VERSION "HINBNNNYYNNNYYNNNNNNNNNNNNYNNNYYYNNYNNNNNN/4//%%/4/'%**4NNN///"

NS_ :

BS_:

BU_: VirtualNMTMaster BMS_5_1 BMS_4_1 BMS_3_1 BMS_2_1 BMS_1_1 BMS_0_1 BMS_5_0 BMS_4_0 BMS_3_0 BMS_2_0 BMS_1_0 BMS_0_0 IMU PVC Thermocouple TMS MC

BO_ 1827 HBGuard_035: 1 BMS_5_1
 SG_ Toggle : 7|1@1+ (1,0) [0|0] "" Vector__XXX
 SG_ State : 0|7@1+ (1,0) [0|0] "" Vector__XXX

BO_ 1443 SSDO_035: 8 BMS_5_1
 SG_ SCS M : 5|3@1+ (1,0) [0|6] "" Vector__XXX

BO_ 1571 CSDO_035: 8 Vector__XXX
 SG_ CCS M : 5|3@1+ (1,0) [0|6] ""  BMS_5_1

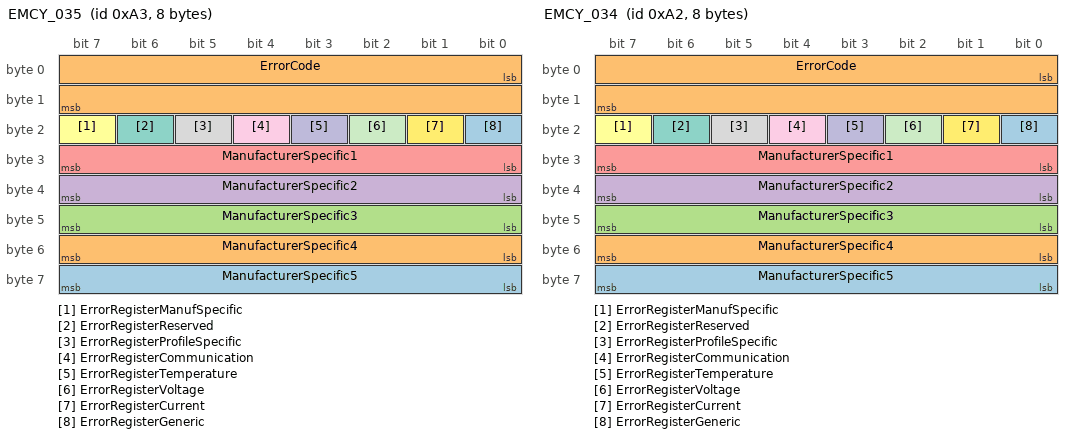
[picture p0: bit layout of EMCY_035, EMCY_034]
BO_ 163 EMCY_035: 8 BMS_5_1
 SG_ ManufacturerSpecific5 : 56|8@1+ (1,0) [0|0] "" Vector__XXX
 SG_ ManufacturerSpecific4 : 48|8@1+ (1,0) [0|0] "" Vector__XXX
 SG_ ManufacturerSpecific3 : 40|8@1+ (1,0) [0|0] "" Vector__XXX
 SG_ ManufacturerSpecific2 : 32|8@1+ (1,0) [0|0] "" Vector__XXX
 SG_ ManufacturerSpecific1 : 24|8@1+ (1,0) [0|0] "" Vector__XXX
 SG_ ErrorRegisterManufSpecific : 23|1@1+ (1,0) [0|0] "" Vector__XXX
 SG_ ErrorRegisterReserved : 22|1@1+ (1,0) [0|0] "" Vector__XXX
 SG_ ErrorRegisterProfileSpecific : 21|1@1+ (1,0) [0|0] "" Vector__XXX
 SG_ ErrorRegisterCommunication : 20|1@1+ (1,0) [0|0] "" Vector__XXX
 SG_ ErrorRegisterTemperature : 19|1@1+ (1,0) [0|0] "" Vector__XXX
 SG_ ErrorRegisterVoltage : 18|1@1+ (1,0) [0|0] "" Vector__XXX
 SG_ ErrorRegisterCurrent : 17|1@1+ (1,0) [0|0] "" Vector__XXX
 SG_ ErrorRegisterGeneric : 16|1@1+ (1,0) [0|0] "" Vector__XXX
 SG_ ErrorCode : 0|16@1+ (1,0) [0|0] "" Vector__XXX

BO_ 1826 HBGuard_034: 1 BMS_4_1
 SG_ Toggle : 7|1@1+ (1,0) [0|0] "" Vector__XXX
 SG_ State : 0|7@1+ (1,0) [0|0] "" Vector__XXX

BO_ 1442 SSDO_034: 8 BMS_4_1
 SG_ SCS M : 5|3@1+ (1,0) [0|6] "" Vector__XXX

BO_ 1570 CSDO_034: 8 Vector__XXX
 SG_ CCS M : 5|3@1+ (1,0) [0|6] ""  BMS_4_1

BO_ 162 EMCY_034: 8 BMS_4_1
 SG_ ManufacturerSpecific5 : 56|8@1+ (1,0) [0|0] "" Vector__XXX
 SG_ ManufacturerSpecific4 : 48|8@1+ (1,0) [0|0] "" Vector__XXX
 SG_ ManufacturerSpecific3 : 40|8@1+ (1,0) [0|0] "" Vector__XXX
 SG_ ManufacturerSpecific2 : 32|8@1+ (1,0) [0|0] "" Vector__XXX
 SG_ ManufacturerSpecific1 : 24|8@1+ (1,0) [0|0] "" Vector__XXX
 SG_ ErrorRegisterManufSpecific : 23|1@1+ (1,0) [0|0] "" Vector__XXX
 SG_ ErrorRegisterReserved : 22|1@1+ (1,0) [0|0] "" Vector__XXX
 SG_ ErrorRegisterProfileSpecific : 21|1@1+ (1,0) [0|0] "" Vector__XXX
 SG_ ErrorRegisterCommunication : 20|1@1+ (1,0) [0|0] "" Vector__XXX
 SG_ ErrorRegisterTemperature : 19|1@1+ (1,0) [0|0] "" Vector__XXX
 SG_ ErrorRegisterVoltage : 18|1@1+ (1,0) [0|0] "" Vector__XXX
 SG_ ErrorRegisterCurrent : 17|1@1+ (1,0) [0|0] "" Vector__XXX
 SG_ ErrorRegisterGeneric : 16|1@1+ (1,0) [0|0] "" Vector__XXX
 SG_ ErrorCode : 0|16@1+ (1,0) [0|0] "" Vector__XXX

BO_ 1825 HBGuard_033: 1 BMS_3_1
 SG_ Toggle : 7|1@1+ (1,0) [0|0] "" Vector__XXX
 SG_ State : 0|7@1+ (1,0) [0|0] "" Vector__XXX

BO_ 1441 SSDO_033: 8 BMS_3_1
 SG_ SCS M : 5|3@1+ (1,0) [0|6] "" Vector__XXX

BO_ 1569 CSDO_033: 8 Vector__XXX
 SG_ CCS M : 5|3@1+ (1,0) [0|6] ""  BMS_3_1

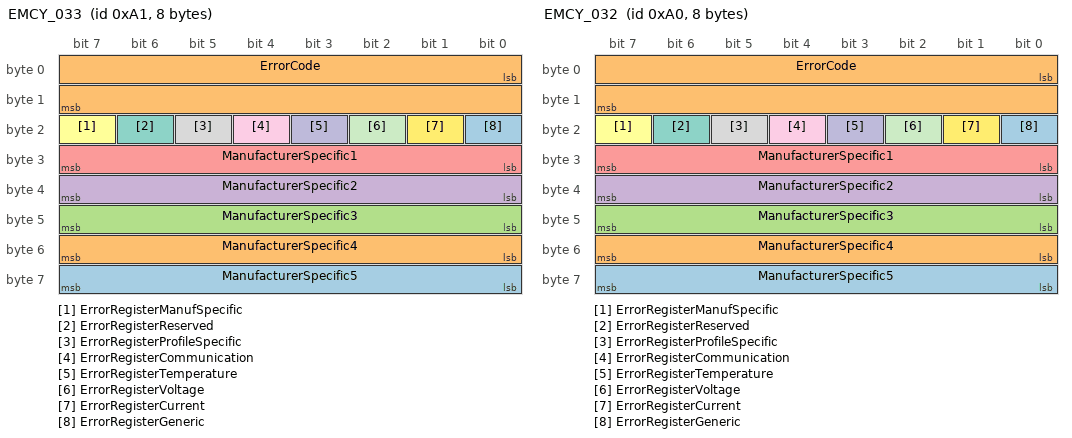
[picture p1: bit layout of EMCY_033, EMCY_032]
BO_ 161 EMCY_033: 8 BMS_3_1
 SG_ ManufacturerSpecific5 : 56|8@1+ (1,0) [0|0] "" Vector__XXX
 SG_ ManufacturerSpecific4 : 48|8@1+ (1,0) [0|0] "" Vector__XXX
 SG_ ManufacturerSpecific3 : 40|8@1+ (1,0) [0|0] "" Vector__XXX
 SG_ ManufacturerSpecific2 : 32|8@1+ (1,0) [0|0] "" Vector__XXX
 SG_ ManufacturerSpecific1 : 24|8@1+ (1,0) [0|0] "" Vector__XXX
 SG_ ErrorRegisterManufSpecific : 23|1@1+ (1,0) [0|0] "" Vector__XXX
 SG_ ErrorRegisterReserved : 22|1@1+ (1,0) [0|0] "" Vector__XXX
 SG_ ErrorRegisterProfileSpecific : 21|1@1+ (1,0) [0|0] "" Vector__XXX
 SG_ ErrorRegisterCommunication : 20|1@1+ (1,0) [0|0] "" Vector__XXX
 SG_ ErrorRegisterTemperature : 19|1@1+ (1,0) [0|0] "" Vector__XXX
 SG_ ErrorRegisterVoltage : 18|1@1+ (1,0) [0|0] "" Vector__XXX
 SG_ ErrorRegisterCurrent : 17|1@1+ (1,0) [0|0] "" Vector__XXX
 SG_ ErrorRegisterGeneric : 16|1@1+ (1,0) [0|0] "" Vector__XXX
 SG_ ErrorCode : 0|16@1+ (1,0) [0|0] "" Vector__XXX

BO_ 1824 HBGuard_032: 1 BMS_2_1
 SG_ Toggle : 7|1@1+ (1,0) [0|0] "" Vector__XXX
 SG_ State : 0|7@1+ (1,0) [0|0] "" Vector__XXX

BO_ 1440 SSDO_032: 8 BMS_2_1
 SG_ SCS M : 5|3@1+ (1,0) [0|6] "" Vector__XXX

BO_ 1568 CSDO_032: 8 Vector__XXX
 SG_ CCS M : 5|3@1+ (1,0) [0|6] ""  BMS_2_1

BO_ 160 EMCY_032: 8 BMS_2_1
 SG_ ManufacturerSpecific5 : 56|8@1+ (1,0) [0|0] "" Vector__XXX
 SG_ ManufacturerSpecific4 : 48|8@1+ (1,0) [0|0] "" Vector__XXX
 SG_ ManufacturerSpecific3 : 40|8@1+ (1,0) [0|0] "" Vector__XXX
 SG_ ManufacturerSpecific2 : 32|8@1+ (1,0) [0|0] "" Vector__XXX
 SG_ ManufacturerSpecific1 : 24|8@1+ (1,0) [0|0] "" Vector__XXX
 SG_ ErrorRegisterManufSpecific : 23|1@1+ (1,0) [0|0] "" Vector__XXX
 SG_ ErrorRegisterReserved : 22|1@1+ (1,0) [0|0] "" Vector__XXX
 SG_ ErrorRegisterProfileSpecific : 21|1@1+ (1,0) [0|0] "" Vector__XXX
 SG_ ErrorRegisterCommunication : 20|1@1+ (1,0) [0|0] "" Vector__XXX
 SG_ ErrorRegisterTemperature : 19|1@1+ (1,0) [0|0] "" Vector__XXX
 SG_ ErrorRegisterVoltage : 18|1@1+ (1,0) [0|0] "" Vector__XXX
 SG_ ErrorRegisterCurrent : 17|1@1+ (1,0) [0|0] "" Vector__XXX
 SG_ ErrorRegisterGeneric : 16|1@1+ (1,0) [0|0] "" Vector__XXX
 SG_ ErrorCode : 0|16@1+ (1,0) [0|0] "" Vector__XXX

BO_ 1823 HBGuard_031: 1 BMS_1_1
 SG_ Toggle : 7|1@1+ (1,0) [0|0] "" Vector__XXX
 SG_ State : 0|7@1+ (1,0) [0|0] "" Vector__XXX

BO_ 1439 SSDO_031: 8 BMS_1_1
 SG_ SCS M : 5|3@1+ (1,0) [0|6] "" Vector__XXX

BO_ 1567 CSDO_031: 8 Vector__XXX
 SG_ CCS M : 5|3@1+ (1,0) [0|6] ""  BMS_1_1

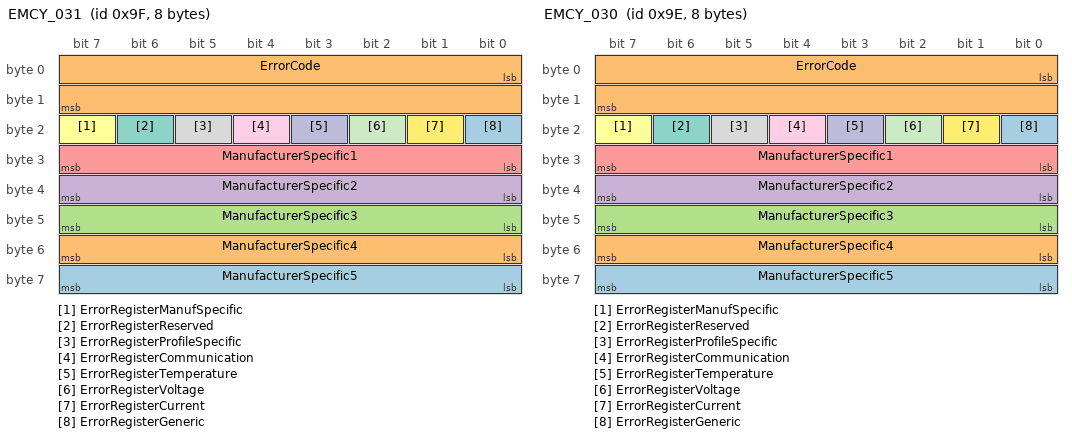
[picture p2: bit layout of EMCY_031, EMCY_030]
BO_ 159 EMCY_031: 8 BMS_1_1
 SG_ ManufacturerSpecific5 : 56|8@1+ (1,0) [0|0] "" Vector__XXX
 SG_ ManufacturerSpecific4 : 48|8@1+ (1,0) [0|0] "" Vector__XXX
 SG_ ManufacturerSpecific3 : 40|8@1+ (1,0) [0|0] "" Vector__XXX
 SG_ ManufacturerSpecific2 : 32|8@1+ (1,0) [0|0] "" Vector__XXX
 SG_ ManufacturerSpecific1 : 24|8@1+ (1,0) [0|0] "" Vector__XXX
 SG_ ErrorRegisterManufSpecific : 23|1@1+ (1,0) [0|0] "" Vector__XXX
 SG_ ErrorRegisterReserved : 22|1@1+ (1,0) [0|0] "" Vector__XXX
 SG_ ErrorRegisterProfileSpecific : 21|1@1+ (1,0) [0|0] "" Vector__XXX
 SG_ ErrorRegisterCommunication : 20|1@1+ (1,0) [0|0] "" Vector__XXX
 SG_ ErrorRegisterTemperature : 19|1@1+ (1,0) [0|0] "" Vector__XXX
 SG_ ErrorRegisterVoltage : 18|1@1+ (1,0) [0|0] "" Vector__XXX
 SG_ ErrorRegisterCurrent : 17|1@1+ (1,0) [0|0] "" Vector__XXX
 SG_ ErrorRegisterGeneric : 16|1@1+ (1,0) [0|0] "" Vector__XXX
 SG_ ErrorCode : 0|16@1+ (1,0) [0|0] "" Vector__XXX

BO_ 1822 HBGuard_030: 1 BMS_0_1
 SG_ Toggle : 7|1@1+ (1,0) [0|0] "" Vector__XXX
 SG_ State : 0|7@1+ (1,0) [0|0] "" Vector__XXX

BO_ 1438 SSDO_030: 8 BMS_0_1
 SG_ SCS M : 5|3@1+ (1,0) [0|6] "" Vector__XXX

BO_ 1566 CSDO_030: 8 Vector__XXX
 SG_ CCS M : 5|3@1+ (1,0) [0|6] ""  BMS_0_1

BO_ 158 EMCY_030: 8 BMS_0_1
 SG_ ManufacturerSpecific5 : 56|8@1+ (1,0) [0|0] "" Vector__XXX
 SG_ ManufacturerSpecific4 : 48|8@1+ (1,0) [0|0] "" Vector__XXX
 SG_ ManufacturerSpecific3 : 40|8@1+ (1,0) [0|0] "" Vector__XXX
 SG_ ManufacturerSpecific2 : 32|8@1+ (1,0) [0|0] "" Vector__XXX
 SG_ ManufacturerSpecific1 : 24|8@1+ (1,0) [0|0] "" Vector__XXX
 SG_ ErrorRegisterManufSpecific : 23|1@1+ (1,0) [0|0] "" Vector__XXX
 SG_ ErrorRegisterReserved : 22|1@1+ (1,0) [0|0] "" Vector__XXX
 SG_ ErrorRegisterProfileSpecific : 21|1@1+ (1,0) [0|0] "" Vector__XXX
 SG_ ErrorRegisterCommunication : 20|1@1+ (1,0) [0|0] "" Vector__XXX
 SG_ ErrorRegisterTemperature : 19|1@1+ (1,0) [0|0] "" Vector__XXX
 SG_ ErrorRegisterVoltage : 18|1@1+ (1,0) [0|0] "" Vector__XXX
 SG_ ErrorRegisterCurrent : 17|1@1+ (1,0) [0|0] "" Vector__XXX
 SG_ ErrorRegisterGeneric : 16|1@1+ (1,0) [0|0] "" Vector__XXX
 SG_ ErrorCode : 0|16@1+ (1,0) [0|0] "" Vector__XXX

BO_ 1817 HBGuard_025: 1 BMS_5_0
 SG_ Toggle : 7|1@1+ (1,0) [0|0] "" Vector__XXX
 SG_ State : 0|7@1+ (1,0) [0|0] "" Vector__XXX

BO_ 1433 SSDO_025: 8 BMS_5_0
 SG_ SCS M : 5|3@1+ (1,0) [0|6] "" Vector__XXX

BO_ 1561 CSDO_025: 8 Vector__XXX
 SG_ CCS M : 5|3@1+ (1,0) [0|6] ""  BMS_5_0

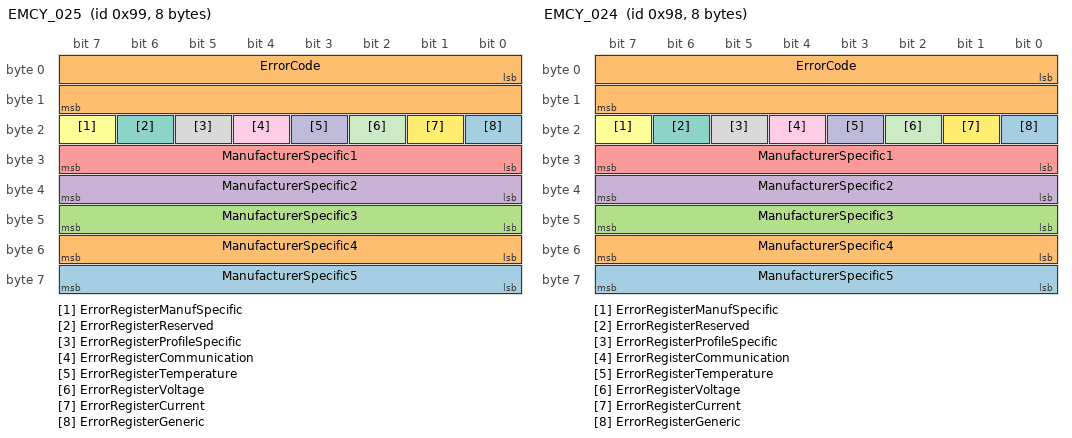
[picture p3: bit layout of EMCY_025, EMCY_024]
BO_ 153 EMCY_025: 8 BMS_5_0
 SG_ ManufacturerSpecific5 : 56|8@1+ (1,0) [0|0] "" Vector__XXX
 SG_ ManufacturerSpecific4 : 48|8@1+ (1,0) [0|0] "" Vector__XXX
 SG_ ManufacturerSpecific3 : 40|8@1+ (1,0) [0|0] "" Vector__XXX
 SG_ ManufacturerSpecific2 : 32|8@1+ (1,0) [0|0] "" Vector__XXX
 SG_ ManufacturerSpecific1 : 24|8@1+ (1,0) [0|0] "" Vector__XXX
 SG_ ErrorRegisterManufSpecific : 23|1@1+ (1,0) [0|0] "" Vector__XXX
 SG_ ErrorRegisterReserved : 22|1@1+ (1,0) [0|0] "" Vector__XXX
 SG_ ErrorRegisterProfileSpecific : 21|1@1+ (1,0) [0|0] "" Vector__XXX
 SG_ ErrorRegisterCommunication : 20|1@1+ (1,0) [0|0] "" Vector__XXX
 SG_ ErrorRegisterTemperature : 19|1@1+ (1,0) [0|0] "" Vector__XXX
 SG_ ErrorRegisterVoltage : 18|1@1+ (1,0) [0|0] "" Vector__XXX
 SG_ ErrorRegisterCurrent : 17|1@1+ (1,0) [0|0] "" Vector__XXX
 SG_ ErrorRegisterGeneric : 16|1@1+ (1,0) [0|0] "" Vector__XXX
 SG_ ErrorCode : 0|16@1+ (1,0) [0|0] "" Vector__XXX

BO_ 1816 HBGuard_024: 1 BMS_4_0
 SG_ Toggle : 7|1@1+ (1,0) [0|0] "" Vector__XXX
 SG_ State : 0|7@1+ (1,0) [0|0] "" Vector__XXX

BO_ 1432 SSDO_024: 8 BMS_4_0
 SG_ SCS M : 5|3@1+ (1,0) [0|6] "" Vector__XXX

BO_ 1560 CSDO_024: 8 Vector__XXX
 SG_ CCS M : 5|3@1+ (1,0) [0|6] ""  BMS_4_0

BO_ 152 EMCY_024: 8 BMS_4_0
 SG_ ManufacturerSpecific5 : 56|8@1+ (1,0) [0|0] "" Vector__XXX
 SG_ ManufacturerSpecific4 : 48|8@1+ (1,0) [0|0] "" Vector__XXX
 SG_ ManufacturerSpecific3 : 40|8@1+ (1,0) [0|0] "" Vector__XXX
 SG_ ManufacturerSpecific2 : 32|8@1+ (1,0) [0|0] "" Vector__XXX
 SG_ ManufacturerSpecific1 : 24|8@1+ (1,0) [0|0] "" Vector__XXX
 SG_ ErrorRegisterManufSpecific : 23|1@1+ (1,0) [0|0] "" Vector__XXX
 SG_ ErrorRegisterReserved : 22|1@1+ (1,0) [0|0] "" Vector__XXX
 SG_ ErrorRegisterProfileSpecific : 21|1@1+ (1,0) [0|0] "" Vector__XXX
 SG_ ErrorRegisterCommunication : 20|1@1+ (1,0) [0|0] "" Vector__XXX
 SG_ ErrorRegisterTemperature : 19|1@1+ (1,0) [0|0] "" Vector__XXX
 SG_ ErrorRegisterVoltage : 18|1@1+ (1,0) [0|0] "" Vector__XXX
 SG_ ErrorRegisterCurrent : 17|1@1+ (1,0) [0|0] "" Vector__XXX
 SG_ ErrorRegisterGeneric : 16|1@1+ (1,0) [0|0] "" Vector__XXX
 SG_ ErrorCode : 0|16@1+ (1,0) [0|0] "" Vector__XXX

BO_ 1815 HBGuard_023: 1 BMS_3_0
 SG_ Toggle : 7|1@1+ (1,0) [0|0] "" Vector__XXX
 SG_ State : 0|7@1+ (1,0) [0|0] "" Vector__XXX

BO_ 1431 SSDO_023: 8 BMS_3_0
 SG_ SCS M : 5|3@1+ (1,0) [0|6] "" Vector__XXX

BO_ 1559 CSDO_023: 8 Vector__XXX
 SG_ CCS M : 5|3@1+ (1,0) [0|6] ""  BMS_3_0

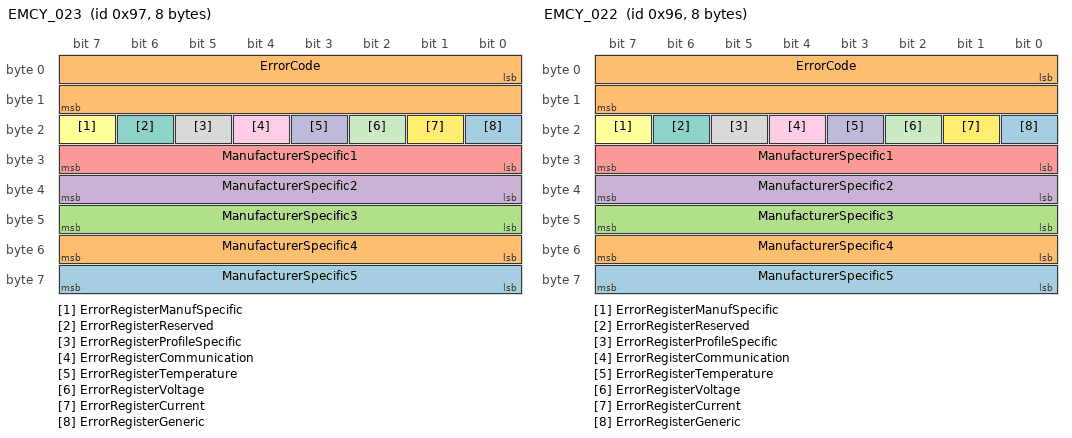
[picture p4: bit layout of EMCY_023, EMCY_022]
BO_ 151 EMCY_023: 8 BMS_3_0
 SG_ ManufacturerSpecific5 : 56|8@1+ (1,0) [0|0] "" Vector__XXX
 SG_ ManufacturerSpecific4 : 48|8@1+ (1,0) [0|0] "" Vector__XXX
 SG_ ManufacturerSpecific3 : 40|8@1+ (1,0) [0|0] "" Vector__XXX
 SG_ ManufacturerSpecific2 : 32|8@1+ (1,0) [0|0] "" Vector__XXX
 SG_ ManufacturerSpecific1 : 24|8@1+ (1,0) [0|0] "" Vector__XXX
 SG_ ErrorRegisterManufSpecific : 23|1@1+ (1,0) [0|0] "" Vector__XXX
 SG_ ErrorRegisterReserved : 22|1@1+ (1,0) [0|0] "" Vector__XXX
 SG_ ErrorRegisterProfileSpecific : 21|1@1+ (1,0) [0|0] "" Vector__XXX
 SG_ ErrorRegisterCommunication : 20|1@1+ (1,0) [0|0] "" Vector__XXX
 SG_ ErrorRegisterTemperature : 19|1@1+ (1,0) [0|0] "" Vector__XXX
 SG_ ErrorRegisterVoltage : 18|1@1+ (1,0) [0|0] "" Vector__XXX
 SG_ ErrorRegisterCurrent : 17|1@1+ (1,0) [0|0] "" Vector__XXX
 SG_ ErrorRegisterGeneric : 16|1@1+ (1,0) [0|0] "" Vector__XXX
 SG_ ErrorCode : 0|16@1+ (1,0) [0|0] "" Vector__XXX

BO_ 1814 HBGuard_022: 1 BMS_2_0
 SG_ Toggle : 7|1@1+ (1,0) [0|0] "" Vector__XXX
 SG_ State : 0|7@1+ (1,0) [0|0] "" Vector__XXX

BO_ 1430 SSDO_022: 8 BMS_2_0
 SG_ SCS M : 5|3@1+ (1,0) [0|6] "" Vector__XXX

BO_ 1558 CSDO_022: 8 Vector__XXX
 SG_ CCS M : 5|3@1+ (1,0) [0|6] ""  BMS_2_0

BO_ 150 EMCY_022: 8 BMS_2_0
 SG_ ManufacturerSpecific5 : 56|8@1+ (1,0) [0|0] "" Vector__XXX
 SG_ ManufacturerSpecific4 : 48|8@1+ (1,0) [0|0] "" Vector__XXX
 SG_ ManufacturerSpecific3 : 40|8@1+ (1,0) [0|0] "" Vector__XXX
 SG_ ManufacturerSpecific2 : 32|8@1+ (1,0) [0|0] "" Vector__XXX
 SG_ ManufacturerSpecific1 : 24|8@1+ (1,0) [0|0] "" Vector__XXX
 SG_ ErrorRegisterManufSpecific : 23|1@1+ (1,0) [0|0] "" Vector__XXX
 SG_ ErrorRegisterReserved : 22|1@1+ (1,0) [0|0] "" Vector__XXX
 SG_ ErrorRegisterProfileSpecific : 21|1@1+ (1,0) [0|0] "" Vector__XXX
 SG_ ErrorRegisterCommunication : 20|1@1+ (1,0) [0|0] "" Vector__XXX
 SG_ ErrorRegisterTemperature : 19|1@1+ (1,0) [0|0] "" Vector__XXX
 SG_ ErrorRegisterVoltage : 18|1@1+ (1,0) [0|0] "" Vector__XXX
 SG_ ErrorRegisterCurrent : 17|1@1+ (1,0) [0|0] "" Vector__XXX
 SG_ ErrorRegisterGeneric : 16|1@1+ (1,0) [0|0] "" Vector__XXX
 SG_ ErrorCode : 0|16@1+ (1,0) [0|0] "" Vector__XXX

BO_ 1813 HBGuard_021: 1 BMS_1_0
 SG_ Toggle : 7|1@1+ (1,0) [0|0] "" Vector__XXX
 SG_ State : 0|7@1+ (1,0) [0|0] "" Vector__XXX

BO_ 1429 SSDO_021: 8 BMS_1_0
 SG_ SCS M : 5|3@1+ (1,0) [0|6] "" Vector__XXX

BO_ 1557 CSDO_021: 8 Vector__XXX
 SG_ CCS M : 5|3@1+ (1,0) [0|6] ""  BMS_1_0

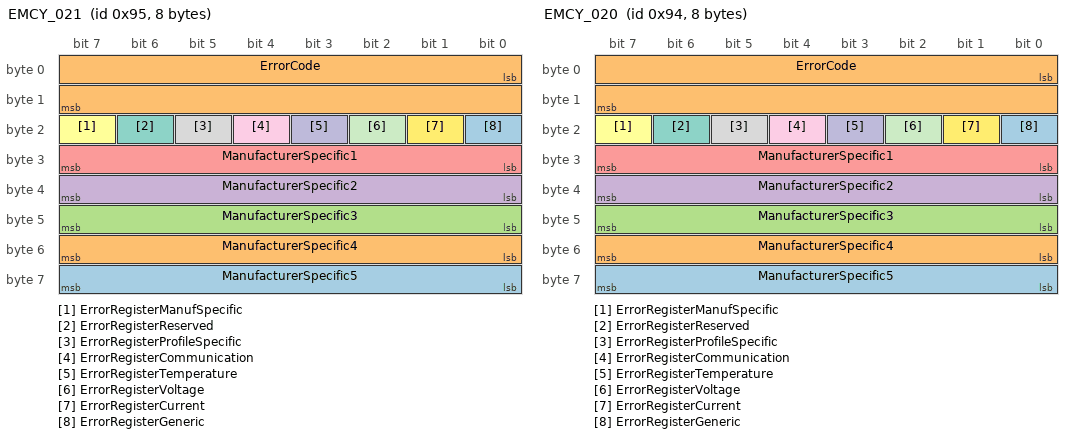
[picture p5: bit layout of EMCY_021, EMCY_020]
BO_ 149 EMCY_021: 8 BMS_1_0
 SG_ ManufacturerSpecific5 : 56|8@1+ (1,0) [0|0] "" Vector__XXX
 SG_ ManufacturerSpecific4 : 48|8@1+ (1,0) [0|0] "" Vector__XXX
 SG_ ManufacturerSpecific3 : 40|8@1+ (1,0) [0|0] "" Vector__XXX
 SG_ ManufacturerSpecific2 : 32|8@1+ (1,0) [0|0] "" Vector__XXX
 SG_ ManufacturerSpecific1 : 24|8@1+ (1,0) [0|0] "" Vector__XXX
 SG_ ErrorRegisterManufSpecific : 23|1@1+ (1,0) [0|0] "" Vector__XXX
 SG_ ErrorRegisterReserved : 22|1@1+ (1,0) [0|0] "" Vector__XXX
 SG_ ErrorRegisterProfileSpecific : 21|1@1+ (1,0) [0|0] "" Vector__XXX
 SG_ ErrorRegisterCommunication : 20|1@1+ (1,0) [0|0] "" Vector__XXX
 SG_ ErrorRegisterTemperature : 19|1@1+ (1,0) [0|0] "" Vector__XXX
 SG_ ErrorRegisterVoltage : 18|1@1+ (1,0) [0|0] "" Vector__XXX
 SG_ ErrorRegisterCurrent : 17|1@1+ (1,0) [0|0] "" Vector__XXX
 SG_ ErrorRegisterGeneric : 16|1@1+ (1,0) [0|0] "" Vector__XXX
 SG_ ErrorCode : 0|16@1+ (1,0) [0|0] "" Vector__XXX

BO_ 1812 HBGuard_020: 1 BMS_0_0
 SG_ Toggle : 7|1@1+ (1,0) [0|0] "" Vector__XXX
 SG_ State : 0|7@1+ (1,0) [0|0] "" Vector__XXX

BO_ 1428 SSDO_020: 8 BMS_0_0
 SG_ SCS M : 5|3@1+ (1,0) [0|6] "" Vector__XXX

BO_ 1556 CSDO_020: 8 Vector__XXX
 SG_ CCS M : 5|3@1+ (1,0) [0|6] ""  BMS_0_0

BO_ 148 EMCY_020: 8 BMS_0_0
 SG_ ManufacturerSpecific5 : 56|8@1+ (1,0) [0|0] "" Vector__XXX
 SG_ ManufacturerSpecific4 : 48|8@1+ (1,0) [0|0] "" Vector__XXX
 SG_ ManufacturerSpecific3 : 40|8@1+ (1,0) [0|0] "" Vector__XXX
 SG_ ManufacturerSpecific2 : 32|8@1+ (1,0) [0|0] "" Vector__XXX
 SG_ ManufacturerSpecific1 : 24|8@1+ (1,0) [0|0] "" Vector__XXX
 SG_ ErrorRegisterManufSpecific : 23|1@1+ (1,0) [0|0] "" Vector__XXX
 SG_ ErrorRegisterReserved : 22|1@1+ (1,0) [0|0] "" Vector__XXX
 SG_ ErrorRegisterProfileSpecific : 21|1@1+ (1,0) [0|0] "" Vector__XXX
 SG_ ErrorRegisterCommunication : 20|1@1+ (1,0) [0|0] "" Vector__XXX
 SG_ ErrorRegisterTemperature : 19|1@1+ (1,0) [0|0] "" Vector__XXX
 SG_ ErrorRegisterVoltage : 18|1@1+ (1,0) [0|0] "" Vector__XXX
 SG_ ErrorRegisterCurrent : 17|1@1+ (1,0) [0|0] "" Vector__XXX
 SG_ ErrorRegisterGeneric : 16|1@1+ (1,0) [0|0] "" Vector__XXX
 SG_ ErrorCode : 0|16@1+ (1,0) [0|0] "" Vector__XXX

BO_ 1809 HBGuard_017: 1 IMU
 SG_ Toggle : 7|1@1+ (1,0) [0|0] "" Vector__XXX
 SG_ State : 0|7@1+ (1,0) [0|0] "" Vector__XXX

BO_ 1425 SSDO_017: 8 IMU
 SG_ SCS M : 5|3@1+ (1,0) [0|6] "" Vector__XXX

BO_ 1553 CSDO_017: 8 Vector__XXX
 SG_ CCS M : 5|3@1+ (1,0) [0|6] ""  IMU

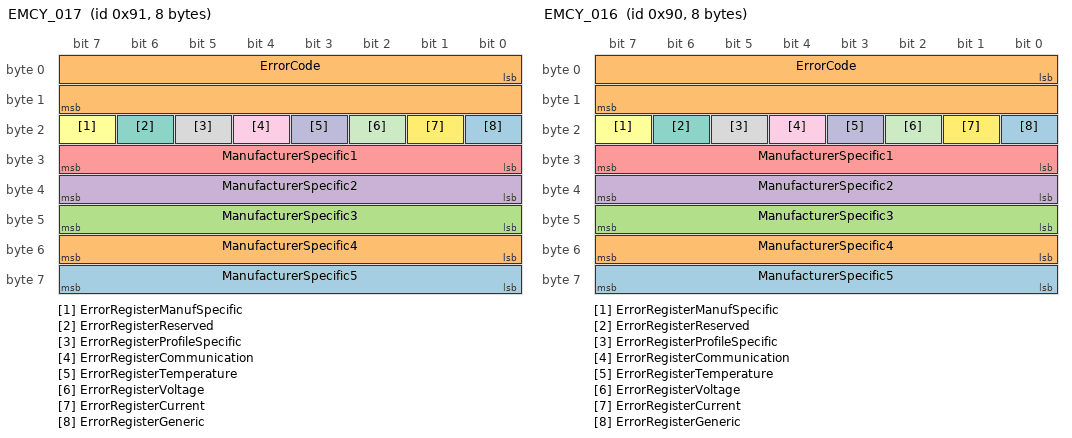
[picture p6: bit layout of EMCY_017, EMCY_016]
BO_ 145 EMCY_017: 8 IMU
 SG_ ManufacturerSpecific5 : 56|8@1+ (1,0) [0|0] "" Vector__XXX
 SG_ ManufacturerSpecific4 : 48|8@1+ (1,0) [0|0] "" Vector__XXX
 SG_ ManufacturerSpecific3 : 40|8@1+ (1,0) [0|0] "" Vector__XXX
 SG_ ManufacturerSpecific2 : 32|8@1+ (1,0) [0|0] "" Vector__XXX
 SG_ ManufacturerSpecific1 : 24|8@1+ (1,0) [0|0] "" Vector__XXX
 SG_ ErrorRegisterManufSpecific : 23|1@1+ (1,0) [0|0] "" Vector__XXX
 SG_ ErrorRegisterReserved : 22|1@1+ (1,0) [0|0] "" Vector__XXX
 SG_ ErrorRegisterProfileSpecific : 21|1@1+ (1,0) [0|0] "" Vector__XXX
 SG_ ErrorRegisterCommunication : 20|1@1+ (1,0) [0|0] "" Vector__XXX
 SG_ ErrorRegisterTemperature : 19|1@1+ (1,0) [0|0] "" Vector__XXX
 SG_ ErrorRegisterVoltage : 18|1@1+ (1,0) [0|0] "" Vector__XXX
 SG_ ErrorRegisterCurrent : 17|1@1+ (1,0) [0|0] "" Vector__XXX
 SG_ ErrorRegisterGeneric : 16|1@1+ (1,0) [0|0] "" Vector__XXX
 SG_ ErrorCode : 0|16@1+ (1,0) [0|0] "" Vector__XXX

BO_ 1808 HBGuard_016: 1 PVC
 SG_ Toggle : 7|1@1+ (1,0) [0|0] "" Vector__XXX
 SG_ State : 0|7@1+ (1,0) [0|0] "" Vector__XXX

BO_ 1424 SSDO_016: 8 PVC
 SG_ SCS M : 5|3@1+ (1,0) [0|6] "" Vector__XXX

BO_ 1552 CSDO_016: 8 Vector__XXX
 SG_ CCS M : 5|3@1+ (1,0) [0|6] ""  PVC

BO_ 144 EMCY_016: 8 PVC
 SG_ ManufacturerSpecific5 : 56|8@1+ (1,0) [0|0] "" Vector__XXX
 SG_ ManufacturerSpecific4 : 48|8@1+ (1,0) [0|0] "" Vector__XXX
 SG_ ManufacturerSpecific3 : 40|8@1+ (1,0) [0|0] "" Vector__XXX
 SG_ ManufacturerSpecific2 : 32|8@1+ (1,0) [0|0] "" Vector__XXX
 SG_ ManufacturerSpecific1 : 24|8@1+ (1,0) [0|0] "" Vector__XXX
 SG_ ErrorRegisterManufSpecific : 23|1@1+ (1,0) [0|0] "" Vector__XXX
 SG_ ErrorRegisterReserved : 22|1@1+ (1,0) [0|0] "" Vector__XXX
 SG_ ErrorRegisterProfileSpecific : 21|1@1+ (1,0) [0|0] "" Vector__XXX
 SG_ ErrorRegisterCommunication : 20|1@1+ (1,0) [0|0] "" Vector__XXX
 SG_ ErrorRegisterTemperature : 19|1@1+ (1,0) [0|0] "" Vector__XXX
 SG_ ErrorRegisterVoltage : 18|1@1+ (1,0) [0|0] "" Vector__XXX
 SG_ ErrorRegisterCurrent : 17|1@1+ (1,0) [0|0] "" Vector__XXX
 SG_ ErrorRegisterGeneric : 16|1@1+ (1,0) [0|0] "" Vector__XXX
 SG_ ErrorCode : 0|16@1+ (1,0) [0|0] "" Vector__XXX

BO_ 1801 HBGuard_009: 1 Thermocouple
 SG_ Toggle : 7|1@1+ (1,0) [0|0] "" Vector__XXX
 SG_ State : 0|7@1+ (1,0) [0|0] "" Vector__XXX

BO_ 1417 SSDO_009: 8 Thermocouple
 SG_ SCS M : 5|3@1+ (1,0) [0|6] "" Vector__XXX

BO_ 1545 CSDO_009: 8 Vector__XXX
 SG_ CCS M : 5|3@1+ (1,0) [0|6] ""  Thermocouple

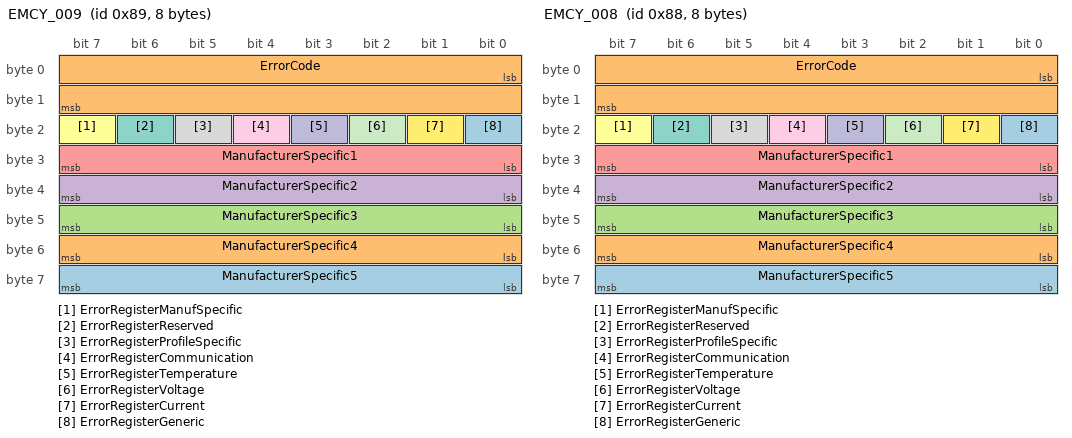
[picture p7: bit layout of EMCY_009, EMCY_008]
BO_ 137 EMCY_009: 8 Thermocouple
 SG_ ManufacturerSpecific5 : 56|8@1+ (1,0) [0|0] "" Vector__XXX
 SG_ ManufacturerSpecific4 : 48|8@1+ (1,0) [0|0] "" Vector__XXX
 SG_ ManufacturerSpecific3 : 40|8@1+ (1,0) [0|0] "" Vector__XXX
 SG_ ManufacturerSpecific2 : 32|8@1+ (1,0) [0|0] "" Vector__XXX
 SG_ ManufacturerSpecific1 : 24|8@1+ (1,0) [0|0] "" Vector__XXX
 SG_ ErrorRegisterManufSpecific : 23|1@1+ (1,0) [0|0] "" Vector__XXX
 SG_ ErrorRegisterReserved : 22|1@1+ (1,0) [0|0] "" Vector__XXX
 SG_ ErrorRegisterProfileSpecific : 21|1@1+ (1,0) [0|0] "" Vector__XXX
 SG_ ErrorRegisterCommunication : 20|1@1+ (1,0) [0|0] "" Vector__XXX
 SG_ ErrorRegisterTemperature : 19|1@1+ (1,0) [0|0] "" Vector__XXX
 SG_ ErrorRegisterVoltage : 18|1@1+ (1,0) [0|0] "" Vector__XXX
 SG_ ErrorRegisterCurrent : 17|1@1+ (1,0) [0|0] "" Vector__XXX
 SG_ ErrorRegisterGeneric : 16|1@1+ (1,0) [0|0] "" Vector__XXX
 SG_ ErrorCode : 0|16@1+ (1,0) [0|0] "" Vector__XXX

BO_ 1800 HBGuard_008: 1 TMS
 SG_ Toggle : 7|1@1+ (1,0) [0|0] "" Vector__XXX
 SG_ State : 0|7@1+ (1,0) [0|0] "" Vector__XXX

BO_ 1416 SSDO_008: 8 TMS
 SG_ SCS M : 5|3@1+ (1,0) [0|6] "" Vector__XXX

BO_ 1544 CSDO_008: 8 Vector__XXX
 SG_ CCS M : 5|3@1+ (1,0) [0|6] ""  TMS

BO_ 136 EMCY_008: 8 TMS
 SG_ ManufacturerSpecific5 : 56|8@1+ (1,0) [0|0] "" Vector__XXX
 SG_ ManufacturerSpecific4 : 48|8@1+ (1,0) [0|0] "" Vector__XXX
 SG_ ManufacturerSpecific3 : 40|8@1+ (1,0) [0|0] "" Vector__XXX
 SG_ ManufacturerSpecific2 : 32|8@1+ (1,0) [0|0] "" Vector__XXX
 SG_ ManufacturerSpecific1 : 24|8@1+ (1,0) [0|0] "" Vector__XXX
 SG_ ErrorRegisterManufSpecific : 23|1@1+ (1,0) [0|0] "" Vector__XXX
 SG_ ErrorRegisterReserved : 22|1@1+ (1,0) [0|0] "" Vector__XXX
 SG_ ErrorRegisterProfileSpecific : 21|1@1+ (1,0) [0|0] "" Vector__XXX
 SG_ ErrorRegisterCommunication : 20|1@1+ (1,0) [0|0] "" Vector__XXX
 SG_ ErrorRegisterTemperature : 19|1@1+ (1,0) [0|0] "" Vector__XXX
 SG_ ErrorRegisterVoltage : 18|1@1+ (1,0) [0|0] "" Vector__XXX
 SG_ ErrorRegisterCurrent : 17|1@1+ (1,0) [0|0] "" Vector__XXX
 SG_ ErrorRegisterGeneric : 16|1@1+ (1,0) [0|0] "" Vector__XXX
 SG_ ErrorCode : 0|16@1+ (1,0) [0|0] "" Vector__XXX

BO_ 1793 HBGuard_001: 1 MC
 SG_ Toggle : 7|1@1+ (1,0) [0|0] "" Vector__XXX
 SG_ State : 0|7@1+ (1,0) [0|0] "" Vector__XXX

BO_ 1409 SSDO_001: 8 MC
 SG_ SCS M : 5|3@1+ (1,0) [0|6] "" Vector__XXX

BO_ 1537 CSDO_001: 8 Vector__XXX
 SG_ CCS M : 5|3@1+ (1,0) [0|6] ""  MC

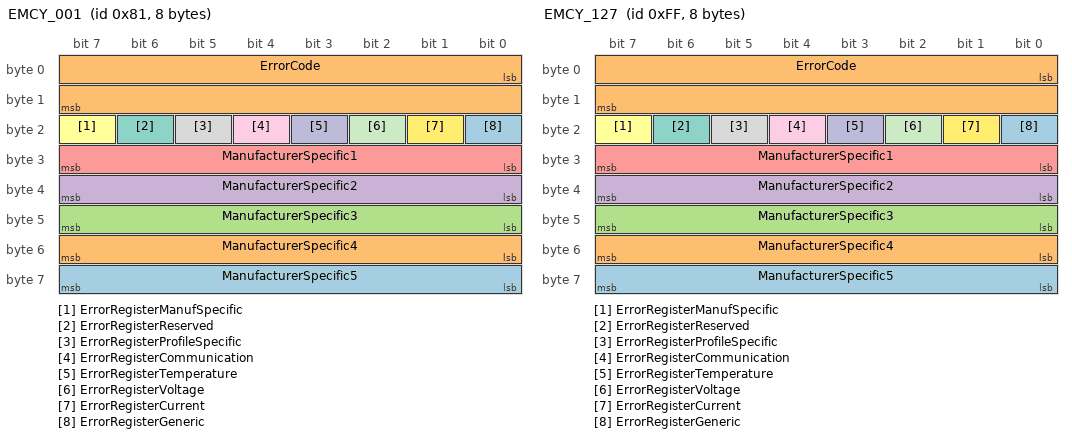
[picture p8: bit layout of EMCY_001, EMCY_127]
BO_ 129 EMCY_001: 8 MC
 SG_ ManufacturerSpecific5 : 56|8@1+ (1,0) [0|0] "" Vector__XXX
 SG_ ManufacturerSpecific4 : 48|8@1+ (1,0) [0|0] "" Vector__XXX
 SG_ ManufacturerSpecific3 : 40|8@1+ (1,0) [0|0] "" Vector__XXX
 SG_ ManufacturerSpecific2 : 32|8@1+ (1,0) [0|0] "" Vector__XXX
 SG_ ManufacturerSpecific1 : 24|8@1+ (1,0) [0|0] "" Vector__XXX
 SG_ ErrorRegisterManufSpecific : 23|1@1+ (1,0) [0|0] "" Vector__XXX
 SG_ ErrorRegisterReserved : 22|1@1+ (1,0) [0|0] "" Vector__XXX
 SG_ ErrorRegisterProfileSpecific : 21|1@1+ (1,0) [0|0] "" Vector__XXX
 SG_ ErrorRegisterCommunication : 20|1@1+ (1,0) [0|0] "" Vector__XXX
 SG_ ErrorRegisterTemperature : 19|1@1+ (1,0) [0|0] "" Vector__XXX
 SG_ ErrorRegisterVoltage : 18|1@1+ (1,0) [0|0] "" Vector__XXX
 SG_ ErrorRegisterCurrent : 17|1@1+ (1,0) [0|0] "" Vector__XXX
 SG_ ErrorRegisterGeneric : 16|1@1+ (1,0) [0|0] "" Vector__XXX
 SG_ ErrorCode : 0|16@1+ (1,0) [0|0] "" Vector__XXX

BO_ 1919 HBGuard_127: 1 Vector__XXX
 SG_ Toggle : 7|1@1+ (1,0) [0|0] "" Vector__XXX
 SG_ State : 0|7@1+ (1,0) [0|0] "" Vector__XXX

BO_ 1535 SSDO_127: 8 Vector__XXX

BO_ 1663 CSDO_127: 8 Vector__XXX

BO_ 255 EMCY_127: 8 Vector__XXX
 SG_ ManufacturerSpecific5 : 56|8@1+ (1,0) [0|0] "" Vector__XXX
 SG_ ManufacturerSpecific4 : 48|8@1+ (1,0) [0|0] "" Vector__XXX
 SG_ ManufacturerSpecific3 : 40|8@1+ (1,0) [0|0] "" Vector__XXX
 SG_ ManufacturerSpecific2 : 32|8@1+ (1,0) [0|0] "" Vector__XXX
 SG_ ManufacturerSpecific1 : 24|8@1+ (1,0) [0|0] "" Vector__XXX
 SG_ ErrorRegisterManufSpecific : 23|1@1+ (1,0) [0|0] "" Vector__XXX
 SG_ ErrorRegisterReserved : 22|1@1+ (1,0) [0|0] "" Vector__XXX
 SG_ ErrorRegisterProfileSpecific : 21|1@1+ (1,0) [0|0] "" Vector__XXX
 SG_ ErrorRegisterCommunication : 20|1@1+ (1,0) [0|0] "" Vector__XXX
 SG_ ErrorRegisterTemperature : 19|1@1+ (1,0) [0|0] "" Vector__XXX
 SG_ ErrorRegisterVoltage : 18|1@1+ (1,0) [0|0] "" Vector__XXX
 SG_ ErrorRegisterCurrent : 17|1@1+ (1,0) [0|0] "" Vector__XXX
 SG_ ErrorRegisterGeneric : 16|1@1+ (1,0) [0|0] "" Vector__XXX
 SG_ ErrorCode : 0|16@1+ (1,0) [0|0] "" Vector__XXX

BO_ 1918 HBGuard_126: 1 Vector__XXX
 SG_ Toggle : 7|1@1+ (1,0) [0|0] "" Vector__XXX
 SG_ State : 0|7@1+ (1,0) [0|0] "" Vector__XXX

BO_ 1534 SSDO_126: 8 Vector__XXX

BO_ 1662 CSDO_126: 8 Vector__XXX

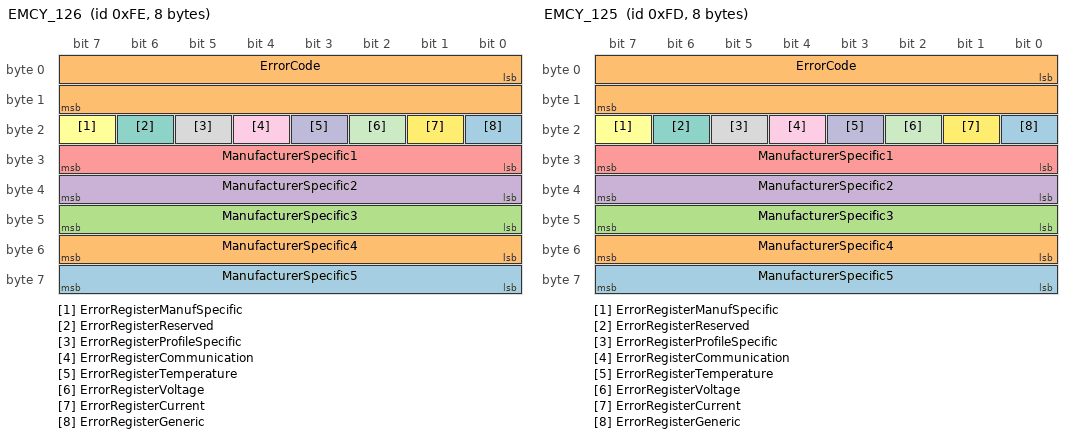
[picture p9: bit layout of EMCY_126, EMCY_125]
BO_ 254 EMCY_126: 8 Vector__XXX
 SG_ ManufacturerSpecific5 : 56|8@1+ (1,0) [0|0] "" Vector__XXX
 SG_ ManufacturerSpecific4 : 48|8@1+ (1,0) [0|0] "" Vector__XXX
 SG_ ManufacturerSpecific3 : 40|8@1+ (1,0) [0|0] "" Vector__XXX
 SG_ ManufacturerSpecific2 : 32|8@1+ (1,0) [0|0] "" Vector__XXX
 SG_ ManufacturerSpecific1 : 24|8@1+ (1,0) [0|0] "" Vector__XXX
 SG_ ErrorRegisterManufSpecific : 23|1@1+ (1,0) [0|0] "" Vector__XXX
 SG_ ErrorRegisterReserved : 22|1@1+ (1,0) [0|0] "" Vector__XXX
 SG_ ErrorRegisterProfileSpecific : 21|1@1+ (1,0) [0|0] "" Vector__XXX
 SG_ ErrorRegisterCommunication : 20|1@1+ (1,0) [0|0] "" Vector__XXX
 SG_ ErrorRegisterTemperature : 19|1@1+ (1,0) [0|0] "" Vector__XXX
 SG_ ErrorRegisterVoltage : 18|1@1+ (1,0) [0|0] "" Vector__XXX
 SG_ ErrorRegisterCurrent : 17|1@1+ (1,0) [0|0] "" Vector__XXX
 SG_ ErrorRegisterGeneric : 16|1@1+ (1,0) [0|0] "" Vector__XXX
 SG_ ErrorCode : 0|16@1+ (1,0) [0|0] "" Vector__XXX

BO_ 1917 HBGuard_125: 1 Vector__XXX
 SG_ Toggle : 7|1@1+ (1,0) [0|0] "" Vector__XXX
 SG_ State : 0|7@1+ (1,0) [0|0] "" Vector__XXX

BO_ 1533 SSDO_125: 8 Vector__XXX

BO_ 1661 CSDO_125: 8 Vector__XXX

BO_ 253 EMCY_125: 8 Vector__XXX
 SG_ ManufacturerSpecific5 : 56|8@1+ (1,0) [0|0] "" Vector__XXX
 SG_ ManufacturerSpecific4 : 48|8@1+ (1,0) [0|0] "" Vector__XXX
 SG_ ManufacturerSpecific3 : 40|8@1+ (1,0) [0|0] "" Vector__XXX
 SG_ ManufacturerSpecific2 : 32|8@1+ (1,0) [0|0] "" Vector__XXX
 SG_ ManufacturerSpecific1 : 24|8@1+ (1,0) [0|0] "" Vector__XXX
 SG_ ErrorRegisterManufSpecific : 23|1@1+ (1,0) [0|0] "" Vector__XXX
 SG_ ErrorRegisterReserved : 22|1@1+ (1,0) [0|0] "" Vector__XXX
 SG_ ErrorRegisterProfileSpecific : 21|1@1+ (1,0) [0|0] "" Vector__XXX
 SG_ ErrorRegisterCommunication : 20|1@1+ (1,0) [0|0] "" Vector__XXX
 SG_ ErrorRegisterTemperature : 19|1@1+ (1,0) [0|0] "" Vector__XXX
 SG_ ErrorRegisterVoltage : 18|1@1+ (1,0) [0|0] "" Vector__XXX
 SG_ ErrorRegisterCurrent : 17|1@1+ (1,0) [0|0] "" Vector__XXX
 SG_ ErrorRegisterGeneric : 16|1@1+ (1,0) [0|0] "" Vector__XXX
 SG_ ErrorCode : 0|16@1+ (1,0) [0|0] "" Vector__XXX

BO_ 1916 HBGuard_124: 1 Vector__XXX
 SG_ Toggle : 7|1@1+ (1,0) [0|0] "" Vector__XXX
 SG_ State : 0|7@1+ (1,0) [0|0] "" Vector__XXX

BO_ 1532 SSDO_124: 8 Vector__XXX

BO_ 1660 CSDO_124: 8 Vector__XXX

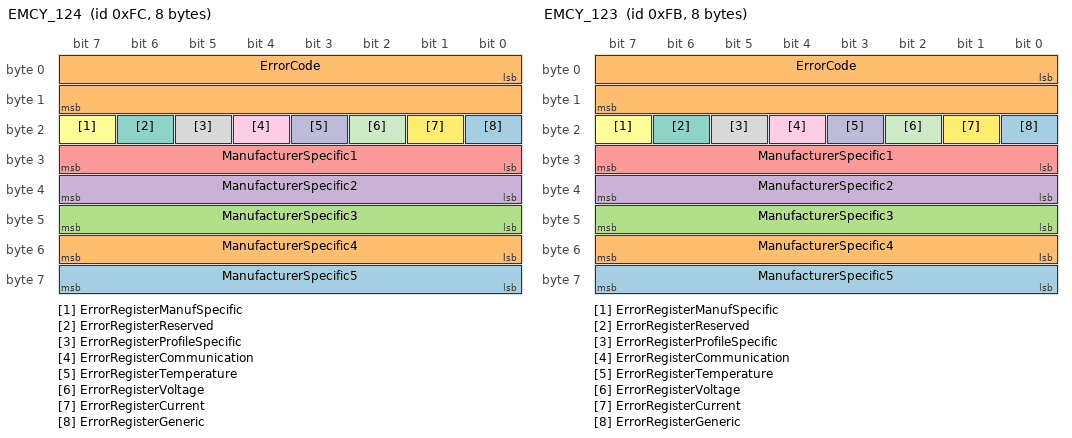
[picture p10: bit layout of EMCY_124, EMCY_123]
BO_ 252 EMCY_124: 8 Vector__XXX
 SG_ ManufacturerSpecific5 : 56|8@1+ (1,0) [0|0] "" Vector__XXX
 SG_ ManufacturerSpecific4 : 48|8@1+ (1,0) [0|0] "" Vector__XXX
 SG_ ManufacturerSpecific3 : 40|8@1+ (1,0) [0|0] "" Vector__XXX
 SG_ ManufacturerSpecific2 : 32|8@1+ (1,0) [0|0] "" Vector__XXX
 SG_ ManufacturerSpecific1 : 24|8@1+ (1,0) [0|0] "" Vector__XXX
 SG_ ErrorRegisterManufSpecific : 23|1@1+ (1,0) [0|0] "" Vector__XXX
 SG_ ErrorRegisterReserved : 22|1@1+ (1,0) [0|0] "" Vector__XXX
 SG_ ErrorRegisterProfileSpecific : 21|1@1+ (1,0) [0|0] "" Vector__XXX
 SG_ ErrorRegisterCommunication : 20|1@1+ (1,0) [0|0] "" Vector__XXX
 SG_ ErrorRegisterTemperature : 19|1@1+ (1,0) [0|0] "" Vector__XXX
 SG_ ErrorRegisterVoltage : 18|1@1+ (1,0) [0|0] "" Vector__XXX
 SG_ ErrorRegisterCurrent : 17|1@1+ (1,0) [0|0] "" Vector__XXX
 SG_ ErrorRegisterGeneric : 16|1@1+ (1,0) [0|0] "" Vector__XXX
 SG_ ErrorCode : 0|16@1+ (1,0) [0|0] "" Vector__XXX

BO_ 1915 HBGuard_123: 1 Vector__XXX
 SG_ Toggle : 7|1@1+ (1,0) [0|0] "" Vector__XXX
 SG_ State : 0|7@1+ (1,0) [0|0] "" Vector__XXX

BO_ 1531 SSDO_123: 8 Vector__XXX

BO_ 1659 CSDO_123: 8 Vector__XXX

BO_ 251 EMCY_123: 8 Vector__XXX
 SG_ ManufacturerSpecific5 : 56|8@1+ (1,0) [0|0] "" Vector__XXX
 SG_ ManufacturerSpecific4 : 48|8@1+ (1,0) [0|0] "" Vector__XXX
 SG_ ManufacturerSpecific3 : 40|8@1+ (1,0) [0|0] "" Vector__XXX
 SG_ ManufacturerSpecific2 : 32|8@1+ (1,0) [0|0] "" Vector__XXX
 SG_ ManufacturerSpecific1 : 24|8@1+ (1,0) [0|0] "" Vector__XXX
 SG_ ErrorRegisterManufSpecific : 23|1@1+ (1,0) [0|0] "" Vector__XXX
 SG_ ErrorRegisterReserved : 22|1@1+ (1,0) [0|0] "" Vector__XXX
 SG_ ErrorRegisterProfileSpecific : 21|1@1+ (1,0) [0|0] "" Vector__XXX
 SG_ ErrorRegisterCommunication : 20|1@1+ (1,0) [0|0] "" Vector__XXX
 SG_ ErrorRegisterTemperature : 19|1@1+ (1,0) [0|0] "" Vector__XXX
 SG_ ErrorRegisterVoltage : 18|1@1+ (1,0) [0|0] "" Vector__XXX
 SG_ ErrorRegisterCurrent : 17|1@1+ (1,0) [0|0] "" Vector__XXX
 SG_ ErrorRegisterGeneric : 16|1@1+ (1,0) [0|0] "" Vector__XXX
 SG_ ErrorCode : 0|16@1+ (1,0) [0|0] "" Vector__XXX

BO_ 1914 HBGuard_122: 1 Vector__XXX
 SG_ Toggle : 7|1@1+ (1,0) [0|0] "" Vector__XXX
 SG_ State : 0|7@1+ (1,0) [0|0] "" Vector__XXX

BO_ 1530 SSDO_122: 8 Vector__XXX

BO_ 1658 CSDO_122: 8 Vector__XXX

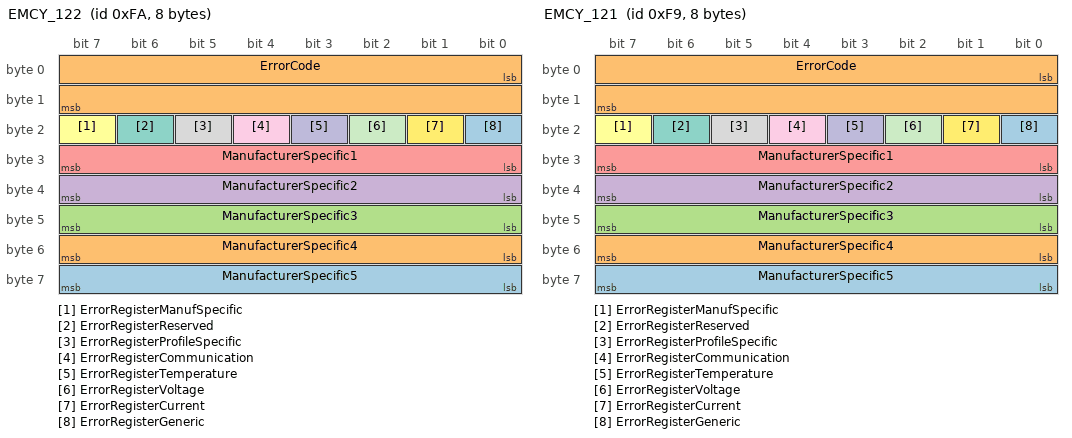
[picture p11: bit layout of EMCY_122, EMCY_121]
BO_ 250 EMCY_122: 8 Vector__XXX
 SG_ ManufacturerSpecific5 : 56|8@1+ (1,0) [0|0] "" Vector__XXX
 SG_ ManufacturerSpecific4 : 48|8@1+ (1,0) [0|0] "" Vector__XXX
 SG_ ManufacturerSpecific3 : 40|8@1+ (1,0) [0|0] "" Vector__XXX
 SG_ ManufacturerSpecific2 : 32|8@1+ (1,0) [0|0] "" Vector__XXX
 SG_ ManufacturerSpecific1 : 24|8@1+ (1,0) [0|0] "" Vector__XXX
 SG_ ErrorRegisterManufSpecific : 23|1@1+ (1,0) [0|0] "" Vector__XXX
 SG_ ErrorRegisterReserved : 22|1@1+ (1,0) [0|0] "" Vector__XXX
 SG_ ErrorRegisterProfileSpecific : 21|1@1+ (1,0) [0|0] "" Vector__XXX
 SG_ ErrorRegisterCommunication : 20|1@1+ (1,0) [0|0] "" Vector__XXX
 SG_ ErrorRegisterTemperature : 19|1@1+ (1,0) [0|0] "" Vector__XXX
 SG_ ErrorRegisterVoltage : 18|1@1+ (1,0) [0|0] "" Vector__XXX
 SG_ ErrorRegisterCurrent : 17|1@1+ (1,0) [0|0] "" Vector__XXX
 SG_ ErrorRegisterGeneric : 16|1@1+ (1,0) [0|0] "" Vector__XXX
 SG_ ErrorCode : 0|16@1+ (1,0) [0|0] "" Vector__XXX

BO_ 1913 HBGuard_121: 1 Vector__XXX
 SG_ Toggle : 7|1@1+ (1,0) [0|0] "" Vector__XXX
 SG_ State : 0|7@1+ (1,0) [0|0] "" Vector__XXX

BO_ 1529 SSDO_121: 8 Vector__XXX

BO_ 1657 CSDO_121: 8 Vector__XXX

BO_ 249 EMCY_121: 8 Vector__XXX
 SG_ ManufacturerSpecific5 : 56|8@1+ (1,0) [0|0] "" Vector__XXX
 SG_ ManufacturerSpecific4 : 48|8@1+ (1,0) [0|0] "" Vector__XXX
 SG_ ManufacturerSpecific3 : 40|8@1+ (1,0) [0|0] "" Vector__XXX
 SG_ ManufacturerSpecific2 : 32|8@1+ (1,0) [0|0] "" Vector__XXX
 SG_ ManufacturerSpecific1 : 24|8@1+ (1,0) [0|0] "" Vector__XXX
 SG_ ErrorRegisterManufSpecific : 23|1@1+ (1,0) [0|0] "" Vector__XXX
 SG_ ErrorRegisterReserved : 22|1@1+ (1,0) [0|0] "" Vector__XXX
 SG_ ErrorRegisterProfileSpecific : 21|1@1+ (1,0) [0|0] "" Vector__XXX
 SG_ ErrorRegisterCommunication : 20|1@1+ (1,0) [0|0] "" Vector__XXX
 SG_ ErrorRegisterTemperature : 19|1@1+ (1,0) [0|0] "" Vector__XXX
 SG_ ErrorRegisterVoltage : 18|1@1+ (1,0) [0|0] "" Vector__XXX
 SG_ ErrorRegisterCurrent : 17|1@1+ (1,0) [0|0] "" Vector__XXX
 SG_ ErrorRegisterGeneric : 16|1@1+ (1,0) [0|0] "" Vector__XXX
 SG_ ErrorCode : 0|16@1+ (1,0) [0|0] "" Vector__XXX

BO_ 1912 HBGuard_120: 1 Vector__XXX
 SG_ Toggle : 7|1@1+ (1,0) [0|0] "" Vector__XXX
 SG_ State : 0|7@1+ (1,0) [0|0] "" Vector__XXX

BO_ 1528 SSDO_120: 8 Vector__XXX

BO_ 1656 CSDO_120: 8 Vector__XXX

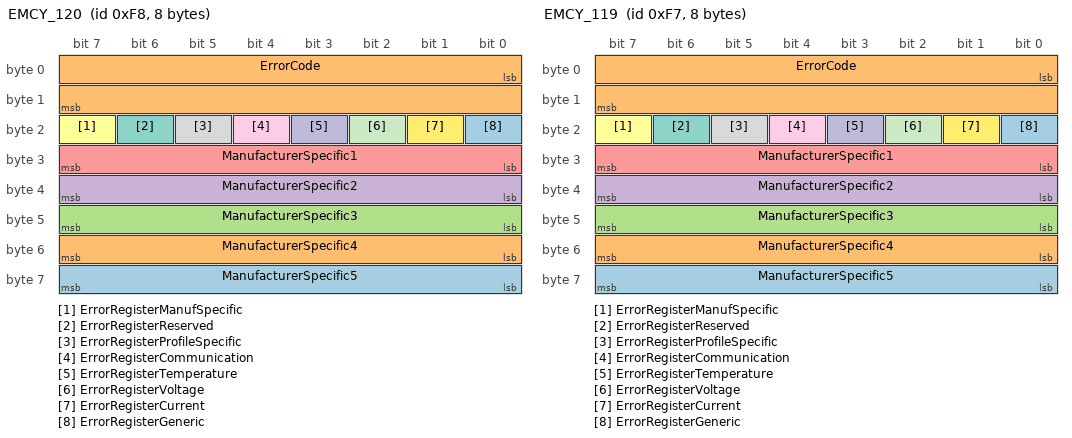
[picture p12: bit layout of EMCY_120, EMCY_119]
BO_ 248 EMCY_120: 8 Vector__XXX
 SG_ ManufacturerSpecific5 : 56|8@1+ (1,0) [0|0] "" Vector__XXX
 SG_ ManufacturerSpecific4 : 48|8@1+ (1,0) [0|0] "" Vector__XXX
 SG_ ManufacturerSpecific3 : 40|8@1+ (1,0) [0|0] "" Vector__XXX
 SG_ ManufacturerSpecific2 : 32|8@1+ (1,0) [0|0] "" Vector__XXX
 SG_ ManufacturerSpecific1 : 24|8@1+ (1,0) [0|0] "" Vector__XXX
 SG_ ErrorRegisterManufSpecific : 23|1@1+ (1,0) [0|0] "" Vector__XXX
 SG_ ErrorRegisterReserved : 22|1@1+ (1,0) [0|0] "" Vector__XXX
 SG_ ErrorRegisterProfileSpecific : 21|1@1+ (1,0) [0|0] "" Vector__XXX
 SG_ ErrorRegisterCommunication : 20|1@1+ (1,0) [0|0] "" Vector__XXX
 SG_ ErrorRegisterTemperature : 19|1@1+ (1,0) [0|0] "" Vector__XXX
 SG_ ErrorRegisterVoltage : 18|1@1+ (1,0) [0|0] "" Vector__XXX
 SG_ ErrorRegisterCurrent : 17|1@1+ (1,0) [0|0] "" Vector__XXX
 SG_ ErrorRegisterGeneric : 16|1@1+ (1,0) [0|0] "" Vector__XXX
 SG_ ErrorCode : 0|16@1+ (1,0) [0|0] "" Vector__XXX

BO_ 1911 HBGuard_119: 1 Vector__XXX
 SG_ Toggle : 7|1@1+ (1,0) [0|0] "" Vector__XXX
 SG_ State : 0|7@1+ (1,0) [0|0] "" Vector__XXX

BO_ 1527 SSDO_119: 8 Vector__XXX

BO_ 1655 CSDO_119: 8 Vector__XXX

BO_ 247 EMCY_119: 8 Vector__XXX
 SG_ ManufacturerSpecific5 : 56|8@1+ (1,0) [0|0] "" Vector__XXX
 SG_ ManufacturerSpecific4 : 48|8@1+ (1,0) [0|0] "" Vector__XXX
 SG_ ManufacturerSpecific3 : 40|8@1+ (1,0) [0|0] "" Vector__XXX
 SG_ ManufacturerSpecific2 : 32|8@1+ (1,0) [0|0] "" Vector__XXX
 SG_ ManufacturerSpecific1 : 24|8@1+ (1,0) [0|0] "" Vector__XXX
 SG_ ErrorRegisterManufSpecific : 23|1@1+ (1,0) [0|0] "" Vector__XXX
 SG_ ErrorRegisterReserved : 22|1@1+ (1,0) [0|0] "" Vector__XXX
 SG_ ErrorRegisterProfileSpecific : 21|1@1+ (1,0) [0|0] "" Vector__XXX
 SG_ ErrorRegisterCommunication : 20|1@1+ (1,0) [0|0] "" Vector__XXX
 SG_ ErrorRegisterTemperature : 19|1@1+ (1,0) [0|0] "" Vector__XXX
 SG_ ErrorRegisterVoltage : 18|1@1+ (1,0) [0|0] "" Vector__XXX
 SG_ ErrorRegisterCurrent : 17|1@1+ (1,0) [0|0] "" Vector__XXX
 SG_ ErrorRegisterGeneric : 16|1@1+ (1,0) [0|0] "" Vector__XXX
 SG_ ErrorCode : 0|16@1+ (1,0) [0|0] "" Vector__XXX

BO_ 1910 HBGuard_118: 1 Vector__XXX
 SG_ Toggle : 7|1@1+ (1,0) [0|0] "" Vector__XXX
 SG_ State : 0|7@1+ (1,0) [0|0] "" Vector__XXX

BO_ 1526 SSDO_118: 8 Vector__XXX

BO_ 1654 CSDO_118: 8 Vector__XXX

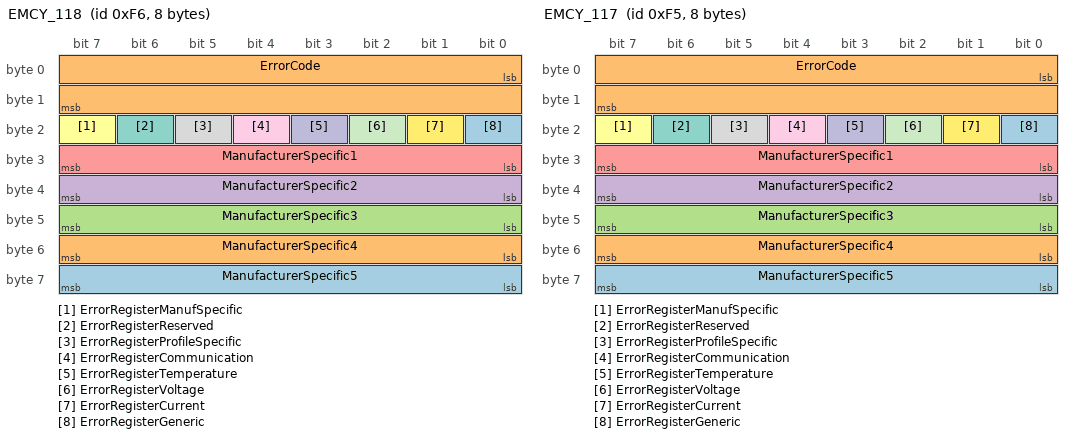
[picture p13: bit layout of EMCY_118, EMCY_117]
BO_ 246 EMCY_118: 8 Vector__XXX
 SG_ ManufacturerSpecific5 : 56|8@1+ (1,0) [0|0] "" Vector__XXX
 SG_ ManufacturerSpecific4 : 48|8@1+ (1,0) [0|0] "" Vector__XXX
 SG_ ManufacturerSpecific3 : 40|8@1+ (1,0) [0|0] "" Vector__XXX
 SG_ ManufacturerSpecific2 : 32|8@1+ (1,0) [0|0] "" Vector__XXX
 SG_ ManufacturerSpecific1 : 24|8@1+ (1,0) [0|0] "" Vector__XXX
 SG_ ErrorRegisterManufSpecific : 23|1@1+ (1,0) [0|0] "" Vector__XXX
 SG_ ErrorRegisterReserved : 22|1@1+ (1,0) [0|0] "" Vector__XXX
 SG_ ErrorRegisterProfileSpecific : 21|1@1+ (1,0) [0|0] "" Vector__XXX
 SG_ ErrorRegisterCommunication : 20|1@1+ (1,0) [0|0] "" Vector__XXX
 SG_ ErrorRegisterTemperature : 19|1@1+ (1,0) [0|0] "" Vector__XXX
 SG_ ErrorRegisterVoltage : 18|1@1+ (1,0) [0|0] "" Vector__XXX
 SG_ ErrorRegisterCurrent : 17|1@1+ (1,0) [0|0] "" Vector__XXX
 SG_ ErrorRegisterGeneric : 16|1@1+ (1,0) [0|0] "" Vector__XXX
 SG_ ErrorCode : 0|16@1+ (1,0) [0|0] "" Vector__XXX

BO_ 1909 HBGuard_117: 1 Vector__XXX
 SG_ Toggle : 7|1@1+ (1,0) [0|0] "" Vector__XXX
 SG_ State : 0|7@1+ (1,0) [0|0] "" Vector__XXX

BO_ 1525 SSDO_117: 8 Vector__XXX

BO_ 1653 CSDO_117: 8 Vector__XXX

BO_ 245 EMCY_117: 8 Vector__XXX
 SG_ ManufacturerSpecific5 : 56|8@1+ (1,0) [0|0] "" Vector__XXX
 SG_ ManufacturerSpecific4 : 48|8@1+ (1,0) [0|0] "" Vector__XXX
 SG_ ManufacturerSpecific3 : 40|8@1+ (1,0) [0|0] "" Vector__XXX
 SG_ ManufacturerSpecific2 : 32|8@1+ (1,0) [0|0] "" Vector__XXX
 SG_ ManufacturerSpecific1 : 24|8@1+ (1,0) [0|0] "" Vector__XXX
 SG_ ErrorRegisterManufSpecific : 23|1@1+ (1,0) [0|0] "" Vector__XXX
 SG_ ErrorRegisterReserved : 22|1@1+ (1,0) [0|0] "" Vector__XXX
 SG_ ErrorRegisterProfileSpecific : 21|1@1+ (1,0) [0|0] "" Vector__XXX
 SG_ ErrorRegisterCommunication : 20|1@1+ (1,0) [0|0] "" Vector__XXX
 SG_ ErrorRegisterTemperature : 19|1@1+ (1,0) [0|0] "" Vector__XXX
 SG_ ErrorRegisterVoltage : 18|1@1+ (1,0) [0|0] "" Vector__XXX
 SG_ ErrorRegisterCurrent : 17|1@1+ (1,0) [0|0] "" Vector__XXX
 SG_ ErrorRegisterGeneric : 16|1@1+ (1,0) [0|0] "" Vector__XXX
 SG_ ErrorCode : 0|16@1+ (1,0) [0|0] "" Vector__XXX

BO_ 1908 HBGuard_116: 1 Vector__XXX
 SG_ Toggle : 7|1@1+ (1,0) [0|0] "" Vector__XXX
 SG_ State : 0|7@1+ (1,0) [0|0] "" Vector__XXX

BO_ 1524 SSDO_116: 8 Vector__XXX

BO_ 1652 CSDO_116: 8 Vector__XXX

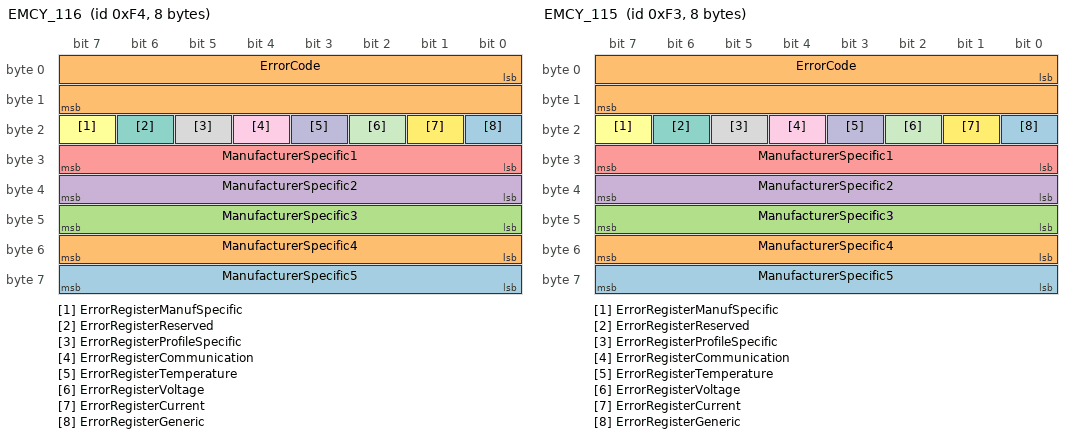
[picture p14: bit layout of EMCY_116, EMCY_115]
BO_ 244 EMCY_116: 8 Vector__XXX
 SG_ ManufacturerSpecific5 : 56|8@1+ (1,0) [0|0] "" Vector__XXX
 SG_ ManufacturerSpecific4 : 48|8@1+ (1,0) [0|0] "" Vector__XXX
 SG_ ManufacturerSpecific3 : 40|8@1+ (1,0) [0|0] "" Vector__XXX
 SG_ ManufacturerSpecific2 : 32|8@1+ (1,0) [0|0] "" Vector__XXX
 SG_ ManufacturerSpecific1 : 24|8@1+ (1,0) [0|0] "" Vector__XXX
 SG_ ErrorRegisterManufSpecific : 23|1@1+ (1,0) [0|0] "" Vector__XXX
 SG_ ErrorRegisterReserved : 22|1@1+ (1,0) [0|0] "" Vector__XXX
 SG_ ErrorRegisterProfileSpecific : 21|1@1+ (1,0) [0|0] "" Vector__XXX
 SG_ ErrorRegisterCommunication : 20|1@1+ (1,0) [0|0] "" Vector__XXX
 SG_ ErrorRegisterTemperature : 19|1@1+ (1,0) [0|0] "" Vector__XXX
 SG_ ErrorRegisterVoltage : 18|1@1+ (1,0) [0|0] "" Vector__XXX
 SG_ ErrorRegisterCurrent : 17|1@1+ (1,0) [0|0] "" Vector__XXX
 SG_ ErrorRegisterGeneric : 16|1@1+ (1,0) [0|0] "" Vector__XXX
 SG_ ErrorCode : 0|16@1+ (1,0) [0|0] "" Vector__XXX

BO_ 1907 HBGuard_115: 1 Vector__XXX
 SG_ Toggle : 7|1@1+ (1,0) [0|0] "" Vector__XXX
 SG_ State : 0|7@1+ (1,0) [0|0] "" Vector__XXX

BO_ 1523 SSDO_115: 8 Vector__XXX

BO_ 1651 CSDO_115: 8 Vector__XXX

BO_ 243 EMCY_115: 8 Vector__XXX
 SG_ ManufacturerSpecific5 : 56|8@1+ (1,0) [0|0] "" Vector__XXX
 SG_ ManufacturerSpecific4 : 48|8@1+ (1,0) [0|0] "" Vector__XXX
 SG_ ManufacturerSpecific3 : 40|8@1+ (1,0) [0|0] "" Vector__XXX
 SG_ ManufacturerSpecific2 : 32|8@1+ (1,0) [0|0] "" Vector__XXX
 SG_ ManufacturerSpecific1 : 24|8@1+ (1,0) [0|0] "" Vector__XXX
 SG_ ErrorRegisterManufSpecific : 23|1@1+ (1,0) [0|0] "" Vector__XXX
 SG_ ErrorRegisterReserved : 22|1@1+ (1,0) [0|0] "" Vector__XXX
 SG_ ErrorRegisterProfileSpecific : 21|1@1+ (1,0) [0|0] "" Vector__XXX
 SG_ ErrorRegisterCommunication : 20|1@1+ (1,0) [0|0] "" Vector__XXX
 SG_ ErrorRegisterTemperature : 19|1@1+ (1,0) [0|0] "" Vector__XXX
 SG_ ErrorRegisterVoltage : 18|1@1+ (1,0) [0|0] "" Vector__XXX
 SG_ ErrorRegisterCurrent : 17|1@1+ (1,0) [0|0] "" Vector__XXX
 SG_ ErrorRegisterGeneric : 16|1@1+ (1,0) [0|0] "" Vector__XXX
 SG_ ErrorCode : 0|16@1+ (1,0) [0|0] "" Vector__XXX

BO_ 1906 HBGuard_114: 1 Vector__XXX
 SG_ Toggle : 7|1@1+ (1,0) [0|0] "" Vector__XXX
 SG_ State : 0|7@1+ (1,0) [0|0] "" Vector__XXX

BO_ 1522 SSDO_114: 8 Vector__XXX

BO_ 1650 CSDO_114: 8 Vector__XXX

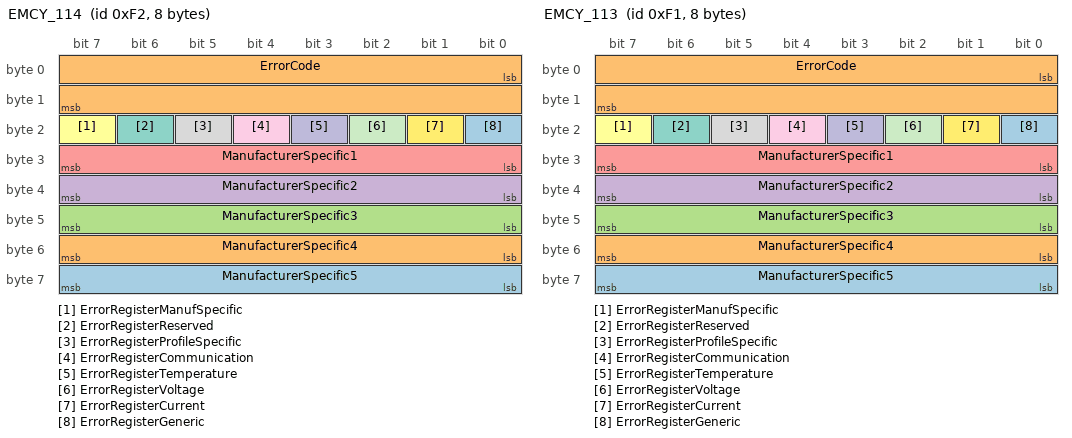
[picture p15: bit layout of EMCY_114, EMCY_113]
BO_ 242 EMCY_114: 8 Vector__XXX
 SG_ ManufacturerSpecific5 : 56|8@1+ (1,0) [0|0] "" Vector__XXX
 SG_ ManufacturerSpecific4 : 48|8@1+ (1,0) [0|0] "" Vector__XXX
 SG_ ManufacturerSpecific3 : 40|8@1+ (1,0) [0|0] "" Vector__XXX
 SG_ ManufacturerSpecific2 : 32|8@1+ (1,0) [0|0] "" Vector__XXX
 SG_ ManufacturerSpecific1 : 24|8@1+ (1,0) [0|0] "" Vector__XXX
 SG_ ErrorRegisterManufSpecific : 23|1@1+ (1,0) [0|0] "" Vector__XXX
 SG_ ErrorRegisterReserved : 22|1@1+ (1,0) [0|0] "" Vector__XXX
 SG_ ErrorRegisterProfileSpecific : 21|1@1+ (1,0) [0|0] "" Vector__XXX
 SG_ ErrorRegisterCommunication : 20|1@1+ (1,0) [0|0] "" Vector__XXX
 SG_ ErrorRegisterTemperature : 19|1@1+ (1,0) [0|0] "" Vector__XXX
 SG_ ErrorRegisterVoltage : 18|1@1+ (1,0) [0|0] "" Vector__XXX
 SG_ ErrorRegisterCurrent : 17|1@1+ (1,0) [0|0] "" Vector__XXX
 SG_ ErrorRegisterGeneric : 16|1@1+ (1,0) [0|0] "" Vector__XXX
 SG_ ErrorCode : 0|16@1+ (1,0) [0|0] "" Vector__XXX

BO_ 1905 HBGuard_113: 1 Vector__XXX
 SG_ Toggle : 7|1@1+ (1,0) [0|0] "" Vector__XXX
 SG_ State : 0|7@1+ (1,0) [0|0] "" Vector__XXX

BO_ 1521 SSDO_113: 8 Vector__XXX

BO_ 1649 CSDO_113: 8 Vector__XXX

BO_ 241 EMCY_113: 8 Vector__XXX
 SG_ ManufacturerSpecific5 : 56|8@1+ (1,0) [0|0] "" Vector__XXX
 SG_ ManufacturerSpecific4 : 48|8@1+ (1,0) [0|0] "" Vector__XXX
 SG_ ManufacturerSpecific3 : 40|8@1+ (1,0) [0|0] "" Vector__XXX
 SG_ ManufacturerSpecific2 : 32|8@1+ (1,0) [0|0] "" Vector__XXX
 SG_ ManufacturerSpecific1 : 24|8@1+ (1,0) [0|0] "" Vector__XXX
 SG_ ErrorRegisterManufSpecific : 23|1@1+ (1,0) [0|0] "" Vector__XXX
 SG_ ErrorRegisterReserved : 22|1@1+ (1,0) [0|0] "" Vector__XXX
 SG_ ErrorRegisterProfileSpecific : 21|1@1+ (1,0) [0|0] "" Vector__XXX
 SG_ ErrorRegisterCommunication : 20|1@1+ (1,0) [0|0] "" Vector__XXX
 SG_ ErrorRegisterTemperature : 19|1@1+ (1,0) [0|0] "" Vector__XXX
 SG_ ErrorRegisterVoltage : 18|1@1+ (1,0) [0|0] "" Vector__XXX
 SG_ ErrorRegisterCurrent : 17|1@1+ (1,0) [0|0] "" Vector__XXX
 SG_ ErrorRegisterGeneric : 16|1@1+ (1,0) [0|0] "" Vector__XXX
 SG_ ErrorCode : 0|16@1+ (1,0) [0|0] "" Vector__XXX

BO_ 1904 HBGuard_112: 1 Vector__XXX
 SG_ Toggle : 7|1@1+ (1,0) [0|0] "" Vector__XXX
 SG_ State : 0|7@1+ (1,0) [0|0] "" Vector__XXX

BO_ 1520 SSDO_112: 8 Vector__XXX

BO_ 1648 CSDO_112: 8 Vector__XXX

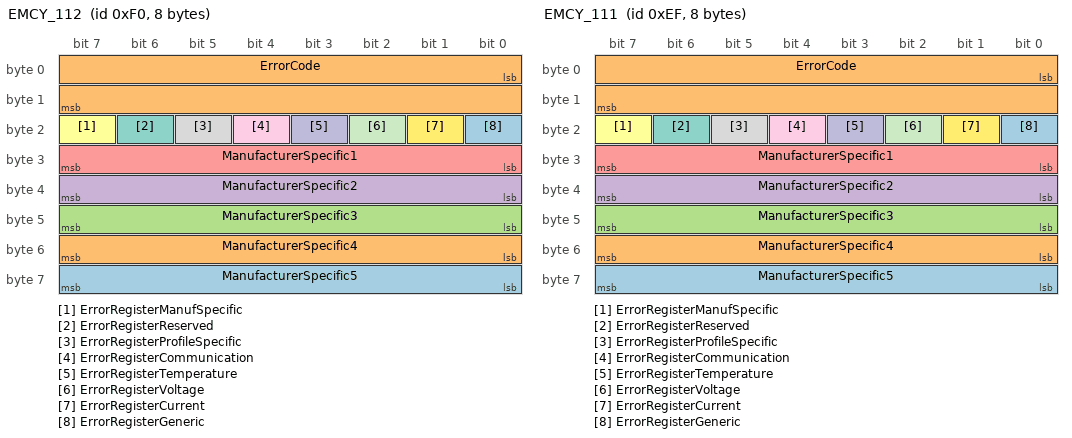
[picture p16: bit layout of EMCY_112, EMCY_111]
BO_ 240 EMCY_112: 8 Vector__XXX
 SG_ ManufacturerSpecific5 : 56|8@1+ (1,0) [0|0] "" Vector__XXX
 SG_ ManufacturerSpecific4 : 48|8@1+ (1,0) [0|0] "" Vector__XXX
 SG_ ManufacturerSpecific3 : 40|8@1+ (1,0) [0|0] "" Vector__XXX
 SG_ ManufacturerSpecific2 : 32|8@1+ (1,0) [0|0] "" Vector__XXX
 SG_ ManufacturerSpecific1 : 24|8@1+ (1,0) [0|0] "" Vector__XXX
 SG_ ErrorRegisterManufSpecific : 23|1@1+ (1,0) [0|0] "" Vector__XXX
 SG_ ErrorRegisterReserved : 22|1@1+ (1,0) [0|0] "" Vector__XXX
 SG_ ErrorRegisterProfileSpecific : 21|1@1+ (1,0) [0|0] "" Vector__XXX
 SG_ ErrorRegisterCommunication : 20|1@1+ (1,0) [0|0] "" Vector__XXX
 SG_ ErrorRegisterTemperature : 19|1@1+ (1,0) [0|0] "" Vector__XXX
 SG_ ErrorRegisterVoltage : 18|1@1+ (1,0) [0|0] "" Vector__XXX
 SG_ ErrorRegisterCurrent : 17|1@1+ (1,0) [0|0] "" Vector__XXX
 SG_ ErrorRegisterGeneric : 16|1@1+ (1,0) [0|0] "" Vector__XXX
 SG_ ErrorCode : 0|16@1+ (1,0) [0|0] "" Vector__XXX

BO_ 1903 HBGuard_111: 1 Vector__XXX
 SG_ Toggle : 7|1@1+ (1,0) [0|0] "" Vector__XXX
 SG_ State : 0|7@1+ (1,0) [0|0] "" Vector__XXX

BO_ 1519 SSDO_111: 8 Vector__XXX

BO_ 1647 CSDO_111: 8 Vector__XXX

BO_ 239 EMCY_111: 8 Vector__XXX
 SG_ ManufacturerSpecific5 : 56|8@1+ (1,0) [0|0] "" Vector__XXX
 SG_ ManufacturerSpecific4 : 48|8@1+ (1,0) [0|0] "" Vector__XXX
 SG_ ManufacturerSpecific3 : 40|8@1+ (1,0) [0|0] "" Vector__XXX
 SG_ ManufacturerSpecific2 : 32|8@1+ (1,0) [0|0] "" Vector__XXX
 SG_ ManufacturerSpecific1 : 24|8@1+ (1,0) [0|0] "" Vector__XXX
 SG_ ErrorRegisterManufSpecific : 23|1@1+ (1,0) [0|0] "" Vector__XXX
 SG_ ErrorRegisterReserved : 22|1@1+ (1,0) [0|0] "" Vector__XXX
 SG_ ErrorRegisterProfileSpecific : 21|1@1+ (1,0) [0|0] "" Vector__XXX
 SG_ ErrorRegisterCommunication : 20|1@1+ (1,0) [0|0] "" Vector__XXX
 SG_ ErrorRegisterTemperature : 19|1@1+ (1,0) [0|0] "" Vector__XXX
 SG_ ErrorRegisterVoltage : 18|1@1+ (1,0) [0|0] "" Vector__XXX
 SG_ ErrorRegisterCurrent : 17|1@1+ (1,0) [0|0] "" Vector__XXX
 SG_ ErrorRegisterGeneric : 16|1@1+ (1,0) [0|0] "" Vector__XXX
 SG_ ErrorCode : 0|16@1+ (1,0) [0|0] "" Vector__XXX

BO_ 1902 HBGuard_110: 1 Vector__XXX
 SG_ Toggle : 7|1@1+ (1,0) [0|0] "" Vector__XXX
 SG_ State : 0|7@1+ (1,0) [0|0] "" Vector__XXX

BO_ 1518 SSDO_110: 8 Vector__XXX

BO_ 1646 CSDO_110: 8 Vector__XXX

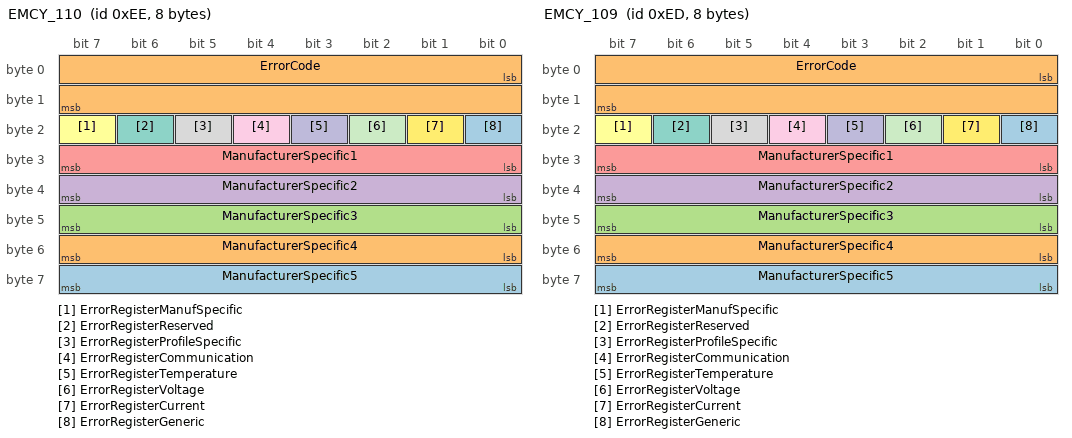
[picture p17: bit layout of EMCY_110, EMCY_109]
BO_ 238 EMCY_110: 8 Vector__XXX
 SG_ ManufacturerSpecific5 : 56|8@1+ (1,0) [0|0] "" Vector__XXX
 SG_ ManufacturerSpecific4 : 48|8@1+ (1,0) [0|0] "" Vector__XXX
 SG_ ManufacturerSpecific3 : 40|8@1+ (1,0) [0|0] "" Vector__XXX
 SG_ ManufacturerSpecific2 : 32|8@1+ (1,0) [0|0] "" Vector__XXX
 SG_ ManufacturerSpecific1 : 24|8@1+ (1,0) [0|0] "" Vector__XXX
 SG_ ErrorRegisterManufSpecific : 23|1@1+ (1,0) [0|0] "" Vector__XXX
 SG_ ErrorRegisterReserved : 22|1@1+ (1,0) [0|0] "" Vector__XXX
 SG_ ErrorRegisterProfileSpecific : 21|1@1+ (1,0) [0|0] "" Vector__XXX
 SG_ ErrorRegisterCommunication : 20|1@1+ (1,0) [0|0] "" Vector__XXX
 SG_ ErrorRegisterTemperature : 19|1@1+ (1,0) [0|0] "" Vector__XXX
 SG_ ErrorRegisterVoltage : 18|1@1+ (1,0) [0|0] "" Vector__XXX
 SG_ ErrorRegisterCurrent : 17|1@1+ (1,0) [0|0] "" Vector__XXX
 SG_ ErrorRegisterGeneric : 16|1@1+ (1,0) [0|0] "" Vector__XXX
 SG_ ErrorCode : 0|16@1+ (1,0) [0|0] "" Vector__XXX

BO_ 1901 HBGuard_109: 1 Vector__XXX
 SG_ Toggle : 7|1@1+ (1,0) [0|0] "" Vector__XXX
 SG_ State : 0|7@1+ (1,0) [0|0] "" Vector__XXX

BO_ 1517 SSDO_109: 8 Vector__XXX

BO_ 1645 CSDO_109: 8 Vector__XXX

BO_ 237 EMCY_109: 8 Vector__XXX
 SG_ ManufacturerSpecific5 : 56|8@1+ (1,0) [0|0] "" Vector__XXX
 SG_ ManufacturerSpecific4 : 48|8@1+ (1,0) [0|0] "" Vector__XXX
 SG_ ManufacturerSpecific3 : 40|8@1+ (1,0) [0|0] "" Vector__XXX
 SG_ ManufacturerSpecific2 : 32|8@1+ (1,0) [0|0] "" Vector__XXX
 SG_ ManufacturerSpecific1 : 24|8@1+ (1,0) [0|0] "" Vector__XXX
 SG_ ErrorRegisterManufSpecific : 23|1@1+ (1,0) [0|0] "" Vector__XXX
 SG_ ErrorRegisterReserved : 22|1@1+ (1,0) [0|0] "" Vector__XXX
 SG_ ErrorRegisterProfileSpecific : 21|1@1+ (1,0) [0|0] "" Vector__XXX
 SG_ ErrorRegisterCommunication : 20|1@1+ (1,0) [0|0] "" Vector__XXX
 SG_ ErrorRegisterTemperature : 19|1@1+ (1,0) [0|0] "" Vector__XXX
 SG_ ErrorRegisterVoltage : 18|1@1+ (1,0) [0|0] "" Vector__XXX
 SG_ ErrorRegisterCurrent : 17|1@1+ (1,0) [0|0] "" Vector__XXX
 SG_ ErrorRegisterGeneric : 16|1@1+ (1,0) [0|0] "" Vector__XXX
 SG_ ErrorCode : 0|16@1+ (1,0) [0|0] "" Vector__XXX

BO_ 1900 HBGuard_108: 1 Vector__XXX
 SG_ Toggle : 7|1@1+ (1,0) [0|0] "" Vector__XXX
 SG_ State : 0|7@1+ (1,0) [0|0] "" Vector__XXX

BO_ 1516 SSDO_108: 8 Vector__XXX

BO_ 1644 CSDO_108: 8 Vector__XXX

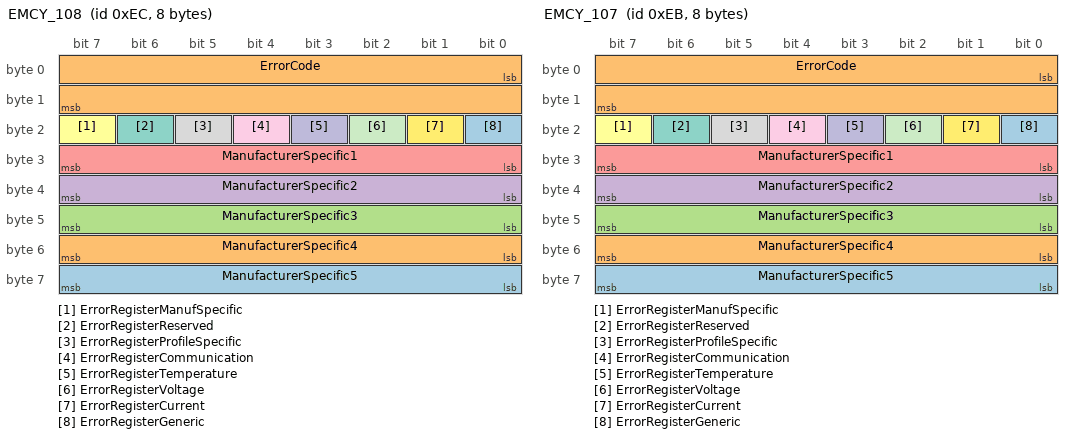
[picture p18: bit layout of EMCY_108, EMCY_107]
BO_ 236 EMCY_108: 8 Vector__XXX
 SG_ ManufacturerSpecific5 : 56|8@1+ (1,0) [0|0] "" Vector__XXX
 SG_ ManufacturerSpecific4 : 48|8@1+ (1,0) [0|0] "" Vector__XXX
 SG_ ManufacturerSpecific3 : 40|8@1+ (1,0) [0|0] "" Vector__XXX
 SG_ ManufacturerSpecific2 : 32|8@1+ (1,0) [0|0] "" Vector__XXX
 SG_ ManufacturerSpecific1 : 24|8@1+ (1,0) [0|0] "" Vector__XXX
 SG_ ErrorRegisterManufSpecific : 23|1@1+ (1,0) [0|0] "" Vector__XXX
 SG_ ErrorRegisterReserved : 22|1@1+ (1,0) [0|0] "" Vector__XXX
 SG_ ErrorRegisterProfileSpecific : 21|1@1+ (1,0) [0|0] "" Vector__XXX
 SG_ ErrorRegisterCommunication : 20|1@1+ (1,0) [0|0] "" Vector__XXX
 SG_ ErrorRegisterTemperature : 19|1@1+ (1,0) [0|0] "" Vector__XXX
 SG_ ErrorRegisterVoltage : 18|1@1+ (1,0) [0|0] "" Vector__XXX
 SG_ ErrorRegisterCurrent : 17|1@1+ (1,0) [0|0] "" Vector__XXX
 SG_ ErrorRegisterGeneric : 16|1@1+ (1,0) [0|0] "" Vector__XXX
 SG_ ErrorCode : 0|16@1+ (1,0) [0|0] "" Vector__XXX

BO_ 1899 HBGuard_107: 1 Vector__XXX
 SG_ Toggle : 7|1@1+ (1,0) [0|0] "" Vector__XXX
 SG_ State : 0|7@1+ (1,0) [0|0] "" Vector__XXX

BO_ 1515 SSDO_107: 8 Vector__XXX

BO_ 1643 CSDO_107: 8 Vector__XXX

BO_ 235 EMCY_107: 8 Vector__XXX
 SG_ ManufacturerSpecific5 : 56|8@1+ (1,0) [0|0] "" Vector__XXX
 SG_ ManufacturerSpecific4 : 48|8@1+ (1,0) [0|0] "" Vector__XXX
 SG_ ManufacturerSpecific3 : 40|8@1+ (1,0) [0|0] "" Vector__XXX
 SG_ ManufacturerSpecific2 : 32|8@1+ (1,0) [0|0] "" Vector__XXX
 SG_ ManufacturerSpecific1 : 24|8@1+ (1,0) [0|0] "" Vector__XXX
 SG_ ErrorRegisterManufSpecific : 23|1@1+ (1,0) [0|0] "" Vector__XXX
 SG_ ErrorRegisterReserved : 22|1@1+ (1,0) [0|0] "" Vector__XXX
 SG_ ErrorRegisterProfileSpecific : 21|1@1+ (1,0) [0|0] "" Vector__XXX
 SG_ ErrorRegisterCommunication : 20|1@1+ (1,0) [0|0] "" Vector__XXX
 SG_ ErrorRegisterTemperature : 19|1@1+ (1,0) [0|0] "" Vector__XXX
 SG_ ErrorRegisterVoltage : 18|1@1+ (1,0) [0|0] "" Vector__XXX
 SG_ ErrorRegisterCurrent : 17|1@1+ (1,0) [0|0] "" Vector__XXX
 SG_ ErrorRegisterGeneric : 16|1@1+ (1,0) [0|0] "" Vector__XXX
 SG_ ErrorCode : 0|16@1+ (1,0) [0|0] "" Vector__XXX

BO_ 1898 HBGuard_106: 1 Vector__XXX
 SG_ Toggle : 7|1@1+ (1,0) [0|0] "" Vector__XXX
 SG_ State : 0|7@1+ (1,0) [0|0] "" Vector__XXX

BO_ 1514 SSDO_106: 8 Vector__XXX

BO_ 1642 CSDO_106: 8 Vector__XXX

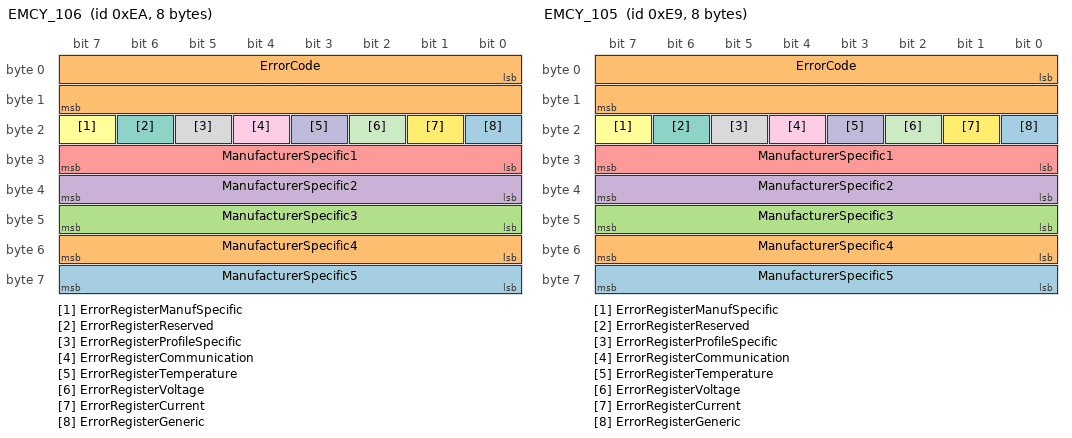
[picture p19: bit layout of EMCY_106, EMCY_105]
BO_ 234 EMCY_106: 8 Vector__XXX
 SG_ ManufacturerSpecific5 : 56|8@1+ (1,0) [0|0] "" Vector__XXX
 SG_ ManufacturerSpecific4 : 48|8@1+ (1,0) [0|0] "" Vector__XXX
 SG_ ManufacturerSpecific3 : 40|8@1+ (1,0) [0|0] "" Vector__XXX
 SG_ ManufacturerSpecific2 : 32|8@1+ (1,0) [0|0] "" Vector__XXX
 SG_ ManufacturerSpecific1 : 24|8@1+ (1,0) [0|0] "" Vector__XXX
 SG_ ErrorRegisterManufSpecific : 23|1@1+ (1,0) [0|0] "" Vector__XXX
 SG_ ErrorRegisterReserved : 22|1@1+ (1,0) [0|0] "" Vector__XXX
 SG_ ErrorRegisterProfileSpecific : 21|1@1+ (1,0) [0|0] "" Vector__XXX
 SG_ ErrorRegisterCommunication : 20|1@1+ (1,0) [0|0] "" Vector__XXX
 SG_ ErrorRegisterTemperature : 19|1@1+ (1,0) [0|0] "" Vector__XXX
 SG_ ErrorRegisterVoltage : 18|1@1+ (1,0) [0|0] "" Vector__XXX
 SG_ ErrorRegisterCurrent : 17|1@1+ (1,0) [0|0] "" Vector__XXX
 SG_ ErrorRegisterGeneric : 16|1@1+ (1,0) [0|0] "" Vector__XXX
 SG_ ErrorCode : 0|16@1+ (1,0) [0|0] "" Vector__XXX

BO_ 1897 HBGuard_105: 1 Vector__XXX
 SG_ Toggle : 7|1@1+ (1,0) [0|0] "" Vector__XXX
 SG_ State : 0|7@1+ (1,0) [0|0] "" Vector__XXX

BO_ 1513 SSDO_105: 8 Vector__XXX

BO_ 1641 CSDO_105: 8 Vector__XXX

BO_ 233 EMCY_105: 8 Vector__XXX
 SG_ ManufacturerSpecific5 : 56|8@1+ (1,0) [0|0] "" Vector__XXX
 SG_ ManufacturerSpecific4 : 48|8@1+ (1,0) [0|0] "" Vector__XXX
 SG_ ManufacturerSpecific3 : 40|8@1+ (1,0) [0|0] "" Vector__XXX
 SG_ ManufacturerSpecific2 : 32|8@1+ (1,0) [0|0] "" Vector__XXX
 SG_ ManufacturerSpecific1 : 24|8@1+ (1,0) [0|0] "" Vector__XXX
 SG_ ErrorRegisterManufSpecific : 23|1@1+ (1,0) [0|0] "" Vector__XXX
 SG_ ErrorRegisterReserved : 22|1@1+ (1,0) [0|0] "" Vector__XXX
 SG_ ErrorRegisterProfileSpecific : 21|1@1+ (1,0) [0|0] "" Vector__XXX
 SG_ ErrorRegisterCommunication : 20|1@1+ (1,0) [0|0] "" Vector__XXX
 SG_ ErrorRegisterTemperature : 19|1@1+ (1,0) [0|0] "" Vector__XXX
 SG_ ErrorRegisterVoltage : 18|1@1+ (1,0) [0|0] "" Vector__XXX
 SG_ ErrorRegisterCurrent : 17|1@1+ (1,0) [0|0] "" Vector__XXX
 SG_ ErrorRegisterGeneric : 16|1@1+ (1,0) [0|0] "" Vector__XXX
 SG_ ErrorCode : 0|16@1+ (1,0) [0|0] "" Vector__XXX

BO_ 1896 HBGuard_104: 1 Vector__XXX
 SG_ Toggle : 7|1@1+ (1,0) [0|0] "" Vector__XXX
 SG_ State : 0|7@1+ (1,0) [0|0] "" Vector__XXX

BO_ 1512 SSDO_104: 8 Vector__XXX

BO_ 1640 CSDO_104: 8 Vector__XXX

BO_ 232 EMCY_104: 8 Vector__XXX
 SG_ ManufacturerSpecific5 : 56|8@1+ (1,0) [0|0] "" Vector__XXX
 SG_ ManufacturerSpecific4 : 48|8@1+ (1,0) [0|0] "" Vector__XXX
 SG_ ManufacturerSpecific3 : 40|8@1+ (1,0) [0|0] "" Vector__XXX
 SG_ ManufacturerSpecific2 : 32|8@1+ (1,0) [0|0] "" Vector__XXX
 SG_ ManufacturerSpecific1 : 24|8@1+ (1,0) [0|0] "" Vector__XXX
 SG_ ErrorRegisterManufSpecific : 23|1@1+ (1,0) [0|0] "" Vector__XXX
 SG_ ErrorRegisterReserved : 22|1@1+ (1,0) [0|0] "" Vector__XXX
 SG_ ErrorRegisterProfileSpecific : 21|1@1+ (1,0) [0|0] "" Vector__XXX
 SG_ ErrorRegisterCommunication : 20|1@1+ (1,0) [0|0] "" Vector__XXX
 SG_ ErrorRegisterTemperature : 19|1@1+ (1,0) [0|0] "" Vector__XXX
 SG_ ErrorRegisterVoltage : 18|1@1+ (1,0) [0|0] "" Vector__XXX
 SG_ ErrorRegisterCurrent : 17|1@1+ (1,0) [0|0] "" Vector__XXX
 SG_ ErrorRegisterGeneric : 16|1@1+ (1,0) [0|0] "" Vector__XXX
 SG_ ErrorCode : 0|16@1+ (1,0) [0|0] "" Vector__XXX

BO_ 1895 HBGuard_103: 1 Vector__XXX
 SG_ Toggle : 7|1@1+ (1,0) [0|0] "" Vector__XXX
 SG_ State : 0|7@1+ (1,0) [0|0] "" Vector__XXX

BO_ 1511 SSDO_103: 8 Vector__XXX

BO_ 1639 CSDO_103: 8 Vector__XXX

BO_ 231 EMCY_103: 8 Vector__XXX
 SG_ ManufacturerSpecific5 : 56|8@1+ (1,0) [0|0] "" Vector__XXX
 SG_ ManufacturerSpecific4 : 48|8@1+ (1,0) [0|0] "" Vector__XXX
 SG_ ManufacturerSpecific3 : 40|8@1+ (1,0) [0|0] "" Vector__XXX
 SG_ ManufacturerSpecific2 : 32|8@1+ (1,0) [0|0] "" Vector__XXX
 SG_ ManufacturerSpecific1 : 24|8@1+ (1,0) [0|0] "" Vector__XXX
 SG_ ErrorRegisterManufSpecific : 23|1@1+ (1,0) [0|0] "" Vector__XXX
 SG_ ErrorRegisterReserved : 22|1@1+ (1,0) [0|0] "" Vector__XXX
 SG_ ErrorRegisterProfileSpecific : 21|1@1+ (1,0) [0|0] "" Vector__XXX
 SG_ ErrorRegisterCommunication : 20|1@1+ (1,0) [0|0] "" Vector__XXX
 SG_ ErrorRegisterTemperature : 19|1@1+ (1,0) [0|0] "" Vector__XXX
 SG_ ErrorRegisterVoltage : 18|1@1+ (1,0) [0|0] "" Vector__XXX
 SG_ ErrorRegisterCurrent : 17|1@1+ (1,0) [0|0] "" Vector__XXX
 SG_ ErrorRegisterGeneric : 16|1@1+ (1,0) [0|0] "" Vector__XXX
 SG_ ErrorCode : 0|16@1+ (1,0) [0|0] "" Vector__XXX

BO_ 1894 HBGuard_102: 1 Vector__XXX
 SG_ Toggle : 7|1@1+ (1,0) [0|0] "" Vector__XXX
 SG_ State : 0|7@1+ (1,0) [0|0] "" Vector__XXX

BO_ 1510 SSDO_102: 8 Vector__XXX

BO_ 1638 CSDO_102: 8 Vector__XXX

BO_ 230 EMCY_102: 8 Vector__XXX
 SG_ ManufacturerSpecific5 : 56|8@1+ (1,0) [0|0] "" Vector__XXX
 SG_ ManufacturerSpecific4 : 48|8@1+ (1,0) [0|0] "" Vector__XXX
 SG_ ManufacturerSpecific3 : 40|8@1+ (1,0) [0|0] "" Vector__XXX
 SG_ ManufacturerSpecific2 : 32|8@1+ (1,0) [0|0] "" Vector__XXX
 SG_ ManufacturerSpecific1 : 24|8@1+ (1,0) [0|0] "" Vector__XXX
 SG_ ErrorRegisterManufSpecific : 23|1@1+ (1,0) [0|0] "" Vector__XXX
 SG_ ErrorRegisterReserved : 22|1@1+ (1,0) [0|0] "" Vector__XXX
 SG_ ErrorRegisterProfileSpecific : 21|1@1+ (1,0) [0|0] "" Vector__XXX
 SG_ ErrorRegisterCommunication : 20|1@1+ (1,0) [0|0] "" Vector__XXX
 SG_ ErrorRegisterTemperature : 19|1@1+ (1,0) [0|0] "" Vector__XXX
 SG_ ErrorRegisterVoltage : 18|1@1+ (1,0) [0|0] "" Vector__XXX
 SG_ ErrorRegisterCurrent : 17|1@1+ (1,0) [0|0] "" Vector__XXX
 SG_ ErrorRegisterGeneric : 16|1@1+ (1,0) [0|0] "" Vector__XXX
 SG_ ErrorCode : 0|16@1+ (1,0) [0|0] "" Vector__XXX

BO_ 1893 HBGuard_101: 1 Vector__XXX
 SG_ Toggle : 7|1@1+ (1,0) [0|0] "" Vector__XXX
 SG_ State : 0|7@1+ (1,0) [0|0] "" Vector__XXX

BO_ 1509 SSDO_101: 8 Vector__XXX

BO_ 1637 CSDO_101: 8 Vector__XXX

BO_ 229 EMCY_101: 8 Vector__XXX
 SG_ ManufacturerSpecific5 : 56|8@1+ (1,0) [0|0] "" Vector__XXX
 SG_ ManufacturerSpecific4 : 48|8@1+ (1,0) [0|0] "" Vector__XXX
 SG_ ManufacturerSpecific3 : 40|8@1+ (1,0) [0|0] "" Vector__XXX
 SG_ ManufacturerSpecific2 : 32|8@1+ (1,0) [0|0] "" Vector__XXX
 SG_ ManufacturerSpecific1 : 24|8@1+ (1,0) [0|0] "" Vector__XXX
 SG_ ErrorRegisterManufSpecific : 23|1@1+ (1,0) [0|0] "" Vector__XXX
 SG_ ErrorRegisterReserved : 22|1@1+ (1,0) [0|0] "" Vector__XXX
 SG_ ErrorRegisterProfileSpecific : 21|1@1+ (1,0) [0|0] "" Vector__XXX
 SG_ ErrorRegisterCommunication : 20|1@1+ (1,0) [0|0] "" Vector__XXX
 SG_ ErrorRegisterTemperature : 19|1@1+ (1,0) [0|0] "" Vector__XXX
 SG_ ErrorRegisterVoltage : 18|1@1+ (1,0) [0|0] "" Vector__XXX
 SG_ ErrorRegisterCurrent : 17|1@1+ (1,0) [0|0] "" Vector__XXX
 SG_ ErrorRegisterGeneric : 16|1@1+ (1,0) [0|0] "" Vector__XXX
 SG_ ErrorCode : 0|16@1+ (1,0) [0|0] "" Vector__XXX

BO_ 1892 HBGuard_100: 1 Vector__XXX
 SG_ Toggle : 7|1@1+ (1,0) [0|0] "" Vector__XXX
 SG_ State : 0|7@1+ (1,0) [0|0] "" Vector__XXX

BO_ 1508 SSDO_100: 8 Vector__XXX

BO_ 1636 CSDO_100: 8 Vector__XXX

BO_ 228 EMCY_100: 8 Vector__XXX
 SG_ ManufacturerSpecific5 : 56|8@1+ (1,0) [0|0] "" Vector__XXX
 SG_ ManufacturerSpecific4 : 48|8@1+ (1,0) [0|0] "" Vector__XXX
 SG_ ManufacturerSpecific3 : 40|8@1+ (1,0) [0|0] "" Vector__XXX
 SG_ ManufacturerSpecific2 : 32|8@1+ (1,0) [0|0] "" Vector__XXX
 SG_ ManufacturerSpecific1 : 24|8@1+ (1,0) [0|0] "" Vector__XXX
 SG_ ErrorRegisterManufSpecific : 23|1@1+ (1,0) [0|0] "" Vector__XXX
 SG_ ErrorRegisterReserved : 22|1@1+ (1,0) [0|0] "" Vector__XXX
 SG_ ErrorRegisterProfileSpecific : 21|1@1+ (1,0) [0|0] "" Vector__XXX
 SG_ ErrorRegisterCommunication : 20|1@1+ (1,0) [0|0] "" Vector__XXX
 SG_ ErrorRegisterTemperature : 19|1@1+ (1,0) [0|0] "" Vector__XXX
 SG_ ErrorRegisterVoltage : 18|1@1+ (1,0) [0|0] "" Vector__XXX
 SG_ ErrorRegisterCurrent : 17|1@1+ (1,0) [0|0] "" Vector__XXX
 SG_ ErrorRegisterGeneric : 16|1@1+ (1,0) [0|0] "" Vector__XXX
 SG_ ErrorCode : 0|16@1+ (1,0) [0|0] "" Vector__XXX

BO_ 1891 HBGuard_099: 1 Vector__XXX
 SG_ Toggle : 7|1@1+ (1,0) [0|0] "" Vector__XXX
 SG_ State : 0|7@1+ (1,0) [0|0] "" Vector__XXX

BO_ 1507 SSDO_099: 8 Vector__XXX

BO_ 1635 CSDO_099: 8 Vector__XXX

BO_ 227 EMCY_099: 8 Vector__XXX
 SG_ ManufacturerSpecific5 : 56|8@1+ (1,0) [0|0] "" Vector__XXX
 SG_ ManufacturerSpecific4 : 48|8@1+ (1,0) [0|0] "" Vector__XXX
 SG_ ManufacturerSpecific3 : 40|8@1+ (1,0) [0|0] "" Vector__XXX
 SG_ ManufacturerSpecific2 : 32|8@1+ (1,0) [0|0] "" Vector__XXX
 SG_ ManufacturerSpecific1 : 24|8@1+ (1,0) [0|0] "" Vector__XXX
 SG_ ErrorRegisterManufSpecific : 23|1@1+ (1,0) [0|0] "" Vector__XXX
 SG_ ErrorRegisterReserved : 22|1@1+ (1,0) [0|0] "" Vector__XXX
 SG_ ErrorRegisterProfileSpecific : 21|1@1+ (1,0) [0|0] "" Vector__XXX
 SG_ ErrorRegisterCommunication : 20|1@1+ (1,0) [0|0] "" Vector__XXX
 SG_ ErrorRegisterTemperature : 19|1@1+ (1,0) [0|0] "" Vector__XXX
 SG_ ErrorRegisterVoltage : 18|1@1+ (1,0) [0|0] "" Vector__XXX
 SG_ ErrorRegisterCurrent : 17|1@1+ (1,0) [0|0] "" Vector__XXX
 SG_ ErrorRegisterGeneric : 16|1@1+ (1,0) [0|0] "" Vector__XXX
 SG_ ErrorCode : 0|16@1+ (1,0) [0|0] "" Vector__XXX

BO_ 1890 HBGuard_098: 1 Vector__XXX
 SG_ Toggle : 7|1@1+ (1,0) [0|0] "" Vector__XXX
 SG_ State : 0|7@1+ (1,0) [0|0] "" Vector__XXX

BO_ 1506 SSDO_098: 8 Vector__XXX

BO_ 1634 CSDO_098: 8 Vector__XXX

BO_ 226 EMCY_098: 8 Vector__XXX
 SG_ ManufacturerSpecific5 : 56|8@1+ (1,0) [0|0] "" Vector__XXX
 SG_ ManufacturerSpecific4 : 48|8@1+ (1,0) [0|0] "" Vector__XXX
 SG_ ManufacturerSpecific3 : 40|8@1+ (1,0) [0|0] "" Vector__XXX
 SG_ ManufacturerSpecific2 : 32|8@1+ (1,0) [0|0] "" Vector__XXX
 SG_ ManufacturerSpecific1 : 24|8@1+ (1,0) [0|0] "" Vector__XXX
 SG_ ErrorRegisterManufSpecific : 23|1@1+ (1,0) [0|0] "" Vector__XXX
 SG_ ErrorRegisterReserved : 22|1@1+ (1,0) [0|0] "" Vector__XXX
 SG_ ErrorRegisterProfileSpecific : 21|1@1+ (1,0) [0|0] "" Vector__XXX
 SG_ ErrorRegisterCommunication : 20|1@1+ (1,0) [0|0] "" Vector__XXX
 SG_ ErrorRegisterTemperature : 19|1@1+ (1,0) [0|0] "" Vector__XXX
 SG_ ErrorRegisterVoltage : 18|1@1+ (1,0) [0|0] "" Vector__XXX
 SG_ ErrorRegisterCurrent : 17|1@1+ (1,0) [0|0] "" Vector__XXX
 SG_ ErrorRegisterGeneric : 16|1@1+ (1,0) [0|0] "" Vector__XXX
 SG_ ErrorCode : 0|16@1+ (1,0) [0|0] "" Vector__XXX

BO_ 1889 HBGuard_097: 1 Vector__XXX
 SG_ Toggle : 7|1@1+ (1,0) [0|0] "" Vector__XXX
 SG_ State : 0|7@1+ (1,0) [0|0] "" Vector__XXX

BO_ 1505 SSDO_097: 8 Vector__XXX

BO_ 1633 CSDO_097: 8 Vector__XXX

BO_ 225 EMCY_097: 8 Vector__XXX
 SG_ ManufacturerSpecific5 : 56|8@1+ (1,0) [0|0] "" Vector__XXX
 SG_ ManufacturerSpecific4 : 48|8@1+ (1,0) [0|0] "" Vector__XXX
 SG_ ManufacturerSpecific3 : 40|8@1+ (1,0) [0|0] "" Vector__XXX
 SG_ ManufacturerSpecific2 : 32|8@1+ (1,0) [0|0] "" Vector__XXX
 SG_ ManufacturerSpecific1 : 24|8@1+ (1,0) [0|0] "" Vector__XXX
 SG_ ErrorRegisterManufSpecific : 23|1@1+ (1,0) [0|0] "" Vector__XXX
 SG_ ErrorRegisterReserved : 22|1@1+ (1,0) [0|0] "" Vector__XXX
 SG_ ErrorRegisterProfileSpecific : 21|1@1+ (1,0) [0|0] "" Vector__XXX
 SG_ ErrorRegisterCommunication : 20|1@1+ (1,0) [0|0] "" Vector__XXX
 SG_ ErrorRegisterTemperature : 19|1@1+ (1,0) [0|0] "" Vector__XXX
 SG_ ErrorRegisterVoltage : 18|1@1+ (1,0) [0|0] "" Vector__XXX
 SG_ ErrorRegisterCurrent : 17|1@1+ (1,0) [0|0] "" Vector__XXX
 SG_ ErrorRegisterGeneric : 16|1@1+ (1,0) [0|0] "" Vector__XXX
 SG_ ErrorCode : 0|16@1+ (1,0) [0|0] "" Vector__XXX

BO_ 1888 HBGuard_096: 1 Vector__XXX
 SG_ Toggle : 7|1@1+ (1,0) [0|0] "" Vector__XXX
 SG_ State : 0|7@1+ (1,0) [0|0] "" Vector__XXX

BO_ 1504 SSDO_096: 8 Vector__XXX

BO_ 1632 CSDO_096: 8 Vector__XXX

BO_ 224 EMCY_096: 8 Vector__XXX
 SG_ ManufacturerSpecific5 : 56|8@1+ (1,0) [0|0] "" Vector__XXX
 SG_ ManufacturerSpecific4 : 48|8@1+ (1,0) [0|0] "" Vector__XXX
 SG_ ManufacturerSpecific3 : 40|8@1+ (1,0) [0|0] "" Vector__XXX
 SG_ ManufacturerSpecific2 : 32|8@1+ (1,0) [0|0] "" Vector__XXX
 SG_ ManufacturerSpecific1 : 24|8@1+ (1,0) [0|0] "" Vector__XXX
 SG_ ErrorRegisterManufSpecific : 23|1@1+ (1,0) [0|0] "" Vector__XXX
 SG_ ErrorRegisterReserved : 22|1@1+ (1,0) [0|0] "" Vector__XXX
 SG_ ErrorRegisterProfileSpecific : 21|1@1+ (1,0) [0|0] "" Vector__XXX
 SG_ ErrorRegisterCommunication : 20|1@1+ (1,0) [0|0] "" Vector__XXX
 SG_ ErrorRegisterTemperature : 19|1@1+ (1,0) [0|0] "" Vector__XXX
 SG_ ErrorRegisterVoltage : 18|1@1+ (1,0) [0|0] "" Vector__XXX
 SG_ ErrorRegisterCurrent : 17|1@1+ (1,0) [0|0] "" Vector__XXX
 SG_ ErrorRegisterGeneric : 16|1@1+ (1,0) [0|0] "" Vector__XXX
 SG_ ErrorCode : 0|16@1+ (1,0) [0|0] "" Vector__XXX

BO_ 1887 HBGuard_095: 1 Vector__XXX
 SG_ Toggle : 7|1@1+ (1,0) [0|0] "" Vector__XXX
 SG_ State : 0|7@1+ (1,0) [0|0] "" Vector__XXX

BO_ 1503 SSDO_095: 8 Vector__XXX

BO_ 1631 CSDO_095: 8 Vector__XXX

BO_ 223 EMCY_095: 8 Vector__XXX
 SG_ ManufacturerSpecific5 : 56|8@1+ (1,0) [0|0] "" Vector__XXX
 SG_ ManufacturerSpecific4 : 48|8@1+ (1,0) [0|0] "" Vector__XXX
 SG_ ManufacturerSpecific3 : 40|8@1+ (1,0) [0|0] "" Vector__XXX
 SG_ ManufacturerSpecific2 : 32|8@1+ (1,0) [0|0] "" Vector__XXX
 SG_ ManufacturerSpecific1 : 24|8@1+ (1,0) [0|0] "" Vector__XXX
 SG_ ErrorRegisterManufSpecific : 23|1@1+ (1,0) [0|0] "" Vector__XXX
 SG_ ErrorRegisterReserved : 22|1@1+ (1,0) [0|0] "" Vector__XXX
 SG_ ErrorRegisterProfileSpecific : 21|1@1+ (1,0) [0|0] "" Vector__XXX
 SG_ ErrorRegisterCommunication : 20|1@1+ (1,0) [0|0] "" Vector__XXX
 SG_ ErrorRegisterTemperature : 19|1@1+ (1,0) [0|0] "" Vector__XXX
 SG_ ErrorRegisterVoltage : 18|1@1+ (1,0) [0|0] "" Vector__XXX
 SG_ ErrorRegisterCurrent : 17|1@1+ (1,0) [0|0] "" Vector__XXX
 SG_ ErrorRegisterGeneric : 16|1@1+ (1,0) [0|0] "" Vector__XXX
 SG_ ErrorCode : 0|16@1+ (1,0) [0|0] "" Vector__XXX

BO_ 1886 HBGuard_094: 1 Vector__XXX
 SG_ Toggle : 7|1@1+ (1,0) [0|0] "" Vector__XXX
 SG_ State : 0|7@1+ (1,0) [0|0] "" Vector__XXX

BO_ 1502 SSDO_094: 8 Vector__XXX

BO_ 1630 CSDO_094: 8 Vector__XXX

BO_ 222 EMCY_094: 8 Vector__XXX
 SG_ ManufacturerSpecific5 : 56|8@1+ (1,0) [0|0] "" Vector__XXX
 SG_ ManufacturerSpecific4 : 48|8@1+ (1,0) [0|0] "" Vector__XXX
 SG_ ManufacturerSpecific3 : 40|8@1+ (1,0) [0|0] "" Vector__XXX
 SG_ ManufacturerSpecific2 : 32|8@1+ (1,0) [0|0] "" Vector__XXX
 SG_ ManufacturerSpecific1 : 24|8@1+ (1,0) [0|0] "" Vector__XXX
 SG_ ErrorRegisterManufSpecific : 23|1@1+ (1,0) [0|0] "" Vector__XXX
 SG_ ErrorRegisterReserved : 22|1@1+ (1,0) [0|0] "" Vector__XXX
 SG_ ErrorRegisterProfileSpecific : 21|1@1+ (1,0) [0|0] "" Vector__XXX
 SG_ ErrorRegisterCommunication : 20|1@1+ (1,0) [0|0] "" Vector__XXX
 SG_ ErrorRegisterTemperature : 19|1@1+ (1,0) [0|0] "" Vector__XXX
 SG_ ErrorRegisterVoltage : 18|1@1+ (1,0) [0|0] "" Vector__XXX
 SG_ ErrorRegisterCurrent : 17|1@1+ (1,0) [0|0] "" Vector__XXX
 SG_ ErrorRegisterGeneric : 16|1@1+ (1,0) [0|0] "" Vector__XXX
 SG_ ErrorCode : 0|16@1+ (1,0) [0|0] "" Vector__XXX

BO_ 1885 HBGuard_093: 1 Vector__XXX
 SG_ Toggle : 7|1@1+ (1,0) [0|0] "" Vector__XXX
 SG_ State : 0|7@1+ (1,0) [0|0] "" Vector__XXX

BO_ 1501 SSDO_093: 8 Vector__XXX

BO_ 1629 CSDO_093: 8 Vector__XXX

BO_ 221 EMCY_093: 8 Vector__XXX
 SG_ ManufacturerSpecific5 : 56|8@1+ (1,0) [0|0] "" Vector__XXX
 SG_ ManufacturerSpecific4 : 48|8@1+ (1,0) [0|0] "" Vector__XXX
 SG_ ManufacturerSpecific3 : 40|8@1+ (1,0) [0|0] "" Vector__XXX
 SG_ ManufacturerSpecific2 : 32|8@1+ (1,0) [0|0] "" Vector__XXX
 SG_ ManufacturerSpecific1 : 24|8@1+ (1,0) [0|0] "" Vector__XXX
 SG_ ErrorRegisterManufSpecific : 23|1@1+ (1,0) [0|0] "" Vector__XXX
 SG_ ErrorRegisterReserved : 22|1@1+ (1,0) [0|0] "" Vector__XXX
 SG_ ErrorRegisterProfileSpecific : 21|1@1+ (1,0) [0|0] "" Vector__XXX
 SG_ ErrorRegisterCommunication : 20|1@1+ (1,0) [0|0] "" Vector__XXX
 SG_ ErrorRegisterTemperature : 19|1@1+ (1,0) [0|0] "" Vector__XXX
 SG_ ErrorRegisterVoltage : 18|1@1+ (1,0) [0|0] "" Vector__XXX
 SG_ ErrorRegisterCurrent : 17|1@1+ (1,0) [0|0] "" Vector__XXX
 SG_ ErrorRegisterGeneric : 16|1@1+ (1,0) [0|0] "" Vector__XXX
 SG_ ErrorCode : 0|16@1+ (1,0) [0|0] "" Vector__XXX

BO_ 1884 HBGuard_092: 1 Vector__XXX
 SG_ Toggle : 7|1@1+ (1,0) [0|0] "" Vector__XXX
 SG_ State : 0|7@1+ (1,0) [0|0] "" Vector__XXX

BO_ 1500 SSDO_092: 8 Vector__XXX

BO_ 1628 CSDO_092: 8 Vector__XXX

BO_ 220 EMCY_092: 8 Vector__XXX
 SG_ ManufacturerSpecific5 : 56|8@1+ (1,0) [0|0] "" Vector__XXX
 SG_ ManufacturerSpecific4 : 48|8@1+ (1,0) [0|0] "" Vector__XXX
 SG_ ManufacturerSpecific3 : 40|8@1+ (1,0) [0|0] "" Vector__XXX
 SG_ ManufacturerSpecific2 : 32|8@1+ (1,0) [0|0] "" Vector__XXX
 SG_ ManufacturerSpecific1 : 24|8@1+ (1,0) [0|0] "" Vector__XXX
 SG_ ErrorRegisterManufSpecific : 23|1@1+ (1,0) [0|0] "" Vector__XXX
 SG_ ErrorRegisterReserved : 22|1@1+ (1,0) [0|0] "" Vector__XXX
 SG_ ErrorRegisterProfileSpecific : 21|1@1+ (1,0) [0|0] "" Vector__XXX
 SG_ ErrorRegisterCommunication : 20|1@1+ (1,0) [0|0] "" Vector__XXX
 SG_ ErrorRegisterTemperature : 19|1@1+ (1,0) [0|0] "" Vector__XXX
 SG_ ErrorRegisterVoltage : 18|1@1+ (1,0) [0|0] "" Vector__XXX
 SG_ ErrorRegisterCurrent : 17|1@1+ (1,0) [0|0] "" Vector__XXX
 SG_ ErrorRegisterGeneric : 16|1@1+ (1,0) [0|0] "" Vector__XXX
 SG_ ErrorCode : 0|16@1+ (1,0) [0|0] "" Vector__XXX

BO_ 1883 HBGuard_091: 1 Vector__XXX
 SG_ Toggle : 7|1@1+ (1,0) [0|0] "" Vector__XXX
 SG_ State : 0|7@1+ (1,0) [0|0] "" Vector__XXX

BO_ 1499 SSDO_091: 8 Vector__XXX

BO_ 1627 CSDO_091: 8 Vector__XXX

BO_ 219 EMCY_091: 8 Vector__XXX
 SG_ ManufacturerSpecific5 : 56|8@1+ (1,0) [0|0] "" Vector__XXX
 SG_ ManufacturerSpecific4 : 48|8@1+ (1,0) [0|0] "" Vector__XXX
 SG_ ManufacturerSpecific3 : 40|8@1+ (1,0) [0|0] "" Vector__XXX
 SG_ ManufacturerSpecific2 : 32|8@1+ (1,0) [0|0] "" Vector__XXX
 SG_ ManufacturerSpecific1 : 24|8@1+ (1,0) [0|0] "" Vector__XXX
 SG_ ErrorRegisterManufSpecific : 23|1@1+ (1,0) [0|0] "" Vector__XXX
 SG_ ErrorRegisterReserved : 22|1@1+ (1,0) [0|0] "" Vector__XXX
 SG_ ErrorRegisterProfileSpecific : 21|1@1+ (1,0) [0|0] "" Vector__XXX
 SG_ ErrorRegisterCommunication : 20|1@1+ (1,0) [0|0] "" Vector__XXX
 SG_ ErrorRegisterTemperature : 19|1@1+ (1,0) [0|0] "" Vector__XXX
 SG_ ErrorRegisterVoltage : 18|1@1+ (1,0) [0|0] "" Vector__XXX
 SG_ ErrorRegisterCurrent : 17|1@1+ (1,0) [0|0] "" Vector__XXX
 SG_ ErrorRegisterGeneric : 16|1@1+ (1,0) [0|0] "" Vector__XXX
 SG_ ErrorCode : 0|16@1+ (1,0) [0|0] "" Vector__XXX

BO_ 1882 HBGuard_090: 1 Vector__XXX
 SG_ Toggle : 7|1@1+ (1,0) [0|0] "" Vector__XXX
 SG_ State : 0|7@1+ (1,0) [0|0] "" Vector__XXX

BO_ 1498 SSDO_090: 8 Vector__XXX

BO_ 1626 CSDO_090: 8 Vector__XXX

BO_ 218 EMCY_090: 8 Vector__XXX
 SG_ ManufacturerSpecific5 : 56|8@1+ (1,0) [0|0] "" Vector__XXX
 SG_ ManufacturerSpecific4 : 48|8@1+ (1,0) [0|0] "" Vector__XXX
 SG_ ManufacturerSpecific3 : 40|8@1+ (1,0) [0|0] "" Vector__XXX
 SG_ ManufacturerSpecific2 : 32|8@1+ (1,0) [0|0] "" Vector__XXX
 SG_ ManufacturerSpecific1 : 24|8@1+ (1,0) [0|0] "" Vector__XXX
 SG_ ErrorRegisterManufSpecific : 23|1@1+ (1,0) [0|0] "" Vector__XXX
 SG_ ErrorRegisterReserved : 22|1@1+ (1,0) [0|0] "" Vector__XXX
 SG_ ErrorRegisterProfileSpecific : 21|1@1+ (1,0) [0|0] "" Vector__XXX
 SG_ ErrorRegisterCommunication : 20|1@1+ (1,0) [0|0] "" Vector__XXX
 SG_ ErrorRegisterTemperature : 19|1@1+ (1,0) [0|0] "" Vector__XXX
 SG_ ErrorRegisterVoltage : 18|1@1+ (1,0) [0|0] "" Vector__XXX
 SG_ ErrorRegisterCurrent : 17|1@1+ (1,0) [0|0] "" Vector__XXX
 SG_ ErrorRegisterGeneric : 16|1@1+ (1,0) [0|0] "" Vector__XXX
 SG_ ErrorCode : 0|16@1+ (1,0) [0|0] "" Vector__XXX

BO_ 1881 HBGuard_089: 1 Vector__XXX
 SG_ Toggle : 7|1@1+ (1,0) [0|0] "" Vector__XXX
 SG_ State : 0|7@1+ (1,0) [0|0] "" Vector__XXX

BO_ 1497 SSDO_089: 8 Vector__XXX

BO_ 1625 CSDO_089: 8 Vector__XXX

BO_ 217 EMCY_089: 8 Vector__XXX
 SG_ ManufacturerSpecific5 : 56|8@1+ (1,0) [0|0] "" Vector__XXX
 SG_ ManufacturerSpecific4 : 48|8@1+ (1,0) [0|0] "" Vector__XXX
 SG_ ManufacturerSpecific3 : 40|8@1+ (1,0) [0|0] "" Vector__XXX
 SG_ ManufacturerSpecific2 : 32|8@1+ (1,0) [0|0] "" Vector__XXX
 SG_ ManufacturerSpecific1 : 24|8@1+ (1,0) [0|0] "" Vector__XXX
 SG_ ErrorRegisterManufSpecific : 23|1@1+ (1,0) [0|0] "" Vector__XXX
 SG_ ErrorRegisterReserved : 22|1@1+ (1,0) [0|0] "" Vector__XXX
 SG_ ErrorRegisterProfileSpecific : 21|1@1+ (1,0) [0|0] "" Vector__XXX
 SG_ ErrorRegisterCommunication : 20|1@1+ (1,0) [0|0] "" Vector__XXX
 SG_ ErrorRegisterTemperature : 19|1@1+ (1,0) [0|0] "" Vector__XXX
 SG_ ErrorRegisterVoltage : 18|1@1+ (1,0) [0|0] "" Vector__XXX
 SG_ ErrorRegisterCurrent : 17|1@1+ (1,0) [0|0] "" Vector__XXX
 SG_ ErrorRegisterGeneric : 16|1@1+ (1,0) [0|0] "" Vector__XXX
 SG_ ErrorCode : 0|16@1+ (1,0) [0|0] "" Vector__XXX

BO_ 1880 HBGuard_088: 1 Vector__XXX
 SG_ Toggle : 7|1@1+ (1,0) [0|0] "" Vector__XXX
 SG_ State : 0|7@1+ (1,0) [0|0] "" Vector__XXX

BO_ 1496 SSDO_088: 8 Vector__XXX

BO_ 1624 CSDO_088: 8 Vector__XXX

BO_ 216 EMCY_088: 8 Vector__XXX
 SG_ ManufacturerSpecific5 : 56|8@1+ (1,0) [0|0] "" Vector__XXX
 SG_ ManufacturerSpecific4 : 48|8@1+ (1,0) [0|0] "" Vector__XXX
 SG_ ManufacturerSpecific3 : 40|8@1+ (1,0) [0|0] "" Vector__XXX
 SG_ ManufacturerSpecific2 : 32|8@1+ (1,0) [0|0] "" Vector__XXX
 SG_ ManufacturerSpecific1 : 24|8@1+ (1,0) [0|0] "" Vector__XXX
 SG_ ErrorRegisterManufSpecific : 23|1@1+ (1,0) [0|0] "" Vector__XXX
 SG_ ErrorRegisterReserved : 22|1@1+ (1,0) [0|0] "" Vector__XXX
 SG_ ErrorRegisterProfileSpecific : 21|1@1+ (1,0) [0|0] "" Vector__XXX
 SG_ ErrorRegisterCommunication : 20|1@1+ (1,0) [0|0] "" Vector__XXX
 SG_ ErrorRegisterTemperature : 19|1@1+ (1,0) [0|0] "" Vector__XXX
 SG_ ErrorRegisterVoltage : 18|1@1+ (1,0) [0|0] "" Vector__XXX
 SG_ ErrorRegisterCurrent : 17|1@1+ (1,0) [0|0] "" Vector__XXX
 SG_ ErrorRegisterGeneric : 16|1@1+ (1,0) [0|0] "" Vector__XXX
 SG_ ErrorCode : 0|16@1+ (1,0) [0|0] "" Vector__XXX

BO_ 1879 HBGuard_087: 1 Vector__XXX
 SG_ Toggle : 7|1@1+ (1,0) [0|0] "" Vector__XXX
 SG_ State : 0|7@1+ (1,0) [0|0] "" Vector__XXX

BO_ 1495 SSDO_087: 8 Vector__XXX

BO_ 1623 CSDO_087: 8 Vector__XXX

BO_ 215 EMCY_087: 8 Vector__XXX
 SG_ ManufacturerSpecific5 : 56|8@1+ (1,0) [0|0] "" Vector__XXX
 SG_ ManufacturerSpecific4 : 48|8@1+ (1,0) [0|0] "" Vector__XXX
 SG_ ManufacturerSpecific3 : 40|8@1+ (1,0) [0|0] "" Vector__XXX
 SG_ ManufacturerSpecific2 : 32|8@1+ (1,0) [0|0] "" Vector__XXX
 SG_ ManufacturerSpecific1 : 24|8@1+ (1,0) [0|0] "" Vector__XXX
 SG_ ErrorRegisterManufSpecific : 23|1@1+ (1,0) [0|0] "" Vector__XXX
 SG_ ErrorRegisterReserved : 22|1@1+ (1,0) [0|0] "" Vector__XXX
 SG_ ErrorRegisterProfileSpecific : 21|1@1+ (1,0) [0|0] "" Vector__XXX
 SG_ ErrorRegisterCommunication : 20|1@1+ (1,0) [0|0] "" Vector__XXX
 SG_ ErrorRegisterTemperature : 19|1@1+ (1,0) [0|0] "" Vector__XXX
 SG_ ErrorRegisterVoltage : 18|1@1+ (1,0) [0|0] "" Vector__XXX
 SG_ ErrorRegisterCurrent : 17|1@1+ (1,0) [0|0] "" Vector__XXX
 SG_ ErrorRegisterGeneric : 16|1@1+ (1,0) [0|0] "" Vector__XXX
 SG_ ErrorCode : 0|16@1+ (1,0) [0|0] "" Vector__XXX

BO_ 1878 HBGuard_086: 1 Vector__XXX
 SG_ Toggle : 7|1@1+ (1,0) [0|0] "" Vector__XXX
 SG_ State : 0|7@1+ (1,0) [0|0] "" Vector__XXX

BO_ 1494 SSDO_086: 8 Vector__XXX

BO_ 1622 CSDO_086: 8 Vector__XXX

BO_ 214 EMCY_086: 8 Vector__XXX
 SG_ ManufacturerSpecific5 : 56|8@1+ (1,0) [0|0] "" Vector__XXX
 SG_ ManufacturerSpecific4 : 48|8@1+ (1,0) [0|0] "" Vector__XXX
 SG_ ManufacturerSpecific3 : 40|8@1+ (1,0) [0|0] "" Vector__XXX
 SG_ ManufacturerSpecific2 : 32|8@1+ (1,0) [0|0] "" Vector__XXX
 SG_ ManufacturerSpecific1 : 24|8@1+ (1,0) [0|0] "" Vector__XXX
 SG_ ErrorRegisterManufSpecific : 23|1@1+ (1,0) [0|0] "" Vector__XXX
 SG_ ErrorRegisterReserved : 22|1@1+ (1,0) [0|0] "" Vector__XXX
 SG_ ErrorRegisterProfileSpecific : 21|1@1+ (1,0) [0|0] "" Vector__XXX
 SG_ ErrorRegisterCommunication : 20|1@1+ (1,0) [0|0] "" Vector__XXX
 SG_ ErrorRegisterTemperature : 19|1@1+ (1,0) [0|0] "" Vector__XXX
 SG_ ErrorRegisterVoltage : 18|1@1+ (1,0) [0|0] "" Vector__XXX
 SG_ ErrorRegisterCurrent : 17|1@1+ (1,0) [0|0] "" Vector__XXX
 SG_ ErrorRegisterGeneric : 16|1@1+ (1,0) [0|0] "" Vector__XXX
 SG_ ErrorCode : 0|16@1+ (1,0) [0|0] "" Vector__XXX

BO_ 1877 HBGuard_085: 1 Vector__XXX
 SG_ Toggle : 7|1@1+ (1,0) [0|0] "" Vector__XXX
 SG_ State : 0|7@1+ (1,0) [0|0] "" Vector__XXX

BO_ 1493 SSDO_085: 8 Vector__XXX

BO_ 1621 CSDO_085: 8 Vector__XXX

BO_ 213 EMCY_085: 8 Vector__XXX
 SG_ ManufacturerSpecific5 : 56|8@1+ (1,0) [0|0] "" Vector__XXX
 SG_ ManufacturerSpecific4 : 48|8@1+ (1,0) [0|0] "" Vector__XXX
 SG_ ManufacturerSpecific3 : 40|8@1+ (1,0) [0|0] "" Vector__XXX
 SG_ ManufacturerSpecific2 : 32|8@1+ (1,0) [0|0] "" Vector__XXX
 SG_ ManufacturerSpecific1 : 24|8@1+ (1,0) [0|0] "" Vector__XXX
 SG_ ErrorRegisterManufSpecific : 23|1@1+ (1,0) [0|0] "" Vector__XXX
 SG_ ErrorRegisterReserved : 22|1@1+ (1,0) [0|0] "" Vector__XXX
 SG_ ErrorRegisterProfileSpecific : 21|1@1+ (1,0) [0|0] "" Vector__XXX
 SG_ ErrorRegisterCommunication : 20|1@1+ (1,0) [0|0] "" Vector__XXX
 SG_ ErrorRegisterTemperature : 19|1@1+ (1,0) [0|0] "" Vector__XXX
 SG_ ErrorRegisterVoltage : 18|1@1+ (1,0) [0|0] "" Vector__XXX
 SG_ ErrorRegisterCurrent : 17|1@1+ (1,0) [0|0] "" Vector__XXX
 SG_ ErrorRegisterGeneric : 16|1@1+ (1,0) [0|0] "" Vector__XXX
 SG_ ErrorCode : 0|16@1+ (1,0) [0|0] "" Vector__XXX

BO_ 1876 HBGuard_084: 1 Vector__XXX
 SG_ Toggle : 7|1@1+ (1,0) [0|0] "" Vector__XXX
 SG_ State : 0|7@1+ (1,0) [0|0] "" Vector__XXX

BO_ 1492 SSDO_084: 8 Vector__XXX

BO_ 1620 CSDO_084: 8 Vector__XXX

BO_ 212 EMCY_084: 8 Vector__XXX
 SG_ ManufacturerSpecific5 : 56|8@1+ (1,0) [0|0] "" Vector__XXX
 SG_ ManufacturerSpecific4 : 48|8@1+ (1,0) [0|0] "" Vector__XXX
 SG_ ManufacturerSpecific3 : 40|8@1+ (1,0) [0|0] "" Vector__XXX
 SG_ ManufacturerSpecific2 : 32|8@1+ (1,0) [0|0] "" Vector__XXX
 SG_ ManufacturerSpecific1 : 24|8@1+ (1,0) [0|0] "" Vector__XXX
 SG_ ErrorRegisterManufSpecific : 23|1@1+ (1,0) [0|0] "" Vector__XXX
 SG_ ErrorRegisterReserved : 22|1@1+ (1,0) [0|0] "" Vector__XXX
 SG_ ErrorRegisterProfileSpecific : 21|1@1+ (1,0) [0|0] "" Vector__XXX
 SG_ ErrorRegisterCommunication : 20|1@1+ (1,0) [0|0] "" Vector__XXX
 SG_ ErrorRegisterTemperature : 19|1@1+ (1,0) [0|0] "" Vector__XXX
 SG_ ErrorRegisterVoltage : 18|1@1+ (1,0) [0|0] "" Vector__XXX
 SG_ ErrorRegisterCurrent : 17|1@1+ (1,0) [0|0] "" Vector__XXX
 SG_ ErrorRegisterGeneric : 16|1@1+ (1,0) [0|0] "" Vector__XXX
 SG_ ErrorCode : 0|16@1+ (1,0) [0|0] "" Vector__XXX

BO_ 1875 HBGuard_083: 1 Vector__XXX
 SG_ Toggle : 7|1@1+ (1,0) [0|0] "" Vector__XXX
 SG_ State : 0|7@1+ (1,0) [0|0] "" Vector__XXX

BO_ 1491 SSDO_083: 8 Vector__XXX

BO_ 1619 CSDO_083: 8 Vector__XXX

BO_ 211 EMCY_083: 8 Vector__XXX
 SG_ ManufacturerSpecific5 : 56|8@1+ (1,0) [0|0] "" Vector__XXX
 SG_ ManufacturerSpecific4 : 48|8@1+ (1,0) [0|0] "" Vector__XXX
 SG_ ManufacturerSpecific3 : 40|8@1+ (1,0) [0|0] "" Vector__XXX
 SG_ ManufacturerSpecific2 : 32|8@1+ (1,0) [0|0] "" Vector__XXX
 SG_ ManufacturerSpecific1 : 24|8@1+ (1,0) [0|0] "" Vector__XXX
 SG_ ErrorRegisterManufSpecific : 23|1@1+ (1,0) [0|0] "" Vector__XXX
 SG_ ErrorRegisterReserved : 22|1@1+ (1,0) [0|0] "" Vector__XXX
 SG_ ErrorRegisterProfileSpecific : 21|1@1+ (1,0) [0|0] "" Vector__XXX
 SG_ ErrorRegisterCommunication : 20|1@1+ (1,0) [0|0] "" Vector__XXX
 SG_ ErrorRegisterTemperature : 19|1@1+ (1,0) [0|0] "" Vector__XXX
 SG_ ErrorRegisterVoltage : 18|1@1+ (1,0) [0|0] "" Vector__XXX
 SG_ ErrorRegisterCurrent : 17|1@1+ (1,0) [0|0] "" Vector__XXX
 SG_ ErrorRegisterGeneric : 16|1@1+ (1,0) [0|0] "" Vector__XXX
 SG_ ErrorCode : 0|16@1+ (1,0) [0|0] "" Vector__XXX

BO_ 1874 HBGuard_082: 1 Vector__XXX
 SG_ Toggle : 7|1@1+ (1,0) [0|0] "" Vector__XXX
 SG_ State : 0|7@1+ (1,0) [0|0] "" Vector__XXX

BO_ 1490 SSDO_082: 8 Vector__XXX

BO_ 1618 CSDO_082: 8 Vector__XXX

BO_ 210 EMCY_082: 8 Vector__XXX
 SG_ ManufacturerSpecific5 : 56|8@1+ (1,0) [0|0] "" Vector__XXX
 SG_ ManufacturerSpecific4 : 48|8@1+ (1,0) [0|0] "" Vector__XXX
 SG_ ManufacturerSpecific3 : 40|8@1+ (1,0) [0|0] "" Vector__XXX
 SG_ ManufacturerSpecific2 : 32|8@1+ (1,0) [0|0] "" Vector__XXX
 SG_ ManufacturerSpecific1 : 24|8@1+ (1,0) [0|0] "" Vector__XXX
 SG_ ErrorRegisterManufSpecific : 23|1@1+ (1,0) [0|0] "" Vector__XXX
 SG_ ErrorRegisterReserved : 22|1@1+ (1,0) [0|0] "" Vector__XXX
 SG_ ErrorRegisterProfileSpecific : 21|1@1+ (1,0) [0|0] "" Vector__XXX
 SG_ ErrorRegisterCommunication : 20|1@1+ (1,0) [0|0] "" Vector__XXX
 SG_ ErrorRegisterTemperature : 19|1@1+ (1,0) [0|0] "" Vector__XXX
 SG_ ErrorRegisterVoltage : 18|1@1+ (1,0) [0|0] "" Vector__XXX
 SG_ ErrorRegisterCurrent : 17|1@1+ (1,0) [0|0] "" Vector__XXX
 SG_ ErrorRegisterGeneric : 16|1@1+ (1,0) [0|0] "" Vector__XXX
 SG_ ErrorCode : 0|16@1+ (1,0) [0|0] "" Vector__XXX

BO_ 1873 HBGuard_081: 1 Vector__XXX
 SG_ Toggle : 7|1@1+ (1,0) [0|0] "" Vector__XXX
 SG_ State : 0|7@1+ (1,0) [0|0] "" Vector__XXX

BO_ 1489 SSDO_081: 8 Vector__XXX

BO_ 1617 CSDO_081: 8 Vector__XXX

BO_ 209 EMCY_081: 8 Vector__XXX
 SG_ ManufacturerSpecific5 : 56|8@1+ (1,0) [0|0] "" Vector__XXX
 SG_ ManufacturerSpecific4 : 48|8@1+ (1,0) [0|0] "" Vector__XXX
 SG_ ManufacturerSpecific3 : 40|8@1+ (1,0) [0|0] "" Vector__XXX
 SG_ ManufacturerSpecific2 : 32|8@1+ (1,0) [0|0] "" Vector__XXX
 SG_ ManufacturerSpecific1 : 24|8@1+ (1,0) [0|0] "" Vector__XXX
 SG_ ErrorRegisterManufSpecific : 23|1@1+ (1,0) [0|0] "" Vector__XXX
 SG_ ErrorRegisterReserved : 22|1@1+ (1,0) [0|0] "" Vector__XXX
 SG_ ErrorRegisterProfileSpecific : 21|1@1+ (1,0) [0|0] "" Vector__XXX
 SG_ ErrorRegisterCommunication : 20|1@1+ (1,0) [0|0] "" Vector__XXX
 SG_ ErrorRegisterTemperature : 19|1@1+ (1,0) [0|0] "" Vector__XXX
 SG_ ErrorRegisterVoltage : 18|1@1+ (1,0) [0|0] "" Vector__XXX
 SG_ ErrorRegisterCurrent : 17|1@1+ (1,0) [0|0] "" Vector__XXX
 SG_ ErrorRegisterGeneric : 16|1@1+ (1,0) [0|0] "" Vector__XXX
 SG_ ErrorCode : 0|16@1+ (1,0) [0|0] "" Vector__XXX

BO_ 1872 HBGuard_080: 1 Vector__XXX
 SG_ Toggle : 7|1@1+ (1,0) [0|0] "" Vector__XXX
 SG_ State : 0|7@1+ (1,0) [0|0] "" Vector__XXX

BO_ 1488 SSDO_080: 8 Vector__XXX

BO_ 1616 CSDO_080: 8 Vector__XXX

BO_ 208 EMCY_080: 8 Vector__XXX
 SG_ ManufacturerSpecific5 : 56|8@1+ (1,0) [0|0] "" Vector__XXX
 SG_ ManufacturerSpecific4 : 48|8@1+ (1,0) [0|0] "" Vector__XXX
 SG_ ManufacturerSpecific3 : 40|8@1+ (1,0) [0|0] "" Vector__XXX
 SG_ ManufacturerSpecific2 : 32|8@1+ (1,0) [0|0] "" Vector__XXX
 SG_ ManufacturerSpecific1 : 24|8@1+ (1,0) [0|0] "" Vector__XXX
 SG_ ErrorRegisterManufSpecific : 23|1@1+ (1,0) [0|0] "" Vector__XXX
 SG_ ErrorRegisterReserved : 22|1@1+ (1,0) [0|0] "" Vector__XXX
 SG_ ErrorRegisterProfileSpecific : 21|1@1+ (1,0) [0|0] "" Vector__XXX
 SG_ ErrorRegisterCommunication : 20|1@1+ (1,0) [0|0] "" Vector__XXX
 SG_ ErrorRegisterTemperature : 19|1@1+ (1,0) [0|0] "" Vector__XXX
 SG_ ErrorRegisterVoltage : 18|1@1+ (1,0) [0|0] "" Vector__XXX
 SG_ ErrorRegisterCurrent : 17|1@1+ (1,0) [0|0] "" Vector__XXX
 SG_ ErrorRegisterGeneric : 16|1@1+ (1,0) [0|0] "" Vector__XXX
 SG_ ErrorCode : 0|16@1+ (1,0) [0|0] "" Vector__XXX

BO_ 1871 HBGuard_079: 1 Vector__XXX
 SG_ Toggle : 7|1@1+ (1,0) [0|0] "" Vector__XXX
 SG_ State : 0|7@1+ (1,0) [0|0] "" Vector__XXX

BO_ 1487 SSDO_079: 8 Vector__XXX

BO_ 1615 CSDO_079: 8 Vector__XXX

BO_ 207 EMCY_079: 8 Vector__XXX
 SG_ ManufacturerSpecific5 : 56|8@1+ (1,0) [0|0] "" Vector__XXX
 SG_ ManufacturerSpecific4 : 48|8@1+ (1,0) [0|0] "" Vector__XXX
 SG_ ManufacturerSpecific3 : 40|8@1+ (1,0) [0|0] "" Vector__XXX
 SG_ ManufacturerSpecific2 : 32|8@1+ (1,0) [0|0] "" Vector__XXX
 SG_ ManufacturerSpecific1 : 24|8@1+ (1,0) [0|0] "" Vector__XXX
 SG_ ErrorRegisterManufSpecific : 23|1@1+ (1,0) [0|0] "" Vector__XXX
 SG_ ErrorRegisterReserved : 22|1@1+ (1,0) [0|0] "" Vector__XXX
 SG_ ErrorRegisterProfileSpecific : 21|1@1+ (1,0) [0|0] "" Vector__XXX
 SG_ ErrorRegisterCommunication : 20|1@1+ (1,0) [0|0] "" Vector__XXX
 SG_ ErrorRegisterTemperature : 19|1@1+ (1,0) [0|0] "" Vector__XXX
 SG_ ErrorRegisterVoltage : 18|1@1+ (1,0) [0|0] "" Vector__XXX
 SG_ ErrorRegisterCurrent : 17|1@1+ (1,0) [0|0] "" Vector__XXX
 SG_ ErrorRegisterGeneric : 16|1@1+ (1,0) [0|0] "" Vector__XXX
 SG_ ErrorCode : 0|16@1+ (1,0) [0|0] "" Vector__XXX

BO_ 1870 HBGuard_078: 1 Vector__XXX
 SG_ Toggle : 7|1@1+ (1,0) [0|0] "" Vector__XXX
 SG_ State : 0|7@1+ (1,0) [0|0] "" Vector__XXX

BO_ 1486 SSDO_078: 8 Vector__XXX

BO_ 1614 CSDO_078: 8 Vector__XXX

BA_DEF_ BU_  "CO_DCF" STRING ;
BA_DEF_ BU_  "CO_ID" INT 0 127;
BA_DEF_ BU_  "CO_NVSEGMENT0" STRING ;
BA_DEF_ BU_  "CO_NVSEGMENT1" STRING ;
BA_DEF_ BU_  "CO_NVSEGMENT2" STRING ;
BA_DEF_ BU_  "CO_NVSEGMENT3" STRING ;
BA_DEF_ BU_  "CO_NVSEGMENT4" STRING ;
BA_DEF_ BU_  "CO_NVSEGMENT5" STRING ;
BA_DEF_ BU_  "CO_NVSEGMENT6" STRING ;
BA_DEF_ BU_  "CO_NVSEGMENT7" STRING ;
BA_DEF_ BU_  "CO_NVSEGMENT8" STRING ;
BA_DEF_ BU_  "CO_NVSEGMENT9" STRING ;
BA_DEF_ BU_  "CO_NVSEGMENT10" STRING ;
BA_DEF_ BU_  "CO_NVSEGMENT11" STRING ;
BA_DEF_ BU_  "CO_NVSEGMENT12" STRING ;
BA_DEF_ BU_  "CO_NVSEGMENT13" STRING ;
BA_DEF_ BU_  "CO_NVSEGMENT14" STRING ;
BA_DEF_ BU_  "CO_NVSEGMENT15" STRING ;
BA_DEF_ BU_  "CO_NVSEGMENT16" STRING ;
BA_DEF_ BU_  "CO_NVSEGMENT17" STRING ;
BA_DEF_ BU_  "CO_NVSEGMENT18" STRING ;
BA_DEF_ BU_  "CO_NVSEGMENT19" STRING ;
BA_DEF_ BU_  "CO_NVSEGMENT20" STRING ;
BA_DEF_ BU_  "CO_NVSEGMENT21" STRING ;
BA_DEF_ BU_  "CO_NVSEGMENT22" STRING ;
BA_DEF_ BU_  "CO_NVSEGMENT23" STRING ;
BA_DEF_ BU_  "CO_NVSEGMENT24" STRING ;
BA_DEF_ BU_  "CO_NVSEGMENT25" STRING ;
BA_DEF_ BU_  "CO_NVSEGMENT26" STRING ;
BA_DEF_ BU_  "CO_NVSEGMENT27" STRING ;
BA_DEF_ BU_  "CO_NVSEGMENT28" STRING ;
BA_DEF_ BU_  "CO_NVSEGMENT29" STRING ;
BA_DEF_ BU_  "CO_NVSEGMENT30" STRING ;
BA_DEF_ BU_  "CO_NVSEGMENT31" STRING ;
BA_DEF_ BU_  "CO_NVSEGMENT32" STRING ;
BA_DEF_ BU_  "CO_NVSEGMENT33" STRING ;
BA_DEF_ BU_  "CO_NVSEGMENT34" STRING ;
BA_DEF_ BU_  "CO_NVSEGMENT35" STRING ;
BA_DEF_ BU_  "CO_NVSEGMENT36" STRING ;
BA_DEF_ BU_  "CO_NVSEGMENT37" STRING ;
BA_DEF_ BU_  "CO_NVSEGMENT38" STRING ;
BA_DEF_ BU_  "CO_NVSEGMENT39" STRING ;
BA_DEF_ BU_  "CO_NVSEGMENT40" STRING ;
BA_DEF_ BU_  "CO_NVSEGMENT41" STRING ;
BA_DEF_ BU_  "CO_NVSEGMENT42" STRING ;
BA_DEF_ BU_  "CO_NVSEGMENT43" STRING ;
BA_DEF_ BU_  "CO_NVSEGMENT44" STRING ;
BA_DEF_ BU_  "CO_NVSEGMENT45" STRING ;
BA_DEF_  "OptionLoadDCF" INT 0 1;
BA_DEF_ BO_  "GenMsgSendType" ENUM  "Cyclic","SendType1","SendType2","SendType3","SendType4","SendType5","SendType6","SendType7","SendType8","SendType9";
BA_DEF_ SG_  "GenSigStartValue" INT 0 0;
BA_DEF_ BO_  "CO_MsgCategory" INT 0 0;
BA_DEF_  "CO_MsgColourSupported" INT 0 1;
BA_DEF_  "GeneratedBy" STRING ;
BA_DEF_  "CANopenApplProfile" INT 0 0;
BA_DEF_  "ProtocolType" STRING ;
BA_DEF_  "AUTOGENERATION" INT 0 1;
BA_DEF_DEF_  "CO_DCF" "";
BA_DEF_DEF_  "CO_ID" 0;
BA_DEF_DEF_  "CO_NVSEGMENT0" "";
BA_DEF_DEF_  "CO_NVSEGMENT1" "";
BA_DEF_DEF_  "CO_NVSEGMENT2" "";
BA_DEF_DEF_  "CO_NVSEGMENT3" "";
BA_DEF_DEF_  "CO_NVSEGMENT4" "";
BA_DEF_DEF_  "CO_NVSEGMENT5" "";
BA_DEF_DEF_  "CO_NVSEGMENT6" "";
BA_DEF_DEF_  "CO_NVSEGMENT7" "";
BA_DEF_DEF_  "CO_NVSEGMENT8" "";
BA_DEF_DEF_  "CO_NVSEGMENT9" "";
BA_DEF_DEF_  "CO_NVSEGMENT10" "";
BA_DEF_DEF_  "CO_NVSEGMENT11" "";
BA_DEF_DEF_  "CO_NVSEGMENT12" "";
BA_DEF_DEF_  "CO_NVSEGMENT13" "";
BA_DEF_DEF_  "CO_NVSEGMENT14" "";
BA_DEF_DEF_  "CO_NVSEGMENT15" "";
BA_DEF_DEF_  "CO_NVSEGMENT16" "";
BA_DEF_DEF_  "CO_NVSEGMENT17" "";
BA_DEF_DEF_  "CO_NVSEGMENT18" "";
BA_DEF_DEF_  "CO_NVSEGMENT19" "";
BA_DEF_DEF_  "CO_NVSEGMENT20" "";
BA_DEF_DEF_  "CO_NVSEGMENT21" "";
BA_DEF_DEF_  "CO_NVSEGMENT22" "";
BA_DEF_DEF_  "CO_NVSEGMENT23" "";
BA_DEF_DEF_  "CO_NVSEGMENT24" "";
BA_DEF_DEF_  "CO_NVSEGMENT25" "";
BA_DEF_DEF_  "CO_NVSEGMENT26" "";
BA_DEF_DEF_  "CO_NVSEGMENT27" "";
BA_DEF_DEF_  "CO_NVSEGMENT28" "";
BA_DEF_DEF_  "CO_NVSEGMENT29" "";
BA_DEF_DEF_  "CO_NVSEGMENT30" "";
BA_DEF_DEF_  "CO_NVSEGMENT31" "";
BA_DEF_DEF_  "CO_NVSEGMENT32" "";
BA_DEF_DEF_  "CO_NVSEGMENT33" "";
BA_DEF_DEF_  "CO_NVSEGMENT34" "";
BA_DEF_DEF_  "CO_NVSEGMENT35" "";
BA_DEF_DEF_  "CO_NVSEGMENT36" "";
BA_DEF_DEF_  "CO_NVSEGMENT37" "";
BA_DEF_DEF_  "CO_NVSEGMENT38" "";
BA_DEF_DEF_  "CO_NVSEGMENT39" "";
BA_DEF_DEF_  "CO_NVSEGMENT40" "";
BA_DEF_DEF_  "CO_NVSEGMENT41" "";
BA_DEF_DEF_  "CO_NVSEGMENT42" "";
BA_DEF_DEF_  "CO_NVSEGMENT43" "";
BA_DEF_DEF_  "CO_NVSEGMENT44" "";
BA_DEF_DEF_  "CO_NVSEGMENT45" "";
BA_DEF_DEF_  "OptionLoadDCF" 0;
BA_DEF_DEF_  "GenMsgSendType" "(null)";
BA_DEF_DEF_  "GenSigStartValue" 0;
BA_DEF_DEF_  "CO_MsgCategory" 0;
BA_DEF_DEF_  "CO_MsgColourSupported" 1;
BA_DEF_DEF_  "GeneratedBy" "";
BA_DEF_DEF_  "CANopenApplProfile" 301;
BA_DEF_DEF_  "ProtocolType" "CANopen";
BA_DEF_DEF_  "AUTOGENERATION" 0;
BA_ "AUTOGENERATION" 1;
BA_ "GeneratedBy" "Vector ProCANopen";
BA_ "CO_ID" BU_ BMS_5_1 35;
BA_ "CO_DCF" BU_ BMS_5_1 "..\D035.DCF";
BA_ "CO_ID" BU_ BMS_4_1 34;
BA_ "CO_DCF" BU_ BMS_4_1 "..\D034.DCF";
BA_ "CO_ID" BU_ BMS_3_1 33;
BA_ "CO_DCF" BU_ BMS_3_1 "..\D033.DCF";
BA_ "CO_ID" BU_ BMS_2_1 32;
BA_ "CO_DCF" BU_ BMS_2_1 "..\D032.DCF";
BA_ "CO_ID" BU_ BMS_1_1 31;
BA_ "CO_DCF" BU_ BMS_1_1 "..\D031.DCF";
BA_ "CO_ID" BU_ BMS_0_1 30;
BA_ "CO_DCF" BU_ BMS_0_1 "..\D030.DCF";
BA_ "CO_ID" BU_ BMS_5_0 25;
BA_ "CO_DCF" BU_ BMS_5_0 "..\D025.DCF";
BA_ "CO_ID" BU_ BMS_4_0 24;
BA_ "CO_DCF" BU_ BMS_4_0 "..\D024.DCF";
BA_ "CO_ID" BU_ BMS_3_0 23;
BA_ "CO_DCF" BU_ BMS_3_0 "..\D023.DCF";
BA_ "CO_ID" BU_ BMS_2_0 22;
BA_ "CO_DCF" BU_ BMS_2_0 "..\D022.DCF";
BA_ "CO_ID" BU_ BMS_1_0 21;
BA_ "CO_DCF" BU_ BMS_1_0 "..\D021.DCF";
BA_ "CO_ID" BU_ BMS_0_0 20;
BA_ "CO_DCF" BU_ BMS_0_0 "..\D020.DCF";
BA_ "CO_ID" BU_ IMU 17;
BA_ "CO_DCF" BU_ IMU "..\D017.DCF";
BA_ "CO_ID" BU_ PVC 16;
BA_ "CO_DCF" BU_ PVC "..\D016.DCF";
BA_ "CO_ID" BU_ Thermocouple 9;
BA_ "CO_DCF" BU_ Thermocouple "..\D009.DCF";
BA_ "CO_ID" BU_ TMS 8;
BA_ "CO_DCF" BU_ TMS "..\D008.DCF";
BA_ "CO_ID" BU_ MC 1;
BA_ "CO_DCF" BU_ MC "..\D001.DCF";
BA_ "CO_MsgCategory" BO_ 1827 505;
BA_ "CO_MsgCategory" BO_ 1443 410;
BA_ "CO_MsgCategory" BO_ 1571 405;
BA_ "CO_MsgCategory" BO_ 163 205;
BA_ "CO_MsgCategory" BO_ 1826 505;
BA_ "CO_MsgCategory" BO_ 1442 410;
BA_ "CO_MsgCategory" BO_ 1570 405;
BA_ "CO_MsgCategory" BO_ 162 205;
BA_ "CO_MsgCategory" BO_ 1825 505;
BA_ "CO_MsgCategory" BO_ 1441 410;
BA_ "CO_MsgCategory" BO_ 1569 405;
BA_ "CO_MsgCategory" BO_ 161 205;
BA_ "CO_MsgCategory" BO_ 1824 505;
BA_ "CO_MsgCategory" BO_ 1440 410;
BA_ "CO_MsgCategory" BO_ 1568 405;
BA_ "CO_MsgCategory" BO_ 160 205;
BA_ "CO_MsgCategory" BO_ 1823 505;
BA_ "CO_MsgCategory" BO_ 1439 410;
BA_ "CO_MsgCategory" BO_ 1567 405;
BA_ "CO_MsgCategory" BO_ 159 205;
BA_ "CO_MsgCategory" BO_ 1822 505;
BA_ "CO_MsgCategory" BO_ 1438 410;
BA_ "CO_MsgCategory" BO_ 1566 405;
BA_ "CO_MsgCategory" BO_ 158 205;
BA_ "CO_MsgCategory" BO_ 1817 505;
BA_ "CO_MsgCategory" BO_ 1433 410;
BA_ "CO_MsgCategory" BO_ 1561 405;
BA_ "CO_MsgCategory" BO_ 153 205;
BA_ "CO_MsgCategory" BO_ 1816 505;
BA_ "CO_MsgCategory" BO_ 1432 410;
BA_ "CO_MsgCategory" BO_ 1560 405;
BA_ "CO_MsgCategory" BO_ 152 205;
BA_ "CO_MsgCategory" BO_ 1815 505;
BA_ "CO_MsgCategory" BO_ 1431 410;
BA_ "CO_MsgCategory" BO_ 1559 405;
BA_ "CO_MsgCategory" BO_ 151 205;
BA_ "CO_MsgCategory" BO_ 1814 505;
BA_ "CO_MsgCategory" BO_ 1430 410;
BA_ "CO_MsgCategory" BO_ 1558 405;
BA_ "CO_MsgCategory" BO_ 150 205;
BA_ "CO_MsgCategory" BO_ 1813 505;
BA_ "CO_MsgCategory" BO_ 1429 410;
BA_ "CO_MsgCategory" BO_ 1557 405;
BA_ "CO_MsgCategory" BO_ 149 205;
BA_ "CO_MsgCategory" BO_ 1812 505;
BA_ "CO_MsgCategory" BO_ 1428 410;
BA_ "CO_MsgCategory" BO_ 1556 405;
BA_ "CO_MsgCategory" BO_ 148 205;
BA_ "CO_MsgCategory" BO_ 1809 505;
BA_ "CO_MsgCategory" BO_ 1425 410;
BA_ "CO_MsgCategory" BO_ 1553 405;
BA_ "CO_MsgCategory" BO_ 145 205;
BA_ "CO_MsgCategory" BO_ 1808 505;
BA_ "CO_MsgCategory" BO_ 1424 410;
BA_ "CO_MsgCategory" BO_ 1552 405;
BA_ "CO_MsgCategory" BO_ 144 205;
BA_ "CO_MsgCategory" BO_ 1801 505;
BA_ "CO_MsgCategory" BO_ 1417 410;
BA_ "CO_MsgCategory" BO_ 1545 405;
BA_ "CO_MsgCategory" BO_ 137 205;
BA_ "CO_MsgCategory" BO_ 1800 505;
BA_ "CO_MsgCategory" BO_ 1416 410;
BA_ "CO_MsgCategory" BO_ 1544 405;
BA_ "CO_MsgCategory" BO_ 136 205;
BA_ "CO_MsgCategory" BO_ 1793 505;
BA_ "CO_MsgCategory" BO_ 1409 410;
BA_ "CO_MsgCategory" BO_ 1537 405;
BA_ "CO_MsgCategory" BO_ 129 205;
BA_ "CO_MsgCategory" BO_ 1919 505;
BA_ "CO_MsgCategory" BO_ 1535 410;
BA_ "CO_MsgCategory" BO_ 1663 405;
BA_ "CO_MsgCategory" BO_ 255 205;
BA_ "CO_MsgCategory" BO_ 1918 505;
BA_ "CO_MsgCategory" BO_ 1534 410;
BA_ "CO_MsgCategory" BO_ 1662 405;
BA_ "CO_MsgCategory" BO_ 254 205;
BA_ "CO_MsgCategory" BO_ 1917 505;
BA_ "CO_MsgCategory" BO_ 1533 410;
BA_ "CO_MsgCategory" BO_ 1661 405;
BA_ "CO_MsgCategory" BO_ 253 205;
BA_ "CO_MsgCategory" BO_ 1916 505;
BA_ "CO_MsgCategory" BO_ 1532 410;
BA_ "CO_MsgCategory" BO_ 1660 405;
BA_ "CO_MsgCategory" BO_ 252 205;
BA_ "CO_MsgCategory" BO_ 1915 505;
BA_ "CO_MsgCategory" BO_ 1531 410;
BA_ "CO_MsgCategory" BO_ 1659 405;
BA_ "CO_MsgCategory" BO_ 251 205;
BA_ "CO_MsgCategory" BO_ 1914 505;
BA_ "CO_MsgCategory" BO_ 1530 410;
BA_ "CO_MsgCategory" BO_ 1658 405;
BA_ "CO_MsgCategory" BO_ 250 205;
BA_ "CO_MsgCategory" BO_ 1913 505;
BA_ "CO_MsgCategory" BO_ 1529 410;
BA_ "CO_MsgCategory" BO_ 1657 405;
BA_ "CO_MsgCategory" BO_ 249 205;
BA_ "CO_MsgCategory" BO_ 1912 505;
BA_ "CO_MsgCategory" BO_ 1528 410;
BA_ "CO_MsgCategory" BO_ 1656 405;
BA_ "CO_MsgCategory" BO_ 248 205;
BA_ "CO_MsgCategory" BO_ 1911 505;
BA_ "CO_MsgCategory" BO_ 1527 410;
BA_ "CO_MsgCategory" BO_ 1655 405;
BA_ "CO_MsgCategory" BO_ 247 205;
BA_ "CO_MsgCategory" BO_ 1910 505;
BA_ "CO_MsgCategory" BO_ 1526 410;
BA_ "CO_MsgCategory" BO_ 1654 405;
BA_ "CO_MsgCategory" BO_ 246 205;
BA_ "CO_MsgCategory" BO_ 1909 505;
BA_ "CO_MsgCategory" BO_ 1525 410;
BA_ "CO_MsgCategory" BO_ 1653 405;
BA_ "CO_MsgCategory" BO_ 245 205;
BA_ "CO_MsgCategory" BO_ 1908 505;
BA_ "CO_MsgCategory" BO_ 1524 410;
BA_ "CO_MsgCategory" BO_ 1652 405;
BA_ "CO_MsgCategory" BO_ 244 205;
BA_ "CO_MsgCategory" BO_ 1907 505;
BA_ "CO_MsgCategory" BO_ 1523 410;
BA_ "CO_MsgCategory" BO_ 1651 405;
BA_ "CO_MsgCategory" BO_ 243 205;
BA_ "CO_MsgCategory" BO_ 1906 505;
BA_ "CO_MsgCategory" BO_ 1522 410;
BA_ "CO_MsgCategory" BO_ 1650 405;
BA_ "CO_MsgCategory" BO_ 242 205;
BA_ "CO_MsgCategory" BO_ 1905 505;
BA_ "CO_MsgCategory" BO_ 1521 410;
BA_ "CO_MsgCategory" BO_ 1649 405;
BA_ "CO_MsgCategory" BO_ 241 205;
BA_ "CO_MsgCategory" BO_ 1904 505;
BA_ "CO_MsgCategory" BO_ 1520 410;
BA_ "CO_MsgCategory" BO_ 1648 405;
BA_ "CO_MsgCategory" BO_ 240 205;
BA_ "CO_MsgCategory" BO_ 1903 505;
BA_ "CO_MsgCategory" BO_ 1519 410;
BA_ "CO_MsgCategory" BO_ 1647 405;
BA_ "CO_MsgCategory" BO_ 239 205;
BA_ "CO_MsgCategory" BO_ 1902 505;
BA_ "CO_MsgCategory" BO_ 1518 410;
BA_ "CO_MsgCategory" BO_ 1646 405;
BA_ "CO_MsgCategory" BO_ 238 205;
BA_ "CO_MsgCategory" BO_ 1901 505;
BA_ "CO_MsgCategory" BO_ 1517 410;
BA_ "CO_MsgCategory" BO_ 1645 405;
BA_ "CO_MsgCategory" BO_ 237 205;
BA_ "CO_MsgCategory" BO_ 1900 505;
BA_ "CO_MsgCategory" BO_ 1516 410;
BA_ "CO_MsgCategory" BO_ 1644 405;
BA_ "CO_MsgCategory" BO_ 236 205;
BA_ "CO_MsgCategory" BO_ 1899 505;
BA_ "CO_MsgCategory" BO_ 1515 410;
BA_ "CO_MsgCategory" BO_ 1643 405;
BA_ "CO_MsgCategory" BO_ 235 205;
BA_ "CO_MsgCategory" BO_ 1898 505;
BA_ "CO_MsgCategory" BO_ 1514 410;
BA_ "CO_MsgCategory" BO_ 1642 405;
BA_ "CO_MsgCategory" BO_ 234 205;
BA_ "CO_MsgCategory" BO_ 1897 505;
BA_ "CO_MsgCategory" BO_ 1513 410;
BA_ "CO_MsgCategory" BO_ 1641 405;
BA_ "CO_MsgCategory" BO_ 233 205;
BA_ "CO_MsgCategory" BO_ 1896 505;
BA_ "CO_MsgCategory" BO_ 1512 410;
BA_ "CO_MsgCategory" BO_ 1640 405;
BA_ "CO_MsgCategory" BO_ 232 205;
BA_ "CO_MsgCategory" BO_ 1895 505;
BA_ "CO_MsgCategory" BO_ 1511 410;
BA_ "CO_MsgCategory" BO_ 1639 405;
BA_ "CO_MsgCategory" BO_ 231 205;
BA_ "CO_MsgCategory" BO_ 1894 505;
BA_ "CO_MsgCategory" BO_ 1510 410;
BA_ "CO_MsgCategory" BO_ 1638 405;
BA_ "CO_MsgCategory" BO_ 230 205;
BA_ "CO_MsgCategory" BO_ 1893 505;
BA_ "CO_MsgCategory" BO_ 1509 410;
BA_ "CO_MsgCategory" BO_ 1637 405;
BA_ "CO_MsgCategory" BO_ 229 205;
BA_ "CO_MsgCategory" BO_ 1892 505;
BA_ "CO_MsgCategory" BO_ 1508 410;
BA_ "CO_MsgCategory" BO_ 1636 405;
BA_ "CO_MsgCategory" BO_ 228 205;
BA_ "CO_MsgCategory" BO_ 1891 505;
BA_ "CO_MsgCategory" BO_ 1507 410;
BA_ "CO_MsgCategory" BO_ 1635 405;
BA_ "CO_MsgCategory" BO_ 227 205;
BA_ "CO_MsgCategory" BO_ 1890 505;
BA_ "CO_MsgCategory" BO_ 1506 410;
BA_ "CO_MsgCategory" BO_ 1634 405;
BA_ "CO_MsgCategory" BO_ 226 205;
BA_ "CO_MsgCategory" BO_ 1889 505;
BA_ "CO_MsgCategory" BO_ 1505 410;
BA_ "CO_MsgCategory" BO_ 1633 405;
BA_ "CO_MsgCategory" BO_ 225 205;
BA_ "CO_MsgCategory" BO_ 1888 505;
BA_ "CO_MsgCategory" BO_ 1504 410;
BA_ "CO_MsgCategory" BO_ 1632 405;
BA_ "CO_MsgCategory" BO_ 224 205;
BA_ "CO_MsgCategory" BO_ 1887 505;
BA_ "CO_MsgCategory" BO_ 1503 410;
BA_ "CO_MsgCategory" BO_ 1631 405;
BA_ "CO_MsgCategory" BO_ 223 205;
BA_ "CO_MsgCategory" BO_ 1886 505;
BA_ "CO_MsgCategory" BO_ 1502 410;
BA_ "CO_MsgCategory" BO_ 1630 405;
BA_ "CO_MsgCategory" BO_ 222 205;
BA_ "CO_MsgCategory" BO_ 1885 505;
BA_ "CO_MsgCategory" BO_ 1501 410;
BA_ "CO_MsgCategory" BO_ 1629 405;
BA_ "CO_MsgCategory" BO_ 221 205;
BA_ "CO_MsgCategory" BO_ 1884 505;
BA_ "CO_MsgCategory" BO_ 1500 410;
BA_ "CO_MsgCategory" BO_ 1628 405;
BA_ "CO_MsgCategory" BO_ 220 205;
BA_ "CO_MsgCategory" BO_ 1883 505;
BA_ "CO_MsgCategory" BO_ 1499 410;
BA_ "CO_MsgCategory" BO_ 1627 405;
BA_ "CO_MsgCategory" BO_ 219 205;
BA_ "CO_MsgCategory" BO_ 1882 505;
BA_ "CO_MsgCategory" BO_ 1498 410;
BA_ "CO_MsgCategory" BO_ 1626 405;
BA_ "CO_MsgCategory" BO_ 218 205;
BA_ "CO_MsgCategory" BO_ 1881 505;
BA_ "CO_MsgCategory" BO_ 1497 410;
BA_ "CO_MsgCategory" BO_ 1625 405;
BA_ "CO_MsgCategory" BO_ 217 205;
BA_ "CO_MsgCategory" BO_ 1880 505;
BA_ "CO_MsgCategory" BO_ 1496 410;
BA_ "CO_MsgCategory" BO_ 1624 405;
BA_ "CO_MsgCategory" BO_ 216 205;
BA_ "CO_MsgCategory" BO_ 1879 505;
BA_ "CO_MsgCategory" BO_ 1495 410;
BA_ "CO_MsgCategory" BO_ 1623 405;
BA_ "CO_MsgCategory" BO_ 215 205;
BA_ "CO_MsgCategory" BO_ 1878 505;
BA_ "CO_MsgCategory" BO_ 1494 410;
BA_ "CO_MsgCategory" BO_ 1622 405;
BA_ "CO_MsgCategory" BO_ 214 205;
BA_ "CO_MsgCategory" BO_ 1877 505;
BA_ "CO_MsgCategory" BO_ 1493 410;
BA_ "CO_MsgCategory" BO_ 1621 405;
BA_ "CO_MsgCategory" BO_ 213 205;
BA_ "CO_MsgCategory" BO_ 1876 505;
BA_ "CO_MsgCategory" BO_ 1492 410;
BA_ "CO_MsgCategory" BO_ 1620 405;
BA_ "CO_MsgCategory" BO_ 212 205;
BA_ "CO_MsgCategory" BO_ 1875 505;
BA_ "CO_MsgCategory" BO_ 1491 410;
BA_ "CO_MsgCategory" BO_ 1619 405;
BA_ "CO_MsgCategory" BO_ 211 205;
BA_ "CO_MsgCategory" BO_ 1874 505;
BA_ "CO_MsgCategory" BO_ 1490 410;
BA_ "CO_MsgCategory" BO_ 1618 405;
BA_ "CO_MsgCategory" BO_ 210 205;
BA_ "CO_MsgCategory" BO_ 1873 505;
BA_ "CO_MsgCategory" BO_ 1489 410;
BA_ "CO_MsgCategory" BO_ 1617 405;
BA_ "CO_MsgCategory" BO_ 209 205;
BA_ "CO_MsgCategory" BO_ 1872 505;
BA_ "CO_MsgCategory" BO_ 1488 410;
BA_ "CO_MsgCategory" BO_ 1616 405;
BA_ "CO_MsgCategory" BO_ 208 205;
BA_ "CO_MsgCategory" BO_ 1871 505;
BA_ "CO_MsgCategory" BO_ 1487 410;
BA_ "CO_MsgCategory" BO_ 1615 405;
BA_ "CO_MsgCategory" BO_ 207 205;
BA_ "CO_MsgCategory" BO_ 1870 505;
BA_ "CO_MsgCategory" BO_ 1486 410;
BA_ "CO_MsgCategory" BO_ 1614 405;
VAL_ 1827 State 127 "PreOperational" 5 "Operational" 4 "Stopped" 0 "Bootup" ;
VAL_ 1443 SCS 2 "Upload" 1 "Download" ;
VAL_ 1571 CCS 2 "Upload" 1 "Download" ;
VAL_ 163 ErrorCode 33360 "RPDO timeout" 33344 "Unexpected SYNC data length" 33328 "DAM MPDO not processed, destination object not available" 33312 "PDO length exceeded" 33296 "PDO not processed due to length error" 33104 "Transmit COB-ID collision" 33088 "Recovered from bus off state" 33072 "Life guard error or heartbeat error" 33056 "CAN in error passive mode" 33040 "CAN overrun (objects lost)" ;
VAL_ 1826 State 127 "PreOperational" 5 "Operational" 4 "Stopped" 0 "Bootup" ;
VAL_ 1442 SCS 2 "Upload" 1 "Download" ;
VAL_ 1570 CCS 2 "Upload" 1 "Download" ;
VAL_ 162 ErrorCode 33360 "RPDO timeout" 33344 "Unexpected SYNC data length" 33328 "DAM MPDO not processed, destination object not available" 33312 "PDO length exceeded" 33296 "PDO not processed due to length error" 33104 "Transmit COB-ID collision" 33088 "Recovered from bus off state" 33072 "Life guard error or heartbeat error" 33056 "CAN in error passive mode" 33040 "CAN overrun (objects lost)" ;
VAL_ 1825 State 127 "PreOperational" 5 "Operational" 4 "Stopped" 0 "Bootup" ;
VAL_ 1441 SCS 2 "Upload" 1 "Download" ;
VAL_ 1569 CCS 2 "Upload" 1 "Download" ;
VAL_ 161 ErrorCode 33360 "RPDO timeout" 33344 "Unexpected SYNC data length" 33328 "DAM MPDO not processed, destination object not available" 33312 "PDO length exceeded" 33296 "PDO not processed due to length error" 33104 "Transmit COB-ID collision" 33088 "Recovered from bus off state" 33072 "Life guard error or heartbeat error" 33056 "CAN in error passive mode" 33040 "CAN overrun (objects lost)" ;
VAL_ 1824 State 127 "PreOperational" 5 "Operational" 4 "Stopped" 0 "Bootup" ;
VAL_ 1440 SCS 2 "Upload" 1 "Download" ;
VAL_ 1568 CCS 2 "Upload" 1 "Download" ;
VAL_ 160 ErrorCode 33360 "RPDO timeout" 33344 "Unexpected SYNC data length" 33328 "DAM MPDO not processed, destination object not available" 33312 "PDO length exceeded" 33296 "PDO not processed due to length error" 33104 "Transmit COB-ID collision" 33088 "Recovered from bus off state" 33072 "Life guard error or heartbeat error" 33056 "CAN in error passive mode" 33040 "CAN overrun (objects lost)" ;
VAL_ 1823 State 127 "PreOperational" 5 "Operational" 4 "Stopped" 0 "Bootup" ;
VAL_ 1439 SCS 2 "Upload" 1 "Download" ;
VAL_ 1567 CCS 2 "Upload" 1 "Download" ;
VAL_ 159 ErrorCode 33360 "RPDO timeout" 33344 "Unexpected SYNC data length" 33328 "DAM MPDO not processed, destination object not available" 33312 "PDO length exceeded" 33296 "PDO not processed due to length error" 33104 "Transmit COB-ID collision" 33088 "Recovered from bus off state" 33072 "Life guard error or heartbeat error" 33056 "CAN in error passive mode" 33040 "CAN overrun (objects lost)" ;
VAL_ 1822 State 127 "PreOperational" 5 "Operational" 4 "Stopped" 0 "Bootup" ;
VAL_ 1438 SCS 2 "Upload" 1 "Download" ;
VAL_ 1566 CCS 2 "Upload" 1 "Download" ;
VAL_ 158 ErrorCode 33360 "RPDO timeout" 33344 "Unexpected SYNC data length" 33328 "DAM MPDO not processed, destination object not available" 33312 "PDO length exceeded" 33296 "PDO not processed due to length error" 33104 "Transmit COB-ID collision" 33088 "Recovered from bus off state" 33072 "Life guard error or heartbeat error" 33056 "CAN in error passive mode" 33040 "CAN overrun (objects lost)" ;
VAL_ 1817 State 127 "PreOperational" 5 "Operational" 4 "Stopped" 0 "Bootup" ;
VAL_ 1433 SCS 2 "Upload" 1 "Download" ;
VAL_ 1561 CCS 2 "Upload" 1 "Download" ;
VAL_ 153 ErrorCode 33360 "RPDO timeout" 33344 "Unexpected SYNC data length" 33328 "DAM MPDO not processed, destination object not available" 33312 "PDO length exceeded" 33296 "PDO not processed due to length error" 33104 "Transmit COB-ID collision" 33088 "Recovered from bus off state" 33072 "Life guard error or heartbeat error" 33056 "CAN in error passive mode" 33040 "CAN overrun (objects lost)" ;
VAL_ 1816 State 127 "PreOperational" 5 "Operational" 4 "Stopped" 0 "Bootup" ;
VAL_ 1432 SCS 2 "Upload" 1 "Download" ;
VAL_ 1560 CCS 2 "Upload" 1 "Download" ;
VAL_ 152 ErrorCode 33360 "RPDO timeout" 33344 "Unexpected SYNC data length" 33328 "DAM MPDO not processed, destination object not available" 33312 "PDO length exceeded" 33296 "PDO not processed due to length error" 33104 "Transmit COB-ID collision" 33088 "Recovered from bus off state" 33072 "Life guard error or heartbeat error" 33056 "CAN in error passive mode" 33040 "CAN overrun (objects lost)" ;
VAL_ 1815 State 127 "PreOperational" 5 "Operational" 4 "Stopped" 0 "Bootup" ;
VAL_ 1431 SCS 2 "Upload" 1 "Download" ;
VAL_ 1559 CCS 2 "Upload" 1 "Download" ;
VAL_ 151 ErrorCode 33360 "RPDO timeout" 33344 "Unexpected SYNC data length" 33328 "DAM MPDO not processed, destination object not available" 33312 "PDO length exceeded" 33296 "PDO not processed due to length error" 33104 "Transmit COB-ID collision" 33088 "Recovered from bus off state" 33072 "Life guard error or heartbeat error" 33056 "CAN in error passive mode" 33040 "CAN overrun (objects lost)" ;
VAL_ 1814 State 127 "PreOperational" 5 "Operational" 4 "Stopped" 0 "Bootup" ;
VAL_ 1430 SCS 2 "Upload" 1 "Download" ;
VAL_ 1558 CCS 2 "Upload" 1 "Download" ;
VAL_ 150 ErrorCode 33360 "RPDO timeout" 33344 "Unexpected SYNC data length" 33328 "DAM MPDO not processed, destination object not available" 33312 "PDO length exceeded" 33296 "PDO not processed due to length error" 33104 "Transmit COB-ID collision" 33088 "Recovered from bus off state" 33072 "Life guard error or heartbeat error" 33056 "CAN in error passive mode" 33040 "CAN overrun (objects lost)" ;
VAL_ 1813 State 127 "PreOperational" 5 "Operational" 4 "Stopped" 0 "Bootup" ;
VAL_ 1429 SCS 2 "Upload" 1 "Download" ;
VAL_ 1557 CCS 2 "Upload" 1 "Download" ;
VAL_ 149 ErrorCode 33360 "RPDO timeout" 33344 "Unexpected SYNC data length" 33328 "DAM MPDO not processed, destination object not available" 33312 "PDO length exceeded" 33296 "PDO not processed due to length error" 33104 "Transmit COB-ID collision" 33088 "Recovered from bus off state" 33072 "Life guard error or heartbeat error" 33056 "CAN in error passive mode" 33040 "CAN overrun (objects lost)" ;
VAL_ 1812 State 127 "PreOperational" 5 "Operational" 4 "Stopped" 0 "Bootup" ;
VAL_ 1428 SCS 2 "Upload" 1 "Download" ;
VAL_ 1556 CCS 2 "Upload" 1 "Download" ;
VAL_ 148 ErrorCode 33360 "RPDO timeout" 33344 "Unexpected SYNC data length" 33328 "DAM MPDO not processed, destination object not available" 33312 "PDO length exceeded" 33296 "PDO not processed due to length error" 33104 "Transmit COB-ID collision" 33088 "Recovered from bus off state" 33072 "Life guard error or heartbeat error" 33056 "CAN in error passive mode" 33040 "CAN overrun (objects lost)" ;
VAL_ 1809 State 127 "PreOperational" 5 "Operational" 4 "Stopped" 0 "Bootup" ;
VAL_ 1425 SCS 2 "Upload" 1 "Download" ;
VAL_ 1553 CCS 2 "Upload" 1 "Download" ;
VAL_ 145 ErrorCode 33360 "RPDO timeout" 33344 "Unexpected SYNC data length" 33328 "DAM MPDO not processed, destination object not available" 33312 "PDO length exceeded" 33296 "PDO not processed due to length error" 33104 "Transmit COB-ID collision" 33088 "Recovered from bus off state" 33072 "Life guard error or heartbeat error" 33056 "CAN in error passive mode" 33040 "CAN overrun (objects lost)" ;
VAL_ 1808 State 127 "PreOperational" 5 "Operational" 4 "Stopped" 0 "Bootup" ;
VAL_ 1424 SCS 2 "Upload" 1 "Download" ;
VAL_ 1552 CCS 2 "Upload" 1 "Download" ;
VAL_ 144 ErrorCode 33360 "RPDO timeout" 33344 "Unexpected SYNC data length" 33328 "DAM MPDO not processed, destination object not available" 33312 "PDO length exceeded" 33296 "PDO not processed due to length error" 33104 "Transmit COB-ID collision" 33088 "Recovered from bus off state" 33072 "Life guard error or heartbeat error" 33056 "CAN in error passive mode" 33040 "CAN overrun (objects lost)" ;
VAL_ 1801 State 127 "PreOperational" 5 "Operational" 4 "Stopped" 0 "Bootup" ;
VAL_ 1417 SCS 2 "Upload" 1 "Download" ;
VAL_ 1545 CCS 2 "Upload" 1 "Download" ;
VAL_ 137 ErrorCode 33360 "RPDO timeout" 33344 "Unexpected SYNC data length" 33328 "DAM MPDO not processed, destination object not available" 33312 "PDO length exceeded" 33296 "PDO not processed due to length error" 33104 "Transmit COB-ID collision" 33088 "Recovered from bus off state" 33072 "Life guard error or heartbeat error" 33056 "CAN in error passive mode" 33040 "CAN overrun (objects lost)" ;
VAL_ 1800 State 127 "PreOperational" 5 "Operational" 4 "Stopped" 0 "Bootup" ;
VAL_ 1416 SCS 2 "Upload" 1 "Download" ;
VAL_ 1544 CCS 2 "Upload" 1 "Download" ;
VAL_ 136 ErrorCode 33360 "RPDO timeout" 33344 "Unexpected SYNC data length" 33328 "DAM MPDO not processed, destination object not available" 33312 "PDO length exceeded" 33296 "PDO not processed due to length error" 33104 "Transmit COB-ID collision" 33088 "Recovered from bus off state" 33072 "Life guard error or heartbeat error" 33056 "CAN in error passive mode" 33040 "CAN overrun (objects lost)" ;
VAL_ 1793 State 127 "PreOperational" 5 "Operational" 4 "Stopped" 0 "Bootup" ;
VAL_ 1409 SCS 2 "Upload" 1 "Download" ;
VAL_ 1537 CCS 2 "Upload" 1 "Download" ;
VAL_ 129 ErrorCode 61444 "(DS-402) Control error" 61443 "(DS-402) Control, stroke operation" 61442 "(DS-402) Control, sub-synchronous run" 61441 "(DS-402) Control, deceleration" 35072 "(DS-402) Winding controller - process data monitoring" 34816 "(DS-402) Winding controller" 34560 "(DS-402) Sync controller" 34322 "(DS-402) Positioning - reference limit" 34321 "(DS-402) Positioning - following error" 34304 "(DS-402) Positioning controller" 34048 "(DS-402) Position controller" 33792 "(DS-402) Velocity speed controller" 33585 "(DS-402) Torque fault" 33569 "(DS-402) Insufficient torque" 33555 "(DS-402) Standstill torque" 33554 "(DS-402) Difficult start up" 33553 "(DS-402) Excess torque" 33536 "(DS-402) Torque control" 30208 "(DS-402) Data storage (external)" 29984 "(DS-402) Serial interface no. 2" 29968 "(DS-402) Serial interface no. 1" 29952 "(DS-402) Communication" 29696 "(DS-402) Computation circuit" 29472 "(DS-402) Position" 29456 "(DS-402) Speed" 29447 "(DS-402) Incremental sensor 3 fault" 29446 "(DS-402) Incremental sensor 2 fault" 29445 "(DS-402) Incremental sensor 1 fault" 29444 "(DS-402) Resolver 2 fault" 29443 "(DS-402) Resolver 1 fault" 29442 "(DS-402) Tacho wrong polarity" 29441 "(DS-402) Tacho fault" 29440 "(DS-402) Sensor" 29184 "(DS-402) Measurement circuit  " 28963 "(DS-402) Motor tilted" 28962 "(DS-402) Motor error or commutation malfunction" 28961 "(DS-402) Motor blocked" 28960 "(DS-402) Motor" 28947 "(DS-402) Protective circuit brake chopper" 28946 "(DS-402) Over current brake chopper" 28945 "(DS-402) Failure brake chopper" 28944 "(DS-402) Brake chopper" 28928 "(DS-402) Power" 25376 "(DS-402) Parameter error" 25360 "(DS-402) Loss of parameters" 25359 "(DS-402) Reset watchdog - data record no. 15" 25358 "(DS-402) Reset watchdog - data record no. 14" 25357 "(DS-402) Reset watchdog - data record no. 13" 25356 "(DS-402) Reset watchdog - data record no. 12" 25355 "(DS-402) Reset watchdog - data record no. 11" 25354 "(DS-402) Reset watchdog - data record no. 10" 25353 "(DS-402) Reset watchdog - data record no. 9" 25352 "(DS-402) Reset watchdog - data record no. 8" 25351 "(DS-402) Reset watchdog - data record no. 7" 25350 "(DS-402) Reset watchdog - data record no. 6" 25349 "(DS-402) Reset watchdog - data record no. 5" 25348 "(DS-402) Reset watchdog - data record no. 4" 25347 "(DS-402) Reset watchdog - data record no. 3" 25346 "(DS-402) Reset watchdog - data record no. 2" 25345 "(DS-402) Reset watchdog - data record no. 1" 24592 "(DS-402) Software reset (watchdog)" 21808 "(DS-402) EEPROM" 21792 "(DS-402) ROM/EPROM" 21776 "(DS-402) RAM" 21760 "(DS-402) Hardware memory" 21593 "(DS-402) Fuses S9 = manufacturer-specific" 21592 "(DS-402) Fuses S8 = manufacturer-specific" 21591 "(DS-402) Fuses S7 = manufacturer-specific" 21590 "(DS-402) Fuses S6 = manufacturer-specific" 21589 "(DS-402) Fuses S5 = manufacturer-specific" 21588 "(DS-402) Fuses S4 = manufacturer-specific" 21587 "(DS-402) Fuses S3 = l3" 21586 "(DS-402) Fuses S2 = l2" 21585 "(DS-402) Fuses S1 = l1" 21584 "(DS-402) Fuses" 21573 "(DS-402) Contact 5 = manufacturer-specific" 21572 "(DS-402) Contact 4 = manufacturer-specific" 21571 "(DS-402) Contact 3 = manufacturer-specific" 21570 "(DS-402) Contact 2 = manufacturer-specific" 21569 "(DS-402) Contact 1 = manufacturer-specific" 21568 "(DS-402) Contacts" 21552 "(DS-402) Input stages" 21536 "(DS-402) Chopper" 21520 "(DS-402) Output stages" 21504 "(DS-402) Power section" 21248 "(DS-402) Operating unit" 21024 "(DS-402) Control, computing circuit" 21008 "(DS-402) Control, measurement circuit" 35328 "(DS-402) Control" 20768 "(DS-402) Supply intermediate circuit" 20761 "(DS-402) Supply low voltage U9 = manufacturer-specific" 20760 "(DS-402) Supply low voltage U8 = manufacturer-specific" 20759 "(DS-402) Supply low voltage U7 = manufacturer-specific" 20758 "(DS-402) Supply low voltage U6 = manufacturer-specific" 20757 "(DS-402) Supply low voltage U5 = manufacturer-specific" 20756 "(DS-402) Supply low voltage U4 = manufacturer-specific" 20755 "(DS-402) Supply low voltage U3 = supply +5 V" 20754 "(DS-402) Supply low voltage U2 = supply +24V" 20753 "(DS-402) Supply low voltage U1 = supply ±15V" 20752 "(DS-402) Supply low voltage" 20736 "(DS-402) Supply" 17440 "(DS-402) Too low temperature supply" 17424 "(DS-402) Excess temperature supply" 17408 "(DS-402) Temperature supply" 17184 "(DS-402) Too low temperature drive" 17168 "(DS-402) Excess temperature drive" 17152 "(DS-402) Temperature drive" 16928 "(DS-402) Field circ. interrupted, too low temperature device" 16912 "(DS-402) Field circ. interrupted, excess temperature device" 16704 "(DS-402) Field circ. interrupted, temperature air outlet" 16688 "(DS-402) Field circ. interrupted, temperature supply air" 16672 "(DS-402) Field circ. interrupted, too low ambient temperature" 16656 "(DS-402) Field circ. interrupted, Excess ambient temperature" 13105 "(DS-402) Field circuit interrupted" 13104 "(DS-402) Field circuit" 13089 "(DS-402) Armature circuit interrupted" 13088 "(DS-402) Armature circuit" 13075 "(DS-402) Output over-voltage phase W " 13074 "(DS-402) Output over-voltage phase V " 13073 "(DS-402) Output over-voltage phase U " 13072 "(DS-402) Output over-voltage" 12848 "(DS-402) Load error" 12834 "(DS-402) DC link under-voltage no. 2" 12833 "(DS-402) DC link under-voltage no. 1" 12832 "(DS-402) DC link under-voltage" 12818 "(DS-402) DC link over voltage no. 2" 12817 "(DS-402) DC link over-voltage no. 1" 12816 "(DS-402) DC link over-voltage" 12610 "(DS-402) Mains frequency too small" 12609 "(DS-402) Mains frequency too great" 12608 "(DS-402) Mains frequency" 12596 "(DS-402) Phase sequence" 12595 "(DS-402) Phase failure L3" 12594 "(DS-402) Phase failure L2" 12593 "(DS-402) Phase failure L1" 12592 "(DS-402) Phase failure" 12579 "(DS-402) Mains under-voltage phase L3" 12578 "(DS-402) Mains under-voltage phase L2" 12577 "(DS-402) Mains under-voltage phase L1" 12576 "(DS-402) Mains under-voltage" 12563 "(DS-402) Mains over-voltage phase L3 " 12562 "(DS-402) Mains over-voltage phase L2" 12561 "(DS-402) Mains over-voltage phase L1" 12560 "(DS-402) Mains over-voltage" 9041 "(DS-402) Load level warning (I2t, thermal state)" 9040 "(DS-402) Load level fault (I2t, thermal state)" 9027 "(DS-402) Earth leakage (motor-side) phase W-U" 9026 "(DS-402) Earth leakage (motor-side) phase V-W" 9025 "(DS-402) Short circuit (motor-side) phases U-V" 9024 "(DS-402) Short circuit (motor-side)" 9011 "(DS-402) Earth leakage (motor-side) phase W" 9010 "(DS-402) Earth leakage (motor-side) phase V" 9009 "(DS-402) Earth leakage (motor-side) phase U" 9008 "(DS-402) Earth leakage (motor-side)" 8992 "(DS-402) Short circuit/earth leakage (motor-side)" 8978 "(DS-402) Device internal, continuous over current no. 2" 8977 "(DS-402) Device internal, continuous over current no. 1" 8976 "(DS-402) Device internal, continuous over current" 8784 "(DS-402) Short circuit (device internal) " 8768 "(DS-402) Earth leakage (device internal)" 8752 "(DS-402) Short circuit/earth leakage (device internal)" 8738 "(DS-402) Continuous over current no.2" 8737 "(DS-402) Continuous over current no.1" 8736 "(DS-402) Continuous over current (device internal)" 8724 "(DS-402) Short circuit (input), over-current in the sequence" 8723 "(DS-402) Short circuit (input), over-current in ramp function" 8722 "(DS-402) Short circuit (input), internal current no.2" 8721 "(DS-402) Short circuit (input), internal current no.1" 8499 "(DS-402) Short circuit phases (input) L3-L1" 8498 "(DS-402) Short circuit phases (input) L2-L3" 8497 "(DS-402) Short circuit phases (input) L1-L2" 8496 "(DS-402) Short circuit (input)" 8483 "(DS-402) Earth leakage (input) phase L3" 8482 "(DS-402) Earth leakage (input) phase L2" 8481 "(DS-402) Earth leakage (input) phase L1" 8480 "(DS-402) Earth leakage (input)" 8464 "(DS-402) Short circuit/earth leakage (input)" 33360 "RPDO timeout" 33344 "Unexpected SYNC data length" 33328 "DAM MPDO not processed, destination object not available" 33312 "PDO length exceeded" 33296 "PDO not processed due to length error" 33104 "Transmit COB-ID collision" 33088 "Recovered from bus off state" 33072 "Life guard error or heartbeat error" 33056 "CAN in error passive mode" 33040 "CAN overrun (objects lost)" ;
VAL_ 1919 State 127 "PreOperational" 5 "Operational" 4 "Stopped" 0 "Bootup" ;
VAL_ 1918 State 127 "PreOperational" 5 "Operational" 4 "Stopped" 0 "Bootup" ;
VAL_ 1917 State 127 "PreOperational" 5 "Operational" 4 "Stopped" 0 "Bootup" ;
VAL_ 1916 State 127 "PreOperational" 5 "Operational" 4 "Stopped" 0 "Bootup" ;
VAL_ 1915 State 127 "PreOperational" 5 "Operational" 4 "Stopped" 0 "Bootup" ;
VAL_ 1914 State 127 "PreOperational" 5 "Operational" 4 "Stopped" 0 "Bootup" ;
VAL_ 1913 State 127 "PreOperational" 5 "Operational" 4 "Stopped" 0 "Bootup" ;
VAL_ 1912 State 127 "PreOperational" 5 "Operational" 4 "Stopped" 0 "Bootup" ;
VAL_ 1911 State 127 "PreOperational" 5 "Operational" 4 "Stopped" 0 "Bootup" ;
VAL_ 1910 State 127 "PreOperational" 5 "Operational" 4 "Stopped" 0 "Bootup" ;
VAL_ 1909 State 127 "PreOperational" 5 "Operational" 4 "Stopped" 0 "Bootup" ;
VAL_ 1908 State 127 "PreOperational" 5 "Operational" 4 "Stopped" 0 "Bootup" ;
VAL_ 1907 State 127 "PreOperational" 5 "Operational" 4 "Stopped" 0 "Bootup" ;
VAL_ 1906 State 127 "PreOperational" 5 "Operational" 4 "Stopped" 0 "Bootup" ;
VAL_ 1905 State 127 "PreOperational" 5 "Operational" 4 "Stopped" 0 "Bootup" ;
VAL_ 1904 State 127 "PreOperational" 5 "Operational" 4 "Stopped" 0 "Bootup" ;
VAL_ 1903 State 127 "PreOperational" 5 "Operational" 4 "Stopped" 0 "Bootup" ;
VAL_ 1902 State 127 "PreOperational" 5 "Operational" 4 "Stopped" 0 "Bootup" ;
VAL_ 1901 State 127 "PreOperational" 5 "Operational" 4 "Stopped" 0 "Bootup" ;
VAL_ 1900 State 127 "PreOperational" 5 "Operational" 4 "Stopped" 0 "Bootup" ;
VAL_ 1899 State 127 "PreOperational" 5 "Operational" 4 "Stopped" 0 "Bootup" ;
VAL_ 1898 State 127 "PreOperational" 5 "Operational" 4 "Stopped" 0 "Bootup" ;
VAL_ 1897 State 127 "PreOperational" 5 "Operational" 4 "Stopped" 0 "Bootup" ;
VAL_ 1896 State 127 "PreOperational" 5 "Operational" 4 "Stopped" 0 "Bootup" ;
VAL_ 1895 State 127 "PreOperational" 5 "Operational" 4 "Stopped" 0 "Bootup" ;
VAL_ 1894 State 127 "PreOperational" 5 "Operational" 4 "Stopped" 0 "Bootup" ;
VAL_ 1893 State 127 "PreOperational" 5 "Operational" 4 "Stopped" 0 "Bootup" ;
VAL_ 1892 State 127 "PreOperational" 5 "Operational" 4 "Stopped" 0 "Bootup" ;
VAL_ 1891 State 127 "PreOperational" 5 "Operational" 4 "Stopped" 0 "Bootup" ;
VAL_ 1890 State 127 "PreOperational" 5 "Operational" 4 "Stopped" 0 "Bootup" ;
VAL_ 1889 State 127 "PreOperational" 5 "Operational" 4 "Stopped" 0 "Bootup" ;
VAL_ 1888 State 127 "PreOperational" 5 "Operational" 4 "Stopped" 0 "Bootup" ;
VAL_ 1887 State 127 "PreOperational" 5 "Operational" 4 "Stopped" 0 "Bootup" ;
VAL_ 1886 State 127 "PreOperational" 5 "Operational" 4 "Stopped" 0 "Bootup" ;
VAL_ 1885 State 127 "PreOperational" 5 "Operational" 4 "Stopped" 0 "Bootup" ;
VAL_ 1884 State 127 "PreOperational" 5 "Operational" 4 "Stopped" 0 "Bootup" ;
VAL_ 1883 State 127 "PreOperational" 5 "Operational" 4 "Stopped" 0 "Bootup" ;
VAL_ 1882 State 127 "PreOperational" 5 "Operational" 4 "Stopped" 0 "Bootup" ;
VAL_ 1881 State 127 "PreOperational" 5 "Operational" 4 "Stopped" 0 "Bootup" ;
VAL_ 1880 State 127 "PreOperational" 5 "Operational" 4 "Stopped" 0 "Bootup" ;
VAL_ 1879 State 127 "PreOperational" 5 "Operational" 4 "Stopped" 0 "Bootup" ;
VAL_ 1878 State 127 "PreOperational" 5 "Operational" 4 "Stopped" 0 "Bootup" ;
VAL_ 1877 State 127 "PreOperational" 5 "Operational" 4 "Stopped" 0 "Bootup" ;
VAL_ 1876 State 127 "PreOperational" 5 "Operational" 4 "Stopped" 0 "Bootup" ;
VAL_ 1875 State 127 "PreOperational" 5 "Operational" 4 "Stopped" 0 "Bootup" ;
VAL_ 1874 State 127 "PreOperational" 5 "Operational" 4 "Stopped" 0 "Bootup" ;
VAL_ 1873 State 127 "PreOperational" 5 "Operational" 4 "Stopped" 0 "Bootup" ;
VAL_ 1872 State 127 "PreOperational" 5 "Operational" 4 "Stopped" 0 "Bootup" ;
VAL_ 1871 State 127 "PreOperational" 5 "Operational" 4 "Stopped" 0 "Bootup" ;
VAL_ 1870 State 127 "PreOperational" 5 "Operational" 4 "Stopped" 0 "Bootup" ;
